VERSION ""

NS_ :

BS_:

BU_:

BO_ 2365401598 EJM7: 8 Vector__XXX
 SG_ Joystick7Button13PressedStatus : 62|2@1+ (1,0) [0|3] "" Vector__XXX
 SG_ Joystick7Button14PressedStatus : 60|2@1+ (1,0) [0|3] "" Vector__XXX
 SG_ Joystick7Button15PressedStatus : 58|2@1+ (1,0) [0|3] "" Vector__XXX
 SG_ Joystick7Button16PressedStatus : 56|2@1+ (1,0) [0|3] "" Vector__XXX
 SG_ Joystick7GripXAxisPosition : 6|10@1+ (0.1,0) [0|102] "%" Vector__XXX
 SG_ Joystick7GripYAxisPosition : 22|10@1+ (0.1,0) [0|102] "%" Vector__XXX
 SG_ Joystick7ThetaAxisPosition : 38|10@1+ (0.1,0) [0|102] "%" Vector__XXX
 SG_ Jst7GpYAxsLvFwdPstvPstStts : 20|2@1+ (1,0) [0|3] "" Vector__XXX
 SG_ Jst7TtAxsCtCwsNtvPstStts : 34|2@1+ (1,0) [0|3] "" Vector__XXX
 SG_ Jstk7GrpXAxsDtntPstnStts : 54|2@1+ (1,0) [0|3] "" Vector__XXX
 SG_ Jstk7GrpXAxsLvrLftNgtvPstnStts : 2|2@1+ (1,0) [0|3] "" Vector__XXX
 SG_ Jstk7GrpXAxsLvrRghtPstvPstnStts : 4|2@1+ (1,0) [0|3] "" Vector__XXX
 SG_ Jstk7GrpXAxsNtrlPstnStts : 0|2@1+ (1,0) [0|3] "" Vector__XXX
 SG_ Jstk7GrpYAxsDtntPstnStts : 52|2@1+ (1,0) [0|3] "" Vector__XXX
 SG_ Jstk7GrpYAxsLvrBkNgtvPstnStts : 18|2@1+ (1,0) [0|3] "" Vector__XXX
 SG_ Jstk7GrpYAxsNtrlPstnStts : 16|2@1+ (1,0) [0|3] "" Vector__XXX
 SG_ Jstk7ThtAxsClkwsPstvPstnStts : 36|2@1+ (1,0) [0|3] "" Vector__XXX
 SG_ Jstk7ThtAxsDtntPstnStts : 50|2@1+ (1,0) [0|3] "" Vector__XXX
 SG_ Jstk7ThtAxsNtrlPstnStts : 32|2@1+ (1,0) [0|3] "" Vector__XXX

BO_ 2365401854 BJM7: 8 Vector__XXX
 SG_ Joystick7Button10PressedStatus : 60|2@1+ (1,0) [0|3] "" Vector__XXX
 SG_ Joystick7Button11PressedStatus : 58|2@1+ (1,0) [0|3] "" Vector__XXX
 SG_ Joystick7Button12PressedStatus : 56|2@1+ (1,0) [0|3] "" Vector__XXX
 SG_ Joystick7Button1PressedStatus : 46|2@1+ (1,0) [0|3] "" Vector__XXX
 SG_ Joystick7Button2PressedStatus : 44|2@1+ (1,0) [0|3] "" Vector__XXX
 SG_ Joystick7Button3PressedStatus : 42|2@1+ (1,0) [0|3] "" Vector__XXX
 SG_ Joystick7Button4PressedStatus : 40|2@1+ (1,0) [0|3] "" Vector__XXX
 SG_ Joystick7Button5PressedStatus : 54|2@1+ (1,0) [0|3] "" Vector__XXX
 SG_ Joystick7Button6PressedStatus : 52|2@1+ (1,0) [0|3] "" Vector__XXX
 SG_ Joystick7Button7PressedStatus : 50|2@1+ (1,0) [0|3] "" Vector__XXX
 SG_ Joystick7Button8PressedStatus : 48|2@1+ (1,0) [0|3] "" Vector__XXX
 SG_ Joystick7Button9PressedStatus : 62|2@1+ (1,0) [0|3] "" Vector__XXX
 SG_ Joystick7XAxisPosition : 6|10@1+ (0.1,0) [0|102] "%" Vector__XXX
 SG_ Joystick7YAxisPosition : 22|10@1+ (0.1,0) [0|102] "%" Vector__XXX
 SG_ Jstk7XAxsDtntPstnStts : 38|2@1+ (1,0) [0|3] "" Vector__XXX
 SG_ Jstk7XAxsLvrLftNgtvPstnStts : 2|2@1+ (1,0) [0|3] "" Vector__XXX
 SG_ Jstk7XAxsLvrRghtPstvPstnStts : 4|2@1+ (1,0) [0|3] "" Vector__XXX
 SG_ Jstk7XAxsNtrlPstnStts : 0|2@1+ (1,0) [0|3] "" Vector__XXX
 SG_ Jstk7YAxsDtntPstnStts : 36|2@1+ (1,0) [0|3] "" Vector__XXX
 SG_ Jstk7YAxsLvrBkNgtvPstnStts : 18|2@1+ (1,0) [0|3] "" Vector__XXX
 SG_ Jstk7YAxsLvrFrwrdPstvPstnStts : 20|2@1+ (1,0) [0|3] "" Vector__XXX
 SG_ Jstk7YAxsNtrlPstnStts : 16|2@1+ (1,0) [0|3] "" Vector__XXX

BO_ 2365402110 EJM6: 8 Vector__XXX
 SG_ Joystick6Button13PressedStatus : 62|2@1+ (1,0) [0|3] "" Vector__XXX
 SG_ Joystick6Button14PressedStatus : 60|2@1+ (1,0) [0|3] "" Vector__XXX
 SG_ Joystick6Button15PressedStatus : 58|2@1+ (1,0) [0|3] "" Vector__XXX
 SG_ Joystick6Button16PressedStatus : 56|2@1+ (1,0) [0|3] "" Vector__XXX
 SG_ Joystick6GripXAxisPosition : 6|10@1+ (0.1,0) [0|102] "%" Vector__XXX
 SG_ Joystick6GripYAxisPosition : 22|10@1+ (0.1,0) [0|102] "%" Vector__XXX
 SG_ Joystick6ThetaAxisPosition : 38|10@1+ (0.1,0) [0|102] "%" Vector__XXX
 SG_ Jst6GpYAxsLvFwdPstvPstStts : 20|2@1+ (1,0) [0|3] "" Vector__XXX
 SG_ Jst6TtAxsCtCwsNtvPstStts : 34|2@1+ (1,0) [0|3] "" Vector__XXX
 SG_ Jstk6GrpXAxsDtntPstnStts : 54|2@1+ (1,0) [0|3] "" Vector__XXX
 SG_ Jstk6GrpXAxsLvrLftNgtvPstnStts : 2|2@1+ (1,0) [0|3] "" Vector__XXX
 SG_ Jstk6GrpXAxsLvrRghtPstvPstnStts : 4|2@1+ (1,0) [0|3] "" Vector__XXX
 SG_ Jstk6GrpXAxsNtrlPstnStts : 0|2@1+ (1,0) [0|3] "" Vector__XXX
 SG_ Jstk6GrpYAxsDtntPstnStts : 52|2@1+ (1,0) [0|3] "" Vector__XXX
 SG_ Jstk6GrpYAxsLvrBkNgtvPstnStts : 18|2@1+ (1,0) [0|3] "" Vector__XXX
 SG_ Jstk6GrpYAxsNtrlPstnStts : 16|2@1+ (1,0) [0|3] "" Vector__XXX
 SG_ Jstk6ThtAxsClkwsPstvPstnStts : 36|2@1+ (1,0) [0|3] "" Vector__XXX
 SG_ Jstk6ThtAxsDtntPstnStts : 50|2@1+ (1,0) [0|3] "" Vector__XXX
 SG_ Jstk6ThtAxsNtrlPstnStts : 32|2@1+ (1,0) [0|3] "" Vector__XXX

BO_ 2365402366 BJM6: 8 Vector__XXX
 SG_ Joystick6Button10PressedStatus : 60|2@1+ (1,0) [0|3] "" Vector__XXX
 SG_ Joystick6Button11PressedStatus : 58|2@1+ (1,0) [0|3] "" Vector__XXX
 SG_ Joystick6Button12PressedStatus : 56|2@1+ (1,0) [0|3] "" Vector__XXX
 SG_ Joystick6Button1PressedStatus : 46|2@1+ (1,0) [0|3] "" Vector__XXX
 SG_ Joystick6Button2PressedStatus : 44|2@1+ (1,0) [0|3] "" Vector__XXX
 SG_ Joystick6Button3PressedStatus : 42|2@1+ (1,0) [0|3] "" Vector__XXX
 SG_ Joystick6Button4PressedStatus : 40|2@1+ (1,0) [0|3] "" Vector__XXX
 SG_ Joystick6Button5PressedStatus : 54|2@1+ (1,0) [0|3] "" Vector__XXX
 SG_ Joystick6Button6PressedStatus : 52|2@1+ (1,0) [0|3] "" Vector__XXX
 SG_ Joystick6Button7PressedStatus : 50|2@1+ (1,0) [0|3] "" Vector__XXX
 SG_ Joystick6Button8PressedStatus : 48|2@1+ (1,0) [0|3] "" Vector__XXX
 SG_ Joystick6Button9PressedStatus : 62|2@1+ (1,0) [0|3] "" Vector__XXX
 SG_ Joystick6XAxisPosition : 6|10@1+ (0.1,0) [0|102] "%" Vector__XXX
 SG_ Joystick6YAxisPosition : 22|10@1+ (0.1,0) [0|102] "%" Vector__XXX
 SG_ Jstk6XAxsDtntPstnStts : 38|2@1+ (1,0) [0|3] "" Vector__XXX
 SG_ Jstk6XAxsLvrLftNgtvPstnStts : 2|2@1+ (1,0) [0|3] "" Vector__XXX
 SG_ Jstk6XAxsLvrRghtPstvPstnStts : 4|2@1+ (1,0) [0|3] "" Vector__XXX
 SG_ Jstk6XAxsNtrlPstnStts : 0|2@1+ (1,0) [0|3] "" Vector__XXX
 SG_ Jstk6YAxsDtntPstnStts : 36|2@1+ (1,0) [0|3] "" Vector__XXX
 SG_ Jstk6YAxsLvrBkNgtvPstnStts : 18|2@1+ (1,0) [0|3] "" Vector__XXX
 SG_ Jstk6YAxsLvrFrwrdPstvPstnStts : 20|2@1+ (1,0) [0|3] "" Vector__XXX
 SG_ Jstk6YAxsNtrlPstnStts : 16|2@1+ (1,0) [0|3] "" Vector__XXX

BO_ 2365402622 EJM5: 8 Vector__XXX
 SG_ Joystick5Button13PressedStatus : 62|2@1+ (1,0) [0|3] "" Vector__XXX
 SG_ Joystick5Button14PressedStatus : 60|2@1+ (1,0) [0|3] "" Vector__XXX
 SG_ Joystick5Button15PressedStatus : 58|2@1+ (1,0) [0|3] "" Vector__XXX
 SG_ Joystick5Button16PressedStatus : 56|2@1+ (1,0) [0|3] "" Vector__XXX
 SG_ Joystick5GripXAxisPosition : 6|10@1+ (0.1,0) [0|102] "%" Vector__XXX
 SG_ Joystick5GripYAxisPosition : 22|10@1+ (0.1,0) [0|102] "%" Vector__XXX
 SG_ Joystick5ThetaAxisPosition : 38|10@1+ (0.1,0) [0|102] "%" Vector__XXX
 SG_ Jst5GpYAxsLvFwdPstvPstStts : 20|2@1+ (1,0) [0|3] "" Vector__XXX
 SG_ Jst5TtAxsCtCwsNtvPstStts : 34|2@1+ (1,0) [0|3] "" Vector__XXX
 SG_ Jstk5GrpXAxsDtntPstnStts : 54|2@1+ (1,0) [0|3] "" Vector__XXX
 SG_ Jstk5GrpXAxsLvrLftNgtvPstnStts : 2|2@1+ (1,0) [0|3] "" Vector__XXX
 SG_ Jstk5GrpXAxsLvrRghtPstvPstnStts : 4|2@1+ (1,0) [0|3] "" Vector__XXX
 SG_ Jstk5GrpXAxsNtrlPstnStts : 0|2@1+ (1,0) [0|3] "" Vector__XXX
 SG_ Jstk5GrpYAxsDtntPstnStts : 52|2@1+ (1,0) [0|3] "" Vector__XXX
 SG_ Jstk5GrpYAxsLvrBkNgtvPstnStts : 18|2@1+ (1,0) [0|3] "" Vector__XXX
 SG_ Jstk5GrpYAxsNtrlPstnStts : 16|2@1+ (1,0) [0|3] "" Vector__XXX
 SG_ Jstk5ThtAxsClkwsPstvPstnStts : 36|2@1+ (1,0) [0|3] "" Vector__XXX
 SG_ Jstk5ThtAxsDtntPstnStts : 50|2@1+ (1,0) [0|3] "" Vector__XXX
 SG_ Jstk5ThtAxsNtrlPstnStts : 32|2@1+ (1,0) [0|3] "" Vector__XXX

BO_ 2365402878 BJM5: 8 Vector__XXX
 SG_ Joystick5Button10PressedStatus : 60|2@1+ (1,0) [0|3] "" Vector__XXX
 SG_ Joystick5Button11PressedStatus : 58|2@1+ (1,0) [0|3] "" Vector__XXX
 SG_ Joystick5Button12PressedStatus : 56|2@1+ (1,0) [0|3] "" Vector__XXX
 SG_ Joystick5Button1PressedStatus : 46|2@1+ (1,0) [0|3] "" Vector__XXX
 SG_ Joystick5Button2PressedStatus : 44|2@1+ (1,0) [0|3] "" Vector__XXX
 SG_ Joystick5Button3PressedStatus : 42|2@1+ (1,0) [0|3] "" Vector__XXX
 SG_ Joystick5Button4PressedStatus : 40|2@1+ (1,0) [0|3] "" Vector__XXX
 SG_ Joystick5Button5PressedStatus : 54|2@1+ (1,0) [0|3] "" Vector__XXX
 SG_ Joystick5Button6PressedStatus : 52|2@1+ (1,0) [0|3] "" Vector__XXX
 SG_ Joystick5Button7PressedStatus : 50|2@1+ (1,0) [0|3] "" Vector__XXX
 SG_ Joystick5Button8PressedStatus : 48|2@1+ (1,0) [0|3] "" Vector__XXX
 SG_ Joystick5Button9PressedStatus : 62|2@1+ (1,0) [0|3] "" Vector__XXX
 SG_ Joystick5XAxisPosition : 6|10@1+ (0.1,0) [0|102] "%" Vector__XXX
 SG_ Joystick5YAxisPosition : 22|10@1+ (0.1,0) [0|102] "%" Vector__XXX
 SG_ Jstk5XAxsDtntPstnStts : 38|2@1+ (1,0) [0|3] "" Vector__XXX
 SG_ Jstk5XAxsLvrLftNgtvPstnStts : 2|2@1+ (1,0) [0|3] "" Vector__XXX
 SG_ Jstk5XAxsLvrRghtPstvPstnStts : 4|2@1+ (1,0) [0|3] "" Vector__XXX
 SG_ Jstk5XAxsNtrlPstnStts : 0|2@1+ (1,0) [0|3] "" Vector__XXX
 SG_ Jstk5YAxsDtntPstnStts : 36|2@1+ (1,0) [0|3] "" Vector__XXX
 SG_ Jstk5YAxsLvrBkNgtvPstnStts : 18|2@1+ (1,0) [0|3] "" Vector__XXX
 SG_ Jstk5YAxsLvrFrwrdPstvPstnStts : 20|2@1+ (1,0) [0|3] "" Vector__XXX
 SG_ Jstk5YAxsNtrlPstnStts : 16|2@1+ (1,0) [0|3] "" Vector__XXX

BO_ 2365403134 EJM4: 8 Vector__XXX
 SG_ Joystick4Button13PressedStatus : 62|2@1+ (1,0) [0|3] "" Vector__XXX
 SG_ Joystick4Button14PressedStatus : 60|2@1+ (1,0) [0|3] "" Vector__XXX
 SG_ Joystick4Button15PressedStatus : 58|2@1+ (1,0) [0|3] "" Vector__XXX
 SG_ Joystick4Button16PressedStatus : 56|2@1+ (1,0) [0|3] "" Vector__XXX
 SG_ Joystick4GripXAxisPosition : 6|10@1+ (0.1,0) [0|102] "%" Vector__XXX
 SG_ Joystick4GripYAxisPosition : 22|10@1+ (0.1,0) [0|102] "%" Vector__XXX
 SG_ Joystick4ThetaAxisPosition : 38|10@1+ (0.1,0) [0|102] "%" Vector__XXX
 SG_ Jst4GpYAxsLvFwdPstvPstStts : 20|2@1+ (1,0) [0|3] "" Vector__XXX
 SG_ Jst4TtAxsCtCwsNtvPstStts : 34|2@1+ (1,0) [0|3] "" Vector__XXX
 SG_ Jstk4GrpXAxsDtntPstnStts : 54|2@1+ (1,0) [0|3] "" Vector__XXX
 SG_ Jstk4GrpXAxsLvrLftNgtvPstnStts : 2|2@1+ (1,0) [0|3] "" Vector__XXX
 SG_ Jstk4GrpXAxsLvrRghtPstvPstnStts : 4|2@1+ (1,0) [0|3] "" Vector__XXX
 SG_ Jstk4GrpXAxsNtrlPstnStts : 0|2@1+ (1,0) [0|3] "" Vector__XXX
 SG_ Jstk4GrpYAxsDtntPstnStts : 52|2@1+ (1,0) [0|3] "" Vector__XXX
 SG_ Jstk4GrpYAxsLvrBkNgtvPstnStts : 18|2@1+ (1,0) [0|3] "" Vector__XXX
 SG_ Jstk4GrpYAxsNtrlPstnStts : 16|2@1+ (1,0) [0|3] "" Vector__XXX
 SG_ Jstk4ThtAxsClkwsPstvPstnStts : 36|2@1+ (1,0) [0|3] "" Vector__XXX
 SG_ Jstk4ThtAxsDtntPstnStts : 50|2@1+ (1,0) [0|3] "" Vector__XXX
 SG_ Jstk4ThtAxsNtrlPstnStts : 32|2@1+ (1,0) [0|3] "" Vector__XXX

BO_ 2365403390 BJM4: 8 Vector__XXX
 SG_ Joystick4Button10PressedStatus : 60|2@1+ (1,0) [0|3] "" Vector__XXX
 SG_ Joystick4Button11PressedStatus : 58|2@1+ (1,0) [0|3] "" Vector__XXX
 SG_ Joystick4Button12PressedStatus : 56|2@1+ (1,0) [0|3] "" Vector__XXX
 SG_ Joystick4Button1PressedStatus : 46|2@1+ (1,0) [0|3] "" Vector__XXX
 SG_ Joystick4Button2PressedStatus : 44|2@1+ (1,0) [0|3] "" Vector__XXX
 SG_ Joystick4Button3PressedStatus : 42|2@1+ (1,0) [0|3] "" Vector__XXX
 SG_ Joystick4Button4PressedStatus : 40|2@1+ (1,0) [0|3] "" Vector__XXX
 SG_ Joystick4Button5PressedStatus : 54|2@1+ (1,0) [0|3] "" Vector__XXX
 SG_ Joystick4Button6PressedStatus : 52|2@1+ (1,0) [0|3] "" Vector__XXX
 SG_ Joystick4Button7PressedStatus : 50|2@1+ (1,0) [0|3] "" Vector__XXX
 SG_ Joystick4Button8PressedStatus : 48|2@1+ (1,0) [0|3] "" Vector__XXX
 SG_ Joystick4Button9PressedStatus : 62|2@1+ (1,0) [0|3] "" Vector__XXX
 SG_ Joystick4XAxisPosition : 6|10@1+ (0.1,0) [0|102] "%" Vector__XXX
 SG_ Joystick4YAxisPosition : 22|10@1+ (0.1,0) [0|102] "%" Vector__XXX
 SG_ Jstk4XAxsDtntPstnStts : 38|2@1+ (1,0) [0|3] "" Vector__XXX
 SG_ Jstk4XAxsLvrLftNgtvPstnStts : 2|2@1+ (1,0) [0|3] "" Vector__XXX
 SG_ Jstk4XAxsLvrRghtPstvPstnStts : 4|2@1+ (1,0) [0|3] "" Vector__XXX
 SG_ Jstk4XAxsNtrlPstnStts : 0|2@1+ (1,0) [0|3] "" Vector__XXX
 SG_ Jstk4YAxsDtntPstnStts : 36|2@1+ (1,0) [0|3] "" Vector__XXX
 SG_ Jstk4YAxsLvrBkNgtvPstnStts : 18|2@1+ (1,0) [0|3] "" Vector__XXX
 SG_ Jstk4YAxsLvrFrwrdPstvPstnStts : 20|2@1+ (1,0) [0|3] "" Vector__XXX
 SG_ Jstk4YAxsNtrlPstnStts : 16|2@1+ (1,0) [0|3] "" Vector__XXX

BO_ 2365428478 EOI: 8 Vector__XXX
 SG_ EngineControlledShutdownRequest : 42|2@1+ (1,0) [0|3] "" Vector__XXX
 SG_ EngineCoolantPumpControl : 40|2@1+ (1,0) [0|3] "" Vector__XXX
 SG_ EngineDerateRequest : 56|8@1+ (0.4,0) [0|100] "%" Vector__XXX
 SG_ EngineDesiredTorqueRequest : 48|8@1+ (1,-125) [-125|125] "%" Vector__XXX
 SG_ EngineFuelShutoff1Control : 26|2@1+ (1,0) [0|3] "" Vector__XXX
 SG_ EngineFuelShutoff2Control : 28|2@1+ (1,0) [0|3] "" Vector__XXX
 SG_ EngineFuelShutoffVentControl : 24|2@1+ (1,0) [0|3] "" Vector__XXX
 SG_ EngineOilPreheaterControl : 34|2@1+ (1,0) [0|3] "" Vector__XXX
 SG_ EngineOilPrimingPumpControl : 32|2@1+ (1,0) [0|3] "" Vector__XXX
 SG_ EngineOperatingState : 0|4@1+ (1,0) [0|15] "" Vector__XXX
 SG_ EnginePreHeaterControl : 38|2@1+ (1,0) [0|3] "" Vector__XXX
 SG_ EngineStarterMotorRelayControl : 6|2@1+ (1,0) [0|3] "" Vector__XXX
 SG_ EngnCldAmntElvtdIdlStts : 46|2@1+ (1,0) [0|3] "" Vector__XXX
 SG_ EngnEltrlSstmPwrCnsrvtnCntrl : 36|2@1+ (1,0) [0|3] "" Vector__XXX
 SG_ EngnEmrgnImmdtShtdwnIndtn : 44|2@1+ (1,0) [0|3] "" Vector__XXX
 SG_ EngnFlShtffVlvLkTstCntrl : 30|2@1+ (1,0) [0|3] "" Vector__XXX
 SG_ FuelPumpPrimerControl : 4|2@1+ (1,0) [0|3] "" Vector__XXX
 SG_ TmRmnngnEngnOprtngStt : 8|16@1+ (1,0) [0|64255] "s" Vector__XXX

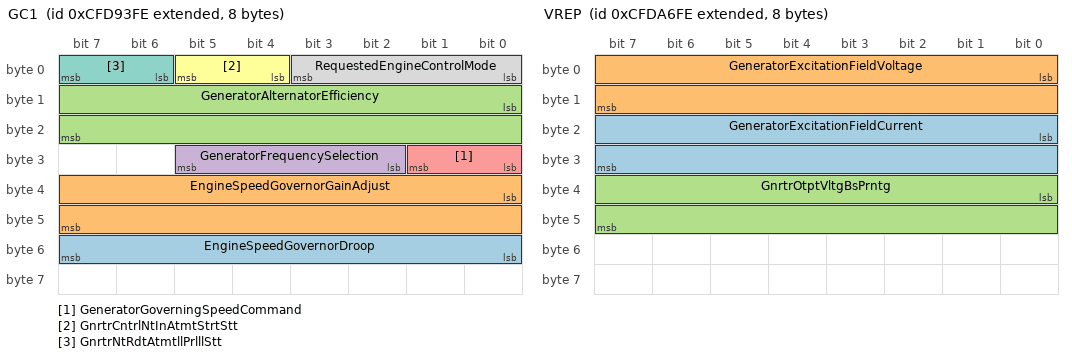
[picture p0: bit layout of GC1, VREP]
BO_ 2365428734 GC1: 8 Vector__XXX
 SG_ EngineSpeedGovernorDroop : 48|8@1+ (0.04,0) [0|10] "%" Vector__XXX
 SG_ EngineSpeedGovernorGainAdjust : 32|16@1+ (1,-32128) [-32128|32127] "count" Vector__XXX
 SG_ GeneratorAlternatorEfficiency : 8|16@1+ (0.0025,0) [0|160.6375] "%" Vector__XXX
 SG_ GeneratorFrequencySelection : 26|4@1+ (1,0) [0|15] "" Vector__XXX
 SG_ GeneratorGoverningSpeedCommand : 24|2@1+ (1,0) [0|3] "" Vector__XXX
 SG_ GnrtrCntrlNtInAtmtStrtStt : 4|2@1+ (1,0) [0|3] "" Vector__XXX
 SG_ GnrtrNtRdtAtmtllPrlllStt : 6|2@1+ (1,0) [0|3] "" Vector__XXX
 SG_ RequestedEngineControlMode : 0|4@1+ (1,0) [0|15] "" Vector__XXX

BO_ 2365433598 VREP: 8 Vector__XXX
 SG_ GeneratorExcitationFieldCurrent : 16|16@1+ (0.05,0) [0|3212.75] "A" Vector__XXX
 SG_ GeneratorExcitationFieldVoltage : 0|16@1+ (0.05,-1606) [-1606|1606.75] "V" Vector__XXX
 SG_ GnrtrOtptVltgBsPrntg : 32|16@1+ (0.1,-100) [-100|100] "%" Vector__XXX

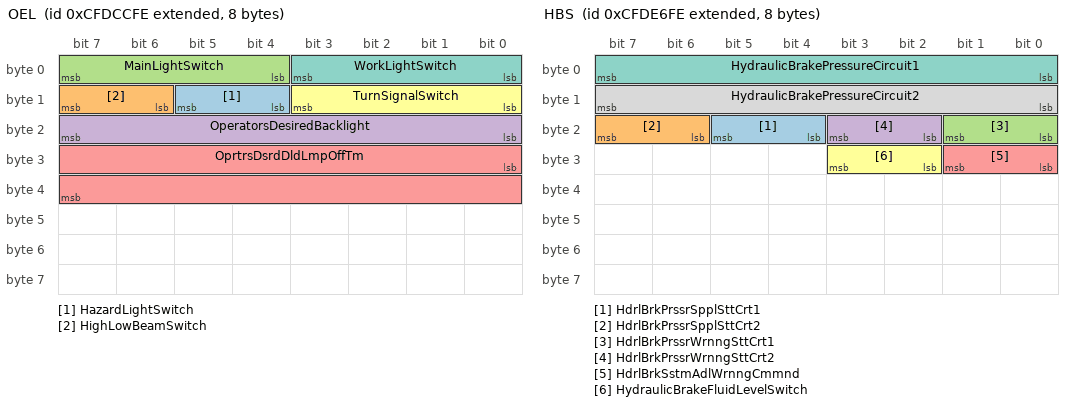
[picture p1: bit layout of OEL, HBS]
BO_ 2365443326 OEL: 8 Vector__XXX
 SG_ HazardLightSwitch : 12|2@1+ (1,0) [0|3] "" Vector__XXX
 SG_ HighLowBeamSwitch : 14|2@1+ (1,0) [0|3] "" Vector__XXX
 SG_ MainLightSwitch : 4|4@1+ (1,0) [0|15] "" Vector__XXX
 SG_ OperatorsDesiredBacklight : 16|8@1+ (0.4,0) [0|100] "%" Vector__XXX
 SG_ OprtrsDsrdDldLmpOffTm : 24|16@1+ (1,0) [0|64255] "s" Vector__XXX
 SG_ TurnSignalSwitch : 8|4@1+ (1,0) [0|15] "" Vector__XXX
 SG_ WorkLightSwitch : 0|4@1+ (1,0) [0|15] "" Vector__XXX

BO_ 2365445886 BJM1: 8 Vector__XXX
 SG_ Joystick1Button10PressedStatus : 60|2@1+ (1,0) [0|3] "" Vector__XXX
 SG_ Joystick1Button11PressedStatus : 58|2@1+ (1,0) [0|3] "" Vector__XXX
 SG_ Joystick1Button12PressedStatus : 56|2@1+ (1,0) [0|3] "" Vector__XXX
 SG_ Joystick1Button1PressedStatus : 46|2@1+ (1,0) [0|3] "" Vector__XXX
 SG_ Joystick1Button2PressedStatus : 44|2@1+ (1,0) [0|3] "" Vector__XXX
 SG_ Joystick1Button3PressedStatus : 42|2@1+ (1,0) [0|3] "" Vector__XXX
 SG_ Joystick1Button4PressedStatus : 40|2@1+ (1,0) [0|3] "" Vector__XXX
 SG_ Joystick1Button5PressedStatus : 54|2@1+ (1,0) [0|3] "" Vector__XXX
 SG_ Joystick1Button6PressedStatus : 52|2@1+ (1,0) [0|3] "" Vector__XXX
 SG_ Joystick1Button7PressedStatus : 50|2@1+ (1,0) [0|3] "" Vector__XXX
 SG_ Joystick1Button8PressedStatus : 48|2@1+ (1,0) [0|3] "" Vector__XXX
 SG_ Joystick1Button9PressedStatus : 62|2@1+ (1,0) [0|3] "" Vector__XXX
 SG_ Joystick1XAxisPosition : 6|10@1+ (0.1,0) [0|102] "%" Vector__XXX
 SG_ Joystick1YAxisPosition : 22|10@1+ (0.1,0) [0|102] "%" Vector__XXX
 SG_ Jstk1XAxsDtntPstnStts : 38|2@1+ (1,0) [0|3] "" Vector__XXX
 SG_ Jstk1XAxsLvrLftNgtvPstnStts : 2|2@1+ (1,0) [0|3] "" Vector__XXX
 SG_ Jstk1XAxsLvrRghtPstvPstnStts : 4|2@1+ (1,0) [0|3] "" Vector__XXX
 SG_ Jstk1XAxsNtrlPstnStts : 0|2@1+ (1,0) [0|3] "" Vector__XXX
 SG_ Jstk1YAxsDtntPstnStts : 36|2@1+ (1,0) [0|3] "" Vector__XXX
 SG_ Jstk1YAxsLvrBkNgtvPstnStts : 18|2@1+ (1,0) [0|3] "" Vector__XXX
 SG_ Jstk1YAxsLvrFrwrdPstvPstnStts : 20|2@1+ (1,0) [0|3] "" Vector__XXX
 SG_ Jstk1YAxsNtrlPstnStts : 16|2@1+ (1,0) [0|3] "" Vector__XXX

BO_ 2365446142 EJM1: 8 Vector__XXX
 SG_ Joystick1Button13PressedStatus : 62|2@1+ (1,0) [0|3] "" Vector__XXX
 SG_ Joystick1Button14PressedStatus : 60|2@1+ (1,0) [0|3] "" Vector__XXX
 SG_ Joystick1Button15PressedStatus : 58|2@1+ (1,0) [0|3] "" Vector__XXX
 SG_ Joystick1Button16PressedStatus : 56|2@1+ (1,0) [0|3] "" Vector__XXX
 SG_ Joystick1GripXAxisPosition : 6|10@1+ (0.1,0) [0|102] "%" Vector__XXX
 SG_ Joystick1GripYAxisPosition : 22|10@1+ (0.1,0) [0|102] "%" Vector__XXX
 SG_ Joystick1ThetaAxisPosition : 38|10@1+ (0.1,0) [0|102] "%" Vector__XXX
 SG_ Jst1GpYAxsLvFwdPstvPstStts : 20|2@1+ (1,0) [0|3] "" Vector__XXX
 SG_ Jst1TtAxsCtCwsNtvPstStts : 34|2@1+ (1,0) [0|3] "" Vector__XXX
 SG_ Jstk1GrpXAxsDtntPstnStts : 54|2@1+ (1,0) [0|3] "" Vector__XXX
 SG_ Jstk1GrpXAxsLvrLftNgtvPstnStts : 2|2@1+ (1,0) [0|3] "" Vector__XXX
 SG_ Jstk1GrpXAxsLvrRghtPstvPstnStts : 4|2@1+ (1,0) [0|3] "" Vector__XXX
 SG_ Jstk1GrpXAxsNtrlPstnStts : 0|2@1+ (1,0) [0|3] "" Vector__XXX
 SG_ Jstk1GrpYAxsDtntPstnStts : 52|2@1+ (1,0) [0|3] "" Vector__XXX
 SG_ Jstk1GrpYAxsLvrBkNgtvPstnStts : 18|2@1+ (1,0) [0|3] "" Vector__XXX
 SG_ Jstk1GrpYAxsNtrlPstnStts : 16|2@1+ (1,0) [0|3] "" Vector__XXX
 SG_ Jstk1ThtAxsClkwsPstvPstnStts : 36|2@1+ (1,0) [0|3] "" Vector__XXX
 SG_ Jstk1ThtAxsDtntPstnStts : 50|2@1+ (1,0) [0|3] "" Vector__XXX
 SG_ Jstk1ThtAxsNtrlPstnStts : 32|2@1+ (1,0) [0|3] "" Vector__XXX

BO_ 2365446398 BJM2: 8 Vector__XXX
 SG_ Joystick2Button10PressedStatus : 60|2@1+ (1,0) [0|3] "" Vector__XXX
 SG_ Joystick2Button11PressedStatus : 58|2@1+ (1,0) [0|3] "" Vector__XXX
 SG_ Joystick2Button12PressedStatus : 56|2@1+ (1,0) [0|3] "" Vector__XXX
 SG_ Joystick2Button1PressedStatus : 46|2@1+ (1,0) [0|3] "" Vector__XXX
 SG_ Joystick2Button2PressedStatus : 44|2@1+ (1,0) [0|3] "" Vector__XXX
 SG_ Joystick2Button3PressedStatus : 42|2@1+ (1,0) [0|3] "" Vector__XXX
 SG_ Joystick2Button4PressedStatus : 40|2@1+ (1,0) [0|3] "" Vector__XXX
 SG_ Joystick2Button5PressedStatus : 54|2@1+ (1,0) [0|3] "" Vector__XXX
 SG_ Joystick2Button6PressedStatus : 52|2@1+ (1,0) [0|3] "" Vector__XXX
 SG_ Joystick2Button7PressedStatus : 50|2@1+ (1,0) [0|3] "" Vector__XXX
 SG_ Joystick2Button8PressedStatus : 48|2@1+ (1,0) [0|3] "" Vector__XXX
 SG_ Joystick2Button9PressedStatus : 62|2@1+ (1,0) [0|3] "" Vector__XXX
 SG_ Joystick2XAxisPosition : 6|10@1+ (0.1,0) [0|102] "%" Vector__XXX
 SG_ Joystick2YAxisPosition : 22|10@1+ (0.1,0) [0|102] "%" Vector__XXX
 SG_ Jstk2XAxsDtntPstnStts : 38|2@1+ (1,0) [0|3] "" Vector__XXX
 SG_ Jstk2XAxsLvrLftNgtvPstnStts : 2|2@1+ (1,0) [0|3] "" Vector__XXX
 SG_ Jstk2XAxsLvrRghtPstvPstnStts : 4|2@1+ (1,0) [0|3] "" Vector__XXX
 SG_ Jstk2XAxsNtrlPstnStts : 0|2@1+ (1,0) [0|3] "" Vector__XXX
 SG_ Jstk2YAxsDtntPstnStts : 36|2@1+ (1,0) [0|3] "" Vector__XXX
 SG_ Jstk2YAxsLvrBkNgtvPstnStts : 18|2@1+ (1,0) [0|3] "" Vector__XXX
 SG_ Jstk2YAxsLvrFrwrdPstvPstnStts : 20|2@1+ (1,0) [0|3] "" Vector__XXX
 SG_ Jstk2YAxsNtrlPstnStts : 16|2@1+ (1,0) [0|3] "" Vector__XXX

BO_ 2365446654 EJM2: 8 Vector__XXX
 SG_ Joystick2Button13PressedStatus : 62|2@1+ (1,0) [0|3] "" Vector__XXX
 SG_ Joystick2Button14PressedStatus : 60|2@1+ (1,0) [0|3] "" Vector__XXX
 SG_ Joystick2Button15PressedStatus : 58|2@1+ (1,0) [0|3] "" Vector__XXX
 SG_ Joystick2Button16PressedStatus : 56|2@1+ (1,0) [0|3] "" Vector__XXX
 SG_ Joystick2GripXAxisPosition : 6|10@1+ (0.1,0) [0|102] "%" Vector__XXX
 SG_ Joystick2GripYAxisPosition : 22|10@1+ (0.1,0) [0|102] "%" Vector__XXX
 SG_ Joystick2ThetaAxisPosition : 38|10@1+ (0.1,0) [0|102] "%" Vector__XXX
 SG_ Jst2GpYAxsLvFwdPstvPstStts : 20|2@1+ (1,0) [0|3] "" Vector__XXX
 SG_ Jst2TtAxsCtCwsNtvPstStts : 34|2@1+ (1,0) [0|3] "" Vector__XXX
 SG_ Jstk2GrpXAxsDtntPstnStts : 54|2@1+ (1,0) [0|3] "" Vector__XXX
 SG_ Jstk2GrpXAxsLvrLftNgtvPstnStts : 2|2@1+ (1,0) [0|3] "" Vector__XXX
 SG_ Jstk2GrpXAxsLvrRghtPstvPstnStts : 4|2@1+ (1,0) [0|3] "" Vector__XXX
 SG_ Jstk2GrpXAxsNtrlPstnStts : 0|2@1+ (1,0) [0|3] "" Vector__XXX
 SG_ Jstk2GrpYAxsDtntPstnStts : 52|2@1+ (1,0) [0|3] "" Vector__XXX
 SG_ Jstk2GrpYAxsLvrBkNgtvPstnStts : 18|2@1+ (1,0) [0|3] "" Vector__XXX
 SG_ Jstk2GrpYAxsNtrlPstnStts : 16|2@1+ (1,0) [0|3] "" Vector__XXX
 SG_ Jstk2ThtAxsClkwsPstvPstnStts : 36|2@1+ (1,0) [0|3] "" Vector__XXX
 SG_ Jstk2ThtAxsDtntPstnStts : 50|2@1+ (1,0) [0|3] "" Vector__XXX
 SG_ Jstk2ThtAxsNtrlPstnStts : 32|2@1+ (1,0) [0|3] "" Vector__XXX

BO_ 2365446910 BJM3: 8 Vector__XXX
 SG_ Joystick3Button10PressedStatus : 60|2@1+ (1,0) [0|3] "" Vector__XXX
 SG_ Joystick3Button11PressedStatus : 58|2@1+ (1,0) [0|3] "" Vector__XXX
 SG_ Joystick3Button12PressedStatus : 56|2@1+ (1,0) [0|3] "" Vector__XXX
 SG_ Joystick3Button1PressedStatus : 46|2@1+ (1,0) [0|3] "" Vector__XXX
 SG_ Joystick3Button2PressedStatus : 44|2@1+ (1,0) [0|3] "" Vector__XXX
 SG_ Joystick3Button3PressedStatus : 42|2@1+ (1,0) [0|3] "" Vector__XXX
 SG_ Joystick3Button4PressedStatus : 40|2@1+ (1,0) [0|3] "" Vector__XXX
 SG_ Joystick3Button5PressedStatus : 54|2@1+ (1,0) [0|3] "" Vector__XXX
 SG_ Joystick3Button6PressedStatus : 52|2@1+ (1,0) [0|3] "" Vector__XXX
 SG_ Joystick3Button7PressedStatus : 50|2@1+ (1,0) [0|3] "" Vector__XXX
 SG_ Joystick3Button8PressedStatus : 48|2@1+ (1,0) [0|3] "" Vector__XXX
 SG_ Joystick3Button9PressedStatus : 62|2@1+ (1,0) [0|3] "" Vector__XXX
 SG_ Joystick3XAxisPosition : 6|10@1+ (0.1,0) [0|102] "%" Vector__XXX
 SG_ Joystick3YAxisPosition : 22|10@1+ (0.1,0) [0|102] "%" Vector__XXX
 SG_ Jstk3XAxsDtntPstnStts : 38|2@1+ (1,0) [0|3] "" Vector__XXX
 SG_ Jstk3XAxsLvrLftNgtvPstnStts : 2|2@1+ (1,0) [0|3] "" Vector__XXX
 SG_ Jstk3XAxsLvrRghtPstvPstnStts : 4|2@1+ (1,0) [0|3] "" Vector__XXX
 SG_ Jstk3XAxsNtrlPstnStts : 0|2@1+ (1,0) [0|3] "" Vector__XXX
 SG_ Jstk3YAxsDtntPstnStts : 36|2@1+ (1,0) [0|3] "" Vector__XXX
 SG_ Jstk3YAxsLvrBkNgtvPstnStts : 18|2@1+ (1,0) [0|3] "" Vector__XXX
 SG_ Jstk3YAxsLvrFrwrdPstvPstnStts : 20|2@1+ (1,0) [0|3] "" Vector__XXX
 SG_ Jstk3YAxsNtrlPstnStts : 16|2@1+ (1,0) [0|3] "" Vector__XXX

BO_ 2365447166 EJM3: 8 Vector__XXX
 SG_ Joystick3Button13PressedStatus : 62|2@1+ (1,0) [0|3] "" Vector__XXX
 SG_ Joystick3Button14PressedStatus : 60|2@1+ (1,0) [0|3] "" Vector__XXX
 SG_ Joystick3Button15PressedStatus : 58|2@1+ (1,0) [0|3] "" Vector__XXX
 SG_ Joystick3Button16PressedStatus : 56|2@1+ (1,0) [0|3] "" Vector__XXX
 SG_ Joystick3GripXAxisPosition : 6|10@1+ (0.1,0) [0|102] "%" Vector__XXX
 SG_ Joystick3GripYAxisPosition : 22|10@1+ (0.1,0) [0|102] "%" Vector__XXX
 SG_ Joystick3ThetaAxisPosition : 38|10@1+ (0.1,0) [0|102] "%" Vector__XXX
 SG_ Jst3GpYAxsLvFwdPstvPstStts : 20|2@1+ (1,0) [0|3] "" Vector__XXX
 SG_ Jst3TtAxsCtCwsNtvPstStts : 34|2@1+ (1,0) [0|3] "" Vector__XXX
 SG_ Jstk3GrpXAxsDtntPstnStts : 54|2@1+ (1,0) [0|3] "" Vector__XXX
 SG_ Jstk3GrpXAxsLvrLftNgtvPstnStts : 2|2@1+ (1,0) [0|3] "" Vector__XXX
 SG_ Jstk3GrpXAxsLvrRghtPstvPstnStts : 4|2@1+ (1,0) [0|3] "" Vector__XXX
 SG_ Jstk3GrpXAxsNtrlPstnStts : 0|2@1+ (1,0) [0|3] "" Vector__XXX
 SG_ Jstk3GrpYAxsDtntPstnStts : 52|2@1+ (1,0) [0|3] "" Vector__XXX
 SG_ Jstk3GrpYAxsLvrBkNgtvPstnStts : 18|2@1+ (1,0) [0|3] "" Vector__XXX
 SG_ Jstk3GrpYAxsNtrlPstnStts : 16|2@1+ (1,0) [0|3] "" Vector__XXX
 SG_ Jstk3ThtAxsClkwsPstvPstnStts : 36|2@1+ (1,0) [0|3] "" Vector__XXX
 SG_ Jstk3ThtAxsDtntPstnStts : 50|2@1+ (1,0) [0|3] "" Vector__XXX
 SG_ Jstk3ThtAxsNtrlPstnStts : 32|2@1+ (1,0) [0|3] "" Vector__XXX

BO_ 2365449982 HBS: 8 Vector__XXX
 SG_ HdrlBrkPrssrSpplSttCrt1 : 20|2@1+ (1,0) [0|3] "" Vector__XXX
 SG_ HdrlBrkPrssrSpplSttCrt2 : 22|2@1+ (1,0) [0|3] "" Vector__XXX
 SG_ HdrlBrkPrssrWrnngSttCrt1 : 16|2@1+ (1,0) [0|3] "" Vector__XXX
 SG_ HdrlBrkPrssrWrnngSttCrt2 : 18|2@1+ (1,0) [0|3] "" Vector__XXX
 SG_ HdrlBrkSstmAdlWrnngCmmnd : 24|2@1+ (1,0) [0|3] "" Vector__XXX
 SG_ HydraulicBrakeFluidLevelSwitch : 26|2@1+ (1,0) [0|3] "" Vector__XXX
 SG_ HydraulicBrakePressureCircuit1 : 0|8@1+ (100,0) [0|25000] "kPa" Vector__XXX
 SG_ HydraulicBrakePressureCircuit2 : 8|8@1+ (100,0) [0|25000] "kPa" Vector__XXX

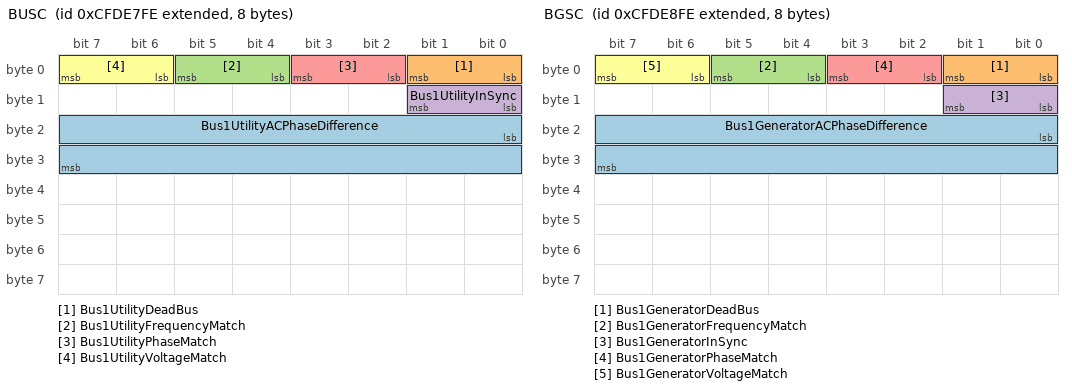
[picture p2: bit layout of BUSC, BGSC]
BO_ 2365450238 BUSC: 8 Vector__XXX
 SG_ Bus1UtilityACPhaseDifference : 16|16@1+ (0.0078125,-200) [-200|301.99] "deg" Vector__XXX
 SG_ Bus1UtilityDeadBus : 0|2@1+ (1,0) [0|3] "" Vector__XXX
 SG_ Bus1UtilityFrequencyMatch : 4|2@1+ (1,0) [0|3] "" Vector__XXX
 SG_ Bus1UtilityInSync : 8|2@1+ (1,0) [0|3] "" Vector__XXX
 SG_ Bus1UtilityPhaseMatch : 2|2@1+ (1,0) [0|3] "" Vector__XXX
 SG_ Bus1UtilityVoltageMatch : 6|2@1+ (1,0) [0|3] "" Vector__XXX

BO_ 2365450494 BGSC: 8 Vector__XXX
 SG_ Bus1GeneratorACPhaseDifference : 16|16@1+ (0.0078125,-200) [-200|301.99] "deg" Vector__XXX
 SG_ Bus1GeneratorDeadBus : 0|2@1+ (1,0) [0|3] "" Vector__XXX
 SG_ Bus1GeneratorFrequencyMatch : 4|2@1+ (1,0) [0|3] "" Vector__XXX
 SG_ Bus1GeneratorInSync : 8|2@1+ (1,0) [0|3] "" Vector__XXX
 SG_ Bus1GeneratorPhaseMatch : 2|2@1+ (1,0) [0|3] "" Vector__XXX
 SG_ Bus1GeneratorVoltageMatch : 6|2@1+ (1,0) [0|3] "" Vector__XXX

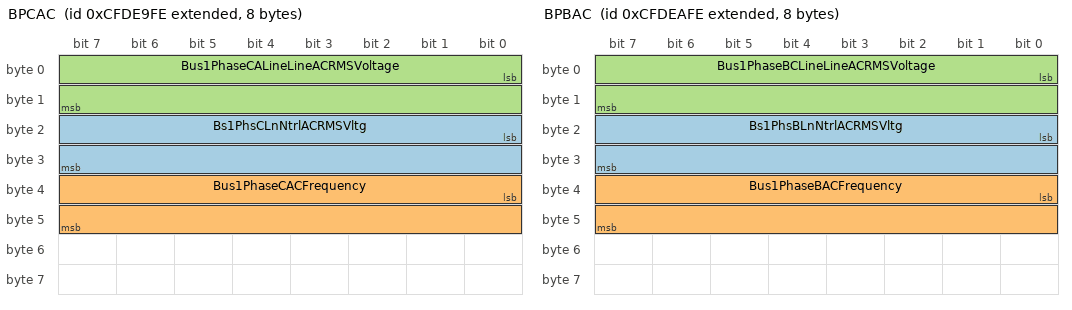
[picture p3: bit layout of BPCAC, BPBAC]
BO_ 2365450750 BPCAC: 8 Vector__XXX
 SG_ Bs1PhsCLnNtrlACRMSVltg : 16|16@1+ (1,0) [0|64255] "V" Vector__XXX
 SG_ Bus1PhaseCACFrequency : 32|16@1+ (0.0078125,0) [0|501.9921875] "Hz" Vector__XXX
 SG_ Bus1PhaseCALineLineACRMSVoltage : 0|16@1+ (1,0) [0|64255] "V" Vector__XXX

BO_ 2365451006 BPBAC: 8 Vector__XXX
 SG_ Bs1PhsBLnNtrlACRMSVltg : 16|16@1+ (1,0) [0|64255] "V" Vector__XXX
 SG_ Bus1PhaseBACFrequency : 32|16@1+ (0.0078125,0) [0|501.9921875] "Hz" Vector__XXX
 SG_ Bus1PhaseBCLineLineACRMSVoltage : 0|16@1+ (1,0) [0|64255] "V" Vector__XXX

BO_ 2365451262 BPAAC: 8 Vector__XXX
 SG_ Bs1PhsALnNtrlACRMSVltg : 16|16@1+ (1,0) [0|64255] "V" Vector__XXX
 SG_ Bus1PhaseAACFrequency : 32|16@1+ (0.0078125,0) [0|501.9921875] "Hz" Vector__XXX
 SG_ Bus1PhaseABLineLineACRMSVoltage : 0|16@1+ (1,0) [0|64255] "V" Vector__XXX

BO_ 2365451518 BAAC: 8 Vector__XXX
 SG_ Bs1AvrgLnNtrlACRMSVltg : 16|16@1+ (1,0) [0|64255] "V" Vector__XXX
 SG_ Bus1AverageACFrequency : 32|16@1+ (0.0078125,0) [0|501.9921875] "Hz" Vector__XXX
 SG_ Bus1AverageLineLineACRMSVoltage : 0|16@1+ (1,0) [0|64255] "V" Vector__XXX

BO_ 2365451774 UTACE: 8 Vector__XXX
 SG_ UtilityTotalkWHoursExport : 0|32@1+ (1,0) [0|4.21108E+09] "kWh" Vector__XXX
 SG_ UtilityTotalkWHoursImport : 32|32@1+ (1,0) [0|4.21108E+09] "kWh" Vector__XXX

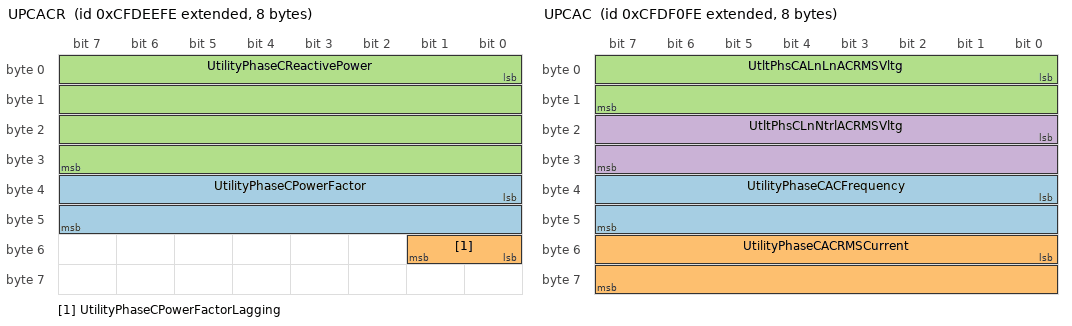
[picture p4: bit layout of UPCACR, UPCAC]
BO_ 2365452030 UPCACR: 8 Vector__XXX
 SG_ UtilityPhaseCPowerFactor : 32|16@1+ (0.00006103515625,-1) [-1|2.921814] "" Vector__XXX
 SG_ UtilityPhaseCPowerFactorLagging : 48|2@1+ (1,0) [0|3] "" Vector__XXX
 SG_ UtilityPhaseCReactivePower : 0|32@1+ (1,-2000000000) [-2000000000|2.21108E+09] "VAr" Vector__XXX

BO_ 2365452286 UPCACP: 8 Vector__XXX
 SG_ UtilityPhaseCApparentPower : 32|32@1+ (1,-2000000000) [-2000000000|2.21108E+09] "VA" Vector__XXX
 SG_ UtilityPhaseCRealPower : 0|32@1+ (1,-2000000000) [-2000000000|2.21108E+09] "W" Vector__XXX

BO_ 2365452542 UPCAC: 8 Vector__XXX
 SG_ UtilityPhaseCACFrequency : 32|16@1+ (0.0078125,0) [0|501.9921875] "Hz" Vector__XXX
 SG_ UtilityPhaseCACRMSCurrent : 48|16@1+ (1,0) [0|64255] "A" Vector__XXX
 SG_ UtltPhsCALnLnACRMSVltg : 0|16@1+ (1,0) [0|64255] "V" Vector__XXX
 SG_ UtltPhsCLnNtrlACRMSVltg : 16|16@1+ (1,0) [0|64255] "V" Vector__XXX

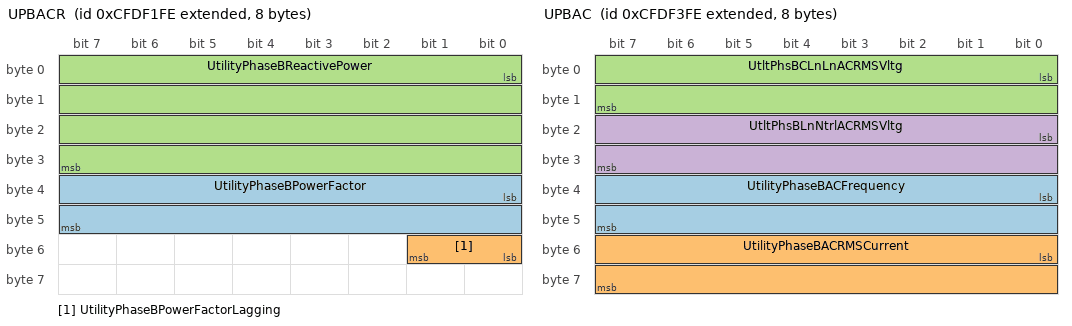
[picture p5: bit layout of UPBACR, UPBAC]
BO_ 2365452798 UPBACR: 8 Vector__XXX
 SG_ UtilityPhaseBPowerFactor : 32|16@1+ (0.00006103515625,-1) [-1|2.921814] "" Vector__XXX
 SG_ UtilityPhaseBPowerFactorLagging : 48|2@1+ (1,0) [0|3] "" Vector__XXX
 SG_ UtilityPhaseBReactivePower : 0|32@1+ (1,-2000000000) [-2000000000|2.21108E+09] "VAr" Vector__XXX

BO_ 2365453054 UPBACP: 8 Vector__XXX
 SG_ UtilityPhaseBApparentPower : 32|32@1+ (1,-2000000000) [-2000000000|2.21108E+09] "VA" Vector__XXX
 SG_ UtilityPhaseBRealPower : 0|32@1+ (1,-2000000000) [-2000000000|2.21108E+09] "W" Vector__XXX

BO_ 2365453310 UPBAC: 8 Vector__XXX
 SG_ UtilityPhaseBACFrequency : 32|16@1+ (0.0078125,0) [0|501.9921875] "Hz" Vector__XXX
 SG_ UtilityPhaseBACRMSCurrent : 48|16@1+ (1,0) [0|64255] "A" Vector__XXX
 SG_ UtltPhsBCLnLnACRMSVltg : 0|16@1+ (1,0) [0|64255] "V" Vector__XXX
 SG_ UtltPhsBLnNtrlACRMSVltg : 16|16@1+ (1,0) [0|64255] "V" Vector__XXX

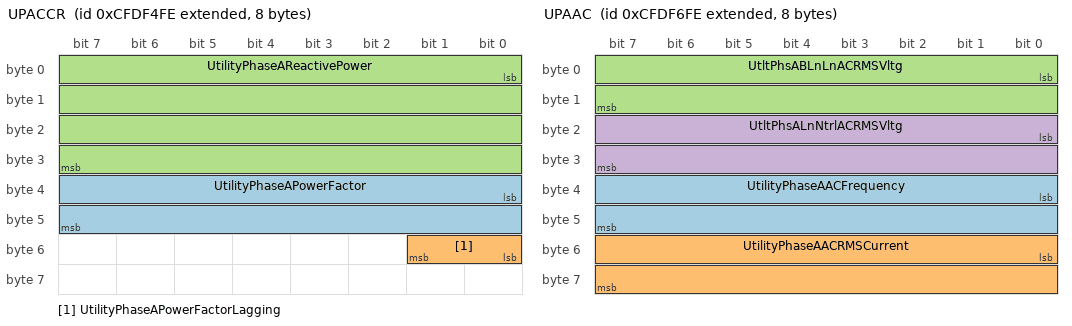
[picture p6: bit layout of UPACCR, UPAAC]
BO_ 2365453566 UPACCR: 8 Vector__XXX
 SG_ UtilityPhaseAPowerFactor : 32|16@1+ (0.00006103515625,-1) [-1|2.921814] "" Vector__XXX
 SG_ UtilityPhaseAPowerFactorLagging : 48|2@1+ (1,0) [0|3] "" Vector__XXX
 SG_ UtilityPhaseAReactivePower : 0|32@1+ (1,-2000000000) [-2000000000|2.21108E+09] "VAr" Vector__XXX

BO_ 2365453822 UPAACP: 8 Vector__XXX
 SG_ UtilityPhaseAApparentPower : 32|32@1+ (1,-2000000000) [-2000000000|2.21108E+09] "VA" Vector__XXX
 SG_ UtilityPhaseARealPower : 0|32@1+ (1,-2000000000) [-2000000000|2.21108E+09] "W" Vector__XXX

BO_ 2365454078 UPAAC: 8 Vector__XXX
 SG_ UtilityPhaseAACFrequency : 32|16@1+ (0.0078125,0) [0|501.9921875] "Hz" Vector__XXX
 SG_ UtilityPhaseAACRMSCurrent : 48|16@1+ (1,0) [0|64255] "A" Vector__XXX
 SG_ UtltPhsABLnLnACRMSVltg : 0|16@1+ (1,0) [0|64255] "V" Vector__XXX
 SG_ UtltPhsALnNtrlACRMSVltg : 16|16@1+ (1,0) [0|64255] "V" Vector__XXX

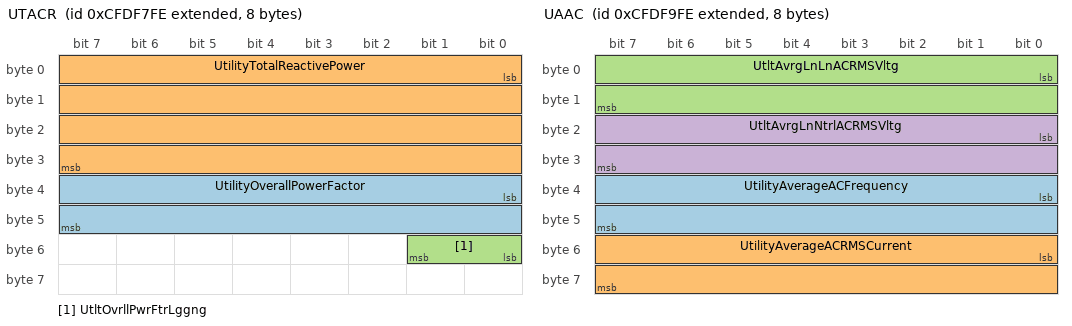
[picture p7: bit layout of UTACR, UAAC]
BO_ 2365454334 UTACR: 8 Vector__XXX
 SG_ UtilityOverallPowerFactor : 32|16@1+ (0.00006103515625,-1) [-1|2.921814] "" Vector__XXX
 SG_ UtilityTotalReactivePower : 0|32@1+ (1,-2000000000) [-2000000000|2.21108E+09] "VAr" Vector__XXX
 SG_ UtltOvrllPwrFtrLggng : 48|2@1+ (1,0) [0|3] "" Vector__XXX

BO_ 2365454590 UTACP: 8 Vector__XXX
 SG_ UtilityTotalApparentPower : 32|32@1+ (1,-2000000000) [-2000000000|2.21108E+09] "VA" Vector__XXX
 SG_ UtilityTotalRealPower : 0|32@1+ (1,-2000000000) [-2000000000|2.21108E+09] "W" Vector__XXX

BO_ 2365454846 UAAC: 8 Vector__XXX
 SG_ UtilityAverageACFrequency : 32|16@1+ (0.0078125,0) [0|501.9921875] "Hz" Vector__XXX
 SG_ UtilityAverageACRMSCurrent : 48|16@1+ (1,0) [0|64255] "A" Vector__XXX
 SG_ UtltAvrgLnLnACRMSVltg : 0|16@1+ (1,0) [0|64255] "V" Vector__XXX
 SG_ UtltAvrgLnNtrlACRMSVltg : 16|16@1+ (1,0) [0|64255] "V" Vector__XXX

BO_ 2365455102 GTACE: 8 Vector__XXX
 SG_ GeneratorTotalkWHoursExport : 0|32@1+ (1,0) [0|4.21108E+09] "kWh" Vector__XXX
 SG_ GeneratorTotalkWHoursImport : 32|32@1+ (1,0) [0|4.21108E+09] "kWh" Vector__XXX

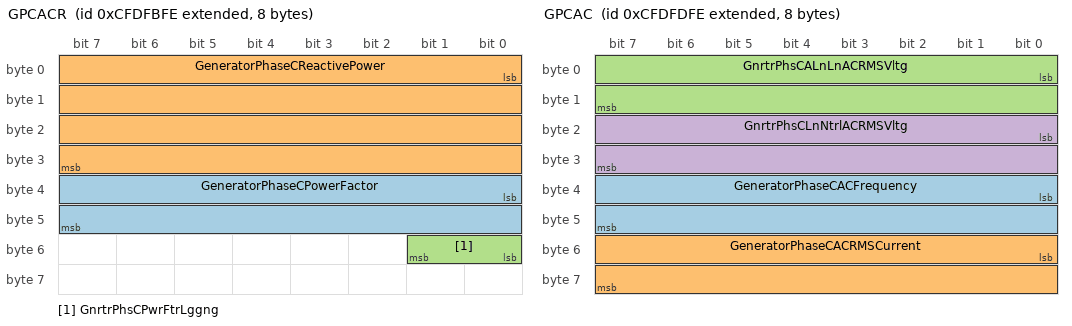
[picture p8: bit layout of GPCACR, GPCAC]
BO_ 2365455358 GPCACR: 8 Vector__XXX
 SG_ GeneratorPhaseCPowerFactor : 32|16@1+ (0.00006103515625,-1) [-1|2.921814] "" Vector__XXX
 SG_ GeneratorPhaseCReactivePower : 0|32@1+ (1,-2000000000) [-2000000000|2.21108E+09] "VAr" Vector__XXX
 SG_ GnrtrPhsCPwrFtrLggng : 48|2@1+ (1,0) [0|3] "" Vector__XXX

BO_ 2365455614 GPCACP: 8 Vector__XXX
 SG_ GeneratorPhaseCApparentPower : 32|32@1+ (1,-2000000000) [-2000000000|2.21108E+09] "VA" Vector__XXX
 SG_ GeneratorPhaseCRealPower : 0|32@1+ (1,-2000000000) [-2000000000|2.21108E+09] "W" Vector__XXX

BO_ 2365455870 GPCAC: 8 Vector__XXX
 SG_ GeneratorPhaseCACFrequency : 32|16@1+ (0.0078125,0) [0|501.9921875] "Hz" Vector__XXX
 SG_ GeneratorPhaseCACRMSCurrent : 48|16@1+ (1,0) [0|64255] "A" Vector__XXX
 SG_ GnrtrPhsCALnLnACRMSVltg : 0|16@1+ (1,0) [0|64255] "V" Vector__XXX
 SG_ GnrtrPhsCLnNtrlACRMSVltg : 16|16@1+ (1,0) [0|64255] "V" Vector__XXX

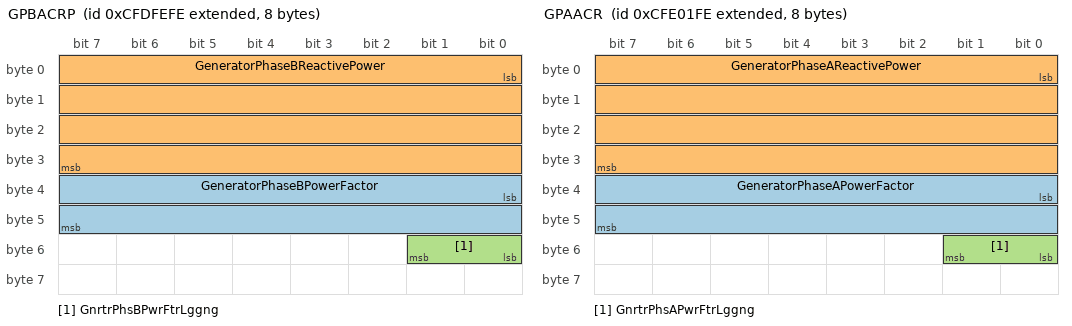
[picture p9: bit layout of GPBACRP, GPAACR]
BO_ 2365456126 GPBACRP: 8 Vector__XXX
 SG_ GeneratorPhaseBPowerFactor : 32|16@1+ (0.00006103515625,-1) [-1|2.921814] "" Vector__XXX
 SG_ GeneratorPhaseBReactivePower : 0|32@1+ (1,-2000000000) [-2000000000|2.21108E+09] "VAr" Vector__XXX
 SG_ GnrtrPhsBPwrFtrLggng : 48|2@1+ (1,0) [0|3] "" Vector__XXX

BO_ 2365456382 GPBACP: 8 Vector__XXX
 SG_ GeneratorPhaseBApparentPower : 32|32@1+ (1,-2000000000) [-2000000000|2.21108E+09] "VA" Vector__XXX
 SG_ GeneratorPhaseBRealPower : 0|32@1+ (1,-2000000000) [-2000000000|2.21108E+09] "W" Vector__XXX

BO_ 2365456894 GPAACR: 8 Vector__XXX
 SG_ GeneratorPhaseAPowerFactor : 32|16@1+ (0.00006103515625,-1) [-1|2.921814] "" Vector__XXX
 SG_ GeneratorPhaseAReactivePower : 0|32@1+ (1,-2000000000) [-2000000000|2.21108E+09] "VAr" Vector__XXX
 SG_ GnrtrPhsAPwrFtrLggng : 48|2@1+ (1,0) [0|3] "" Vector__XXX

BO_ 2365457150 GPAACP: 8 Vector__XXX
 SG_ GeneratorPhaseAApparentPower : 32|32@1+ (1,-2000000000) [-2000000000|2.21108E+09] "VA" Vector__XXX
 SG_ GeneratorPhaseARealPower : 0|32@1+ (1,-2000000000) [-2000000000|2.21108E+09] "W" Vector__XXX

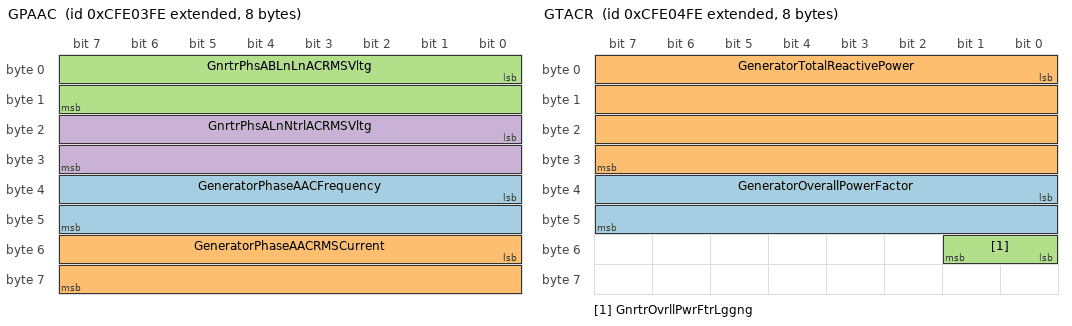
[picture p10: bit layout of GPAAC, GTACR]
BO_ 2365457406 GPAAC: 8 Vector__XXX
 SG_ GeneratorPhaseAACFrequency : 32|16@1+ (0.0078125,0) [0|501.9921875] "Hz" Vector__XXX
 SG_ GeneratorPhaseAACRMSCurrent : 48|16@1+ (1,0) [0|64255] "A" Vector__XXX
 SG_ GnrtrPhsABLnLnACRMSVltg : 0|16@1+ (1,0) [0|64255] "V" Vector__XXX
 SG_ GnrtrPhsALnNtrlACRMSVltg : 16|16@1+ (1,0) [0|64255] "V" Vector__XXX

BO_ 2365457662 GTACR: 8 Vector__XXX
 SG_ GeneratorOverallPowerFactor : 32|16@1+ (0.00006103515625,-1) [-1|2.921814] "" Vector__XXX
 SG_ GeneratorTotalReactivePower : 0|32@1+ (1,-2000000000) [-2000000000|2.21108E+09] "VAr" Vector__XXX
 SG_ GnrtrOvrllPwrFtrLggng : 48|2@1+ (1,0) [0|3] "" Vector__XXX

BO_ 2365457918 GTACP: 8 Vector__XXX
 SG_ GeneratorTotalApparentPower : 32|32@1+ (1,-2000000000) [-2000000000|2.21108E+09] "VA" Vector__XXX
 SG_ GeneratorTotalRealPower : 0|32@1+ (1,-2000000000) [-2000000000|2.21108E+09] "W" Vector__XXX

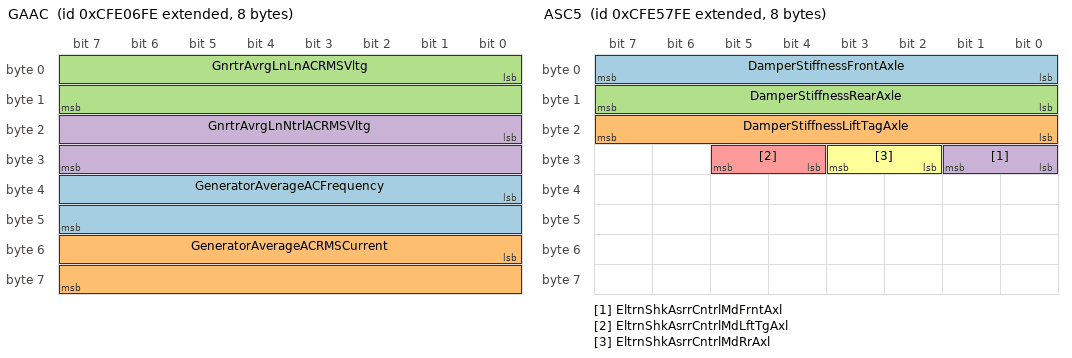
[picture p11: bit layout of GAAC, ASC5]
BO_ 2365458174 GAAC: 8 Vector__XXX
 SG_ GeneratorAverageACFrequency : 32|16@1+ (0.0078125,0) [0|501.9921875] "Hz" Vector__XXX
 SG_ GeneratorAverageACRMSCurrent : 48|16@1+ (1,0) [0|64255] "A" Vector__XXX
 SG_ GnrtrAvrgLnLnACRMSVltg : 0|16@1+ (1,0) [0|64255] "V" Vector__XXX
 SG_ GnrtrAvrgLnNtrlACRMSVltg : 16|16@1+ (1,0) [0|64255] "V" Vector__XXX

BO_ 2365473278 LCMD: 8 Vector__XXX
 SG_ AlternateBeamHeadLightCommand : 2|2@1+ (1,0) [0|3] "" Vector__XXX
 SG_ BackUpLightandAlarmHornCommand : 16|2@1+ (1,0) [0|3] "" Vector__XXX
 SG_ CenterStopLightCommand : 18|2@1+ (1,0) [0|3] "" Vector__XXX
 SG_ HighBeamHeadLightCommand : 6|2@1+ (1,0) [0|3] "" Vector__XXX
 SG_ ImplementClearanceLightCommand : 24|2@1+ (1,0) [0|3] "" Vector__XXX
 SG_ ImplementMarkerLightCommand : 28|2@1+ (1,0) [0|3] "" Vector__XXX
 SG_ ImplementOEMOption1LightCommand : 50|2@1+ (1,0) [0|3] "" Vector__XXX
 SG_ ImplementOEMOption2LightCommand : 48|2@1+ (1,0) [0|3] "" Vector__XXX
 SG_ ImplementRearWorkLightCommand : 62|2@1+ (1,0) [0|3] "" Vector__XXX
 SG_ ImplmntLftFngWrkLghtCmmnd : 60|2@1+ (1,0) [0|3] "" Vector__XXX
 SG_ ImplmntLftFrwrdWrkLghtCmmnd : 54|2@1+ (1,0) [0|3] "" Vector__XXX
 SG_ ImplmntRghtFngWrkLghtCmmnd : 52|2@1+ (1,0) [0|3] "" Vector__XXX
 SG_ ImplmntRghtFrwrdWrkLghtCmmnd : 58|2@1+ (1,0) [0|3] "" Vector__XXX
 SG_ LeftStopLightCommand : 22|2@1+ (1,0) [0|3] "" Vector__XXX
 SG_ LeftTurnSignalLightsCommand : 14|2@1+ (1,0) [0|3] "" Vector__XXX
 SG_ LightingDataRequestCommand : 56|2@1+ (1,0) [0|3] "" Vector__XXX
 SG_ LowBeamHeadLightCommand : 4|2@1+ (1,0) [0|3] "" Vector__XXX
 SG_ RearFogLightCommand : 32|2@1+ (1,0) [0|3] "" Vector__XXX
 SG_ RightStopLightCommand : 20|2@1+ (1,0) [0|3] "" Vector__XXX
 SG_ RightTurnSignalLightsCommand : 12|2@1+ (1,0) [0|3] "" Vector__XXX
 SG_ RotatingBeaconLightCommand : 10|2@1+ (1,0) [0|3] "" Vector__XXX
 SG_ RunningLightCommand : 0|2@1+ (1,0) [0|3] "" Vector__XXX
 SG_ TractorClearanceLightCommand : 26|2@1+ (1,0) [0|3] "" Vector__XXX
 SG_ TractorFrontFogLightsCommand : 8|2@1+ (1,0) [0|3] "" Vector__XXX
 SG_ TractorMarkerLightCommand : 30|2@1+ (1,0) [0|3] "" Vector__XXX
 SG_ TrtrFrntHghMntdWrkLghtsCmmnd : 46|2@1+ (1,0) [0|3] "" Vector__XXX
 SG_ TrtrFrntLwMntdWrkLghtsCmmnd : 44|2@1+ (1,0) [0|3] "" Vector__XXX
 SG_ TrtrRrHghMntdWrkLghtsCmmnd : 38|2@1+ (1,0) [0|3] "" Vector__XXX
 SG_ TrtrRrLwMntdWrkLghtsCmmnd : 36|2@1+ (1,0) [0|3] "" Vector__XXX
 SG_ TrtrSdHghMntdWrkLghtsCmmnd : 42|2@1+ (1,0) [0|3] "" Vector__XXX
 SG_ TrtrSdLwMntdWrkLghtsCmmnd : 40|2@1+ (1,0) [0|3] "" Vector__XXX
 SG_ TrtrUndrsdMntdWrkLghtsCmmnd : 34|2@1+ (1,0) [0|3] "" Vector__XXX

BO_ 2365478910 ASC5: 8 Vector__XXX
 SG_ DamperStiffnessFrontAxle : 0|8@1+ (0.4,0) [0|100] "%" Vector__XXX
 SG_ DamperStiffnessLiftTagAxle : 16|8@1+ (0.4,0) [0|100] "%" Vector__XXX
 SG_ DamperStiffnessRearAxle : 8|8@1+ (0.4,0) [0|100] "%" Vector__XXX
 SG_ EltrnShkAsrrCntrlMdFrntAxl : 24|2@1+ (1,0) [0|3] "" Vector__XXX
 SG_ EltrnShkAsrrCntrlMdLftTgAxl : 28|2@1+ (1,0) [0|3] "" Vector__XXX
 SG_ EltrnShkAsrrCntrlMdRrAxl : 26|2@1+ (1,0) [0|3] "" Vector__XXX

BO_ 2365479678 ASC1: 8 Vector__XXX
 SG_ AboveNominalLevelFrontAxle : 12|2@1+ (1,0) [0|3] "" Vector__XXX
 SG_ AboveNominalLevelRearAxle : 14|2@1+ (1,0) [0|3] "" Vector__XXX
 SG_ AllwLvlCntrlDrngBrkngStts : 52|2@1+ (1,0) [0|3] "" Vector__XXX
 SG_ BelowNominalLevelFrontAxle : 8|2@1+ (1,0) [0|3] "" Vector__XXX
 SG_ BelowNominalLevelRearAxle : 10|2@1+ (1,0) [0|3] "" Vector__XXX
 SG_ DoorRelease : 36|2@1+ (1,0) [0|3] "" Vector__XXX
 SG_ FrontAxleinBumperRange : 40|2@1+ (1,0) [0|3] "" Vector__XXX
 SG_ KneelingInformation : 24|4@1+ (1,0) [0|15] "" Vector__XXX
 SG_ LevelControlMode : 28|4@1+ (1,0) [0|15] "" Vector__XXX
 SG_ LiftAxle1Position : 38|2@1+ (1,0) [0|3] "" Vector__XXX
 SG_ LiftAxle2Position : 46|2@1+ (1,0) [0|3] "" Vector__XXX
 SG_ LiftingControlModeFrontAxle : 20|2@1+ (1,0) [0|3] "" Vector__XXX
 SG_ LiftingControlModeRearAxle : 22|2@1+ (1,0) [0|3] "" Vector__XXX
 SG_ LoweringControlModeFrontAxle : 16|2@1+ (1,0) [0|3] "" Vector__XXX
 SG_ LoweringControlModeRearAxle : 18|2@1+ (1,0) [0|3] "" Vector__XXX
 SG_ Memorylevel : 60|4@1+ (1,0) [0|15] "" Vector__XXX
 SG_ NominalLevelFrontAxle : 0|4@1+ (1,0) [0|15] "" Vector__XXX
 SG_ NominalLevelRearAxle : 4|4@1+ (1,0) [0|15] "" Vector__XXX
 SG_ RearAxleinBumperRange : 42|2@1+ (1,0) [0|3] "" Vector__XXX
 SG_ SecurityDevice : 32|2@1+ (1,0) [0|3] "" Vector__XXX
 SG_ SpdDpndntLvlCntrlStts : 54|2@1+ (1,0) [0|3] "" Vector__XXX
 SG_ SspnsnCntrlRfslInfrmtn : 56|4@1+ (1,0) [0|15] "" Vector__XXX
 SG_ SuspensionRemoteControl1 : 48|2@1+ (1,0) [0|3] "" Vector__XXX
 SG_ SuspensionRemotecontrol2 : 50|2@1+ (1,0) [0|3] "" Vector__XXX
 SG_ VehicleMotionInhibit : 34|2@1+ (1,0) [0|3] "" Vector__XXX

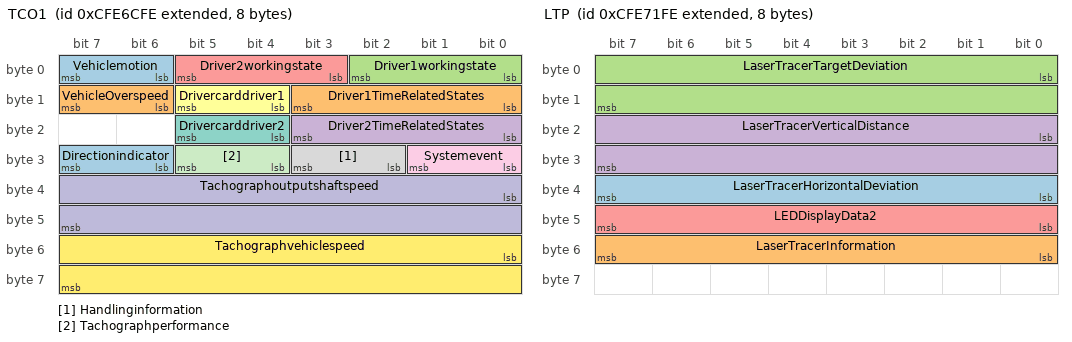
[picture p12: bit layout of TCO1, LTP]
BO_ 2365484286 TCO1: 8 Vector__XXX
 SG_ Directionindicator : 30|2@1+ (1,0) [0|3] "" Vector__XXX
 SG_ Driver1TimeRelatedStates : 8|4@1+ (1,0) [0|15] "" Vector__XXX
 SG_ Driver1workingstate : 0|3@1+ (1,0) [0|7] "" Vector__XXX
 SG_ Driver2TimeRelatedStates : 16|4@1+ (1,0) [0|15] "" Vector__XXX
 SG_ Driver2workingstate : 3|3@1+ (1,0) [0|7] "" Vector__XXX
 SG_ Drivercarddriver1 : 12|2@1+ (1,0) [0|3] "" Vector__XXX
 SG_ Drivercarddriver2 : 20|2@1+ (1,0) [0|3] "" Vector__XXX
 SG_ Handlinginformation : 26|2@1+ (1,0) [0|3] "" Vector__XXX
 SG_ Systemevent : 24|2@1+ (1,0) [0|3] "" Vector__XXX
 SG_ Tachographoutputshaftspeed : 32|16@1+ (0.125,0) [0|8031.875] "rpm" Vector__XXX
 SG_ Tachographperformance : 28|2@1+ (1,0) [0|3] "" Vector__XXX
 SG_ Tachographvehiclespeed : 48|16@1+ (0.00390625,0) [0|250.996] "km/h" Vector__XXX
 SG_ Vehiclemotion : 6|2@1+ (1,0) [0|3] "" Vector__XXX
 SG_ VehicleOverspeed : 14|2@1+ (1,0) [0|3] "" Vector__XXX

BO_ 2365485566 LTP: 8 Vector__XXX
 SG_ LaserTracerHorizontalDeviation : 32|8@1+ (1,0) [0|250] "%" Vector__XXX
 SG_ LaserTracerInformation : 48|8@1+ (1,0) [0|255] "" Vector__XXX
 SG_ LaserTracerTargetDeviation : 0|16@1+ (0.1,-3200) [-3200|3225.5] "mm" Vector__XXX
 SG_ LaserTracerVerticalDistance : 16|16@1+ (0.1,0) [0|6425.5] "mm" Vector__XXX
 SG_ LEDDisplayData2 : 40|8@1+ (1,0) [0|255] "" Vector__XXX

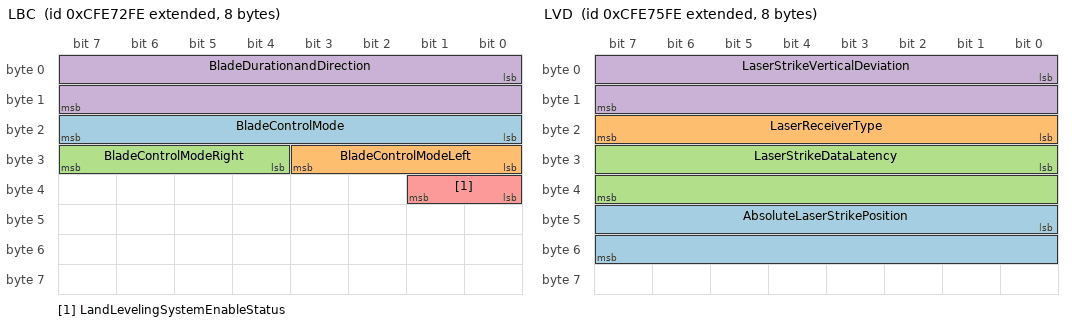
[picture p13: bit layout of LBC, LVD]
BO_ 2365485822 LBC: 8 Vector__XXX
 SG_ BladeControlMode : 16|8@1+ (1,0) [0|255] "" Vector__XXX
 SG_ BladeControlModeLeft : 24|4@1+ (1,0) [0|15] "" Vector__XXX
 SG_ BladeControlModeRight : 28|4@1+ (1,0) [0|15] "" Vector__XXX
 SG_ BladeDurationandDirection : 0|16@1+ (0.1,-3276.8) [-3276.8|3148.7] "s" Vector__XXX
 SG_ LandLevelingSystemEnableStatus : 32|2@1+ (1,0) [0|3] "" Vector__XXX

BO_ 2365486078 LMP: 8 Vector__XXX
 SG_ MastPosition : 0|16@1+ (0.1,-3200) [-3200|3225.5] "mm" Vector__XXX

BO_ 2365486334 LSP: 8 Vector__XXX
 SG_ BldHghtStPntHghRsltn : 16|32@1+ (0.0000001,-209.7152) [-209.7152|211.3929215] "m" Vector__XXX
 SG_ ModifyLevelingSystemSetPoint : 0|16@1+ (0.1,-3200) [-3200|3225.5] "mm" Vector__XXX

BO_ 2365486590 LVD: 8 Vector__XXX
 SG_ AbsoluteLaserStrikePosition : 40|16@1+ (0.1,0) [0|6425.5] "mm" Vector__XXX
 SG_ LaserReceiverType : 16|8@1+ (1,0) [0|250] "count" Vector__XXX
 SG_ LaserStrikeDataLatency : 24|16@1+ (0.0000512,0) [0|3.289856] "s" Vector__XXX
 SG_ LaserStrikeVerticalDeviation : 0|16@1+ (0.1,-3200) [-3200|3225.5] "mm" Vector__XXX

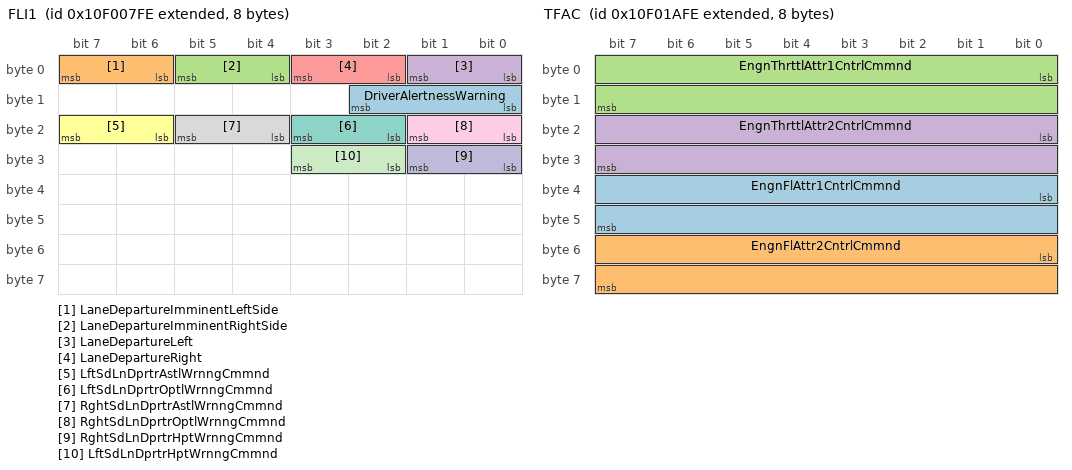
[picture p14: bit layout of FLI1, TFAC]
BO_ 2431649790 FLI1: 8 Vector__XXX
 SG_ DriverAlertnessWarning : 8|3@1+ (1,0) [0|7] "" Vector__XXX
 SG_ LaneDepartureImminentLeftSide : 6|2@1+ (1,0) [0|3] "" Vector__XXX
 SG_ LaneDepartureImminentRightSide : 4|2@1+ (1,0) [0|3] "" Vector__XXX
 SG_ LaneDepartureLeft : 0|2@1+ (1,0) [0|3] "" Vector__XXX
 SG_ LaneDepartureRight : 2|2@1+ (1,0) [0|3] "" Vector__XXX
 SG_ LftSdLnDprtrAstlWrnngCmmnd : 22|2@1+ (1,0) [0|3] "" Vector__XXX
 SG_ LftSdLnDprtrOptlWrnngCmmnd : 18|2@1+ (1,0) [0|3] "" Vector__XXX
 SG_ RghtSdLnDprtrAstlWrnngCmmnd : 20|2@1+ (1,0) [0|3] "" Vector__XXX
 SG_ RghtSdLnDprtrOptlWrnngCmmnd : 16|2@1+ (1,0) [0|3] "" Vector__XXX
 SG_ RghtSdLnDprtrHptWrnngCmmnd : 24|2@1+ (1,0) [0|3] "" Vector__XXX
 SG_ LftSdLnDprtrHptWrnngCmmnd : 26|2@1+ (1,0) [0|3] "" Vector__XXX

BO_ 2431654654 TFAC: 8 Vector__XXX
 SG_ EngnFlAttr1CntrlCmmnd : 32|16@1+ (0.0025,0) [0|160.6375] "%" Vector__XXX
 SG_ EngnFlAttr2CntrlCmmnd : 48|16@1+ (0.0025,0) [0|160.6375] "%" Vector__XXX
 SG_ EngnThrttlAttr1CntrlCmmnd : 0|16@1+ (0.0025,0) [0|160.6375] "%" Vector__XXX
 SG_ EngnThrttlAttr2CntrlCmmnd : 16|16@1+ (0.0025,0) [0|160.6375] "%" Vector__XXX

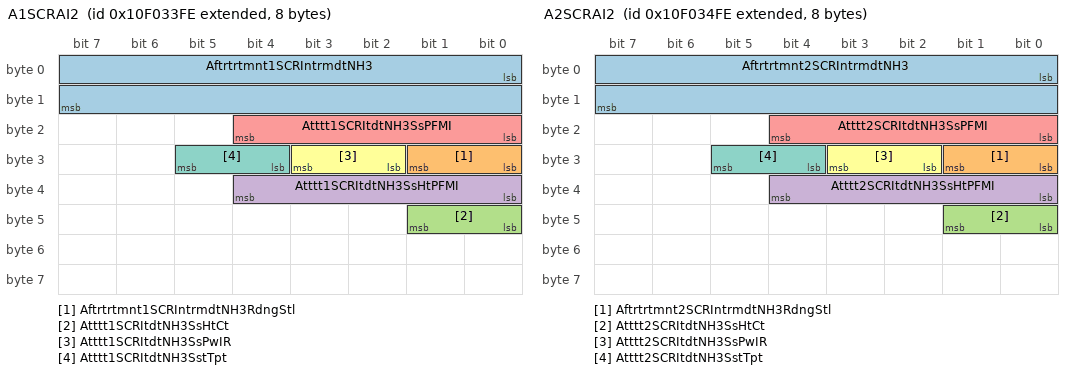
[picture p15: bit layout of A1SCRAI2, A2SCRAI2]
BO_ 2431661054 A1SCRAI2: 8 Vector__XXX
 SG_ Aftrtrtmnt1SCRIntrmdtNH3 : 0|16@1+ (0.1,-200) [-200|6225.5] "ppm" Vector__XXX
 SG_ Aftrtrtmnt1SCRIntrmdtNH3RdngStl : 24|2@1+ (1,0) [0|3] "" Vector__XXX
 SG_ Atttt1SCRItdtNH3SsHtCt : 40|2@1+ (1,0) [0|3] "" Vector__XXX
 SG_ Atttt1SCRItdtNH3SsHtPFMI : 32|5@1+ (1,0) [0|31] "binary" Vector__XXX
 SG_ Atttt1SCRItdtNH3SsPFMI : 16|5@1+ (1,0) [0|31] "binary" Vector__XXX
 SG_ Atttt1SCRItdtNH3SsPwIR : 26|2@1+ (1,0) [0|3] "" Vector__XXX
 SG_ Atttt1SCRItdtNH3SstTpt : 28|2@1+ (1,0) [0|3] "" Vector__XXX

BO_ 2431661310 A2SCRAI2: 8 Vector__XXX
 SG_ Aftrtrtmnt2SCRIntrmdtNH3 : 0|16@1+ (0.1,-200) [-200|6225.5] "ppm" Vector__XXX
 SG_ Aftrtrtmnt2SCRIntrmdtNH3RdngStl : 24|2@1+ (1,0) [0|3] "" Vector__XXX
 SG_ Atttt2SCRItdtNH3SsHtCt : 40|2@1+ (1,0) [0|3] "" Vector__XXX
 SG_ Atttt2SCRItdtNH3SsHtPFMI : 32|5@1+ (1,0) [0|31] "binary" Vector__XXX
 SG_ Atttt2SCRItdtNH3SsPFMI : 16|5@1+ (1,0) [0|31] "binary" Vector__XXX
 SG_ Atttt2SCRItdtNH3SsPwIR : 26|2@1+ (1,0) [0|3] "" Vector__XXX
 SG_ Atttt2SCRItdtNH3SstTpt : 28|2@1+ (1,0) [0|3] "" Vector__XXX

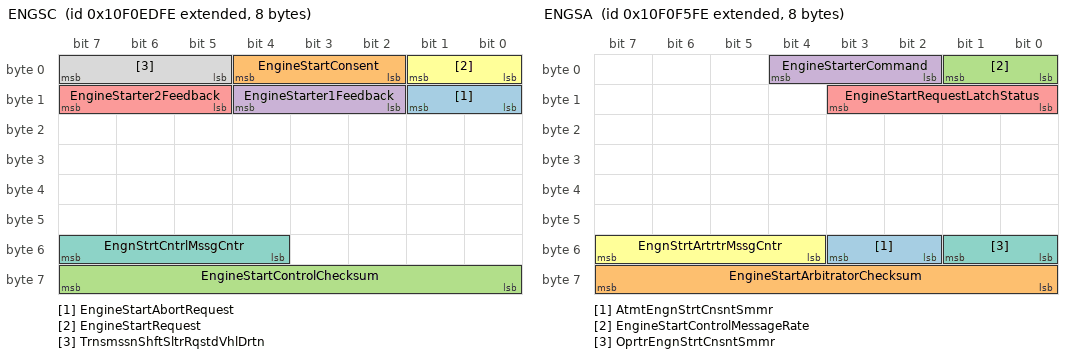
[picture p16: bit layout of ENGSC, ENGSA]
BO_ 2431708670 ENGSC: 8 Vector__XXX
 SG_ EngineStartAbortRequest : 8|2@1+ (1,0) [0|3] "" Vector__XXX
 SG_ EngineStartConsent : 2|3@1+ (1,0) [0|7] "" Vector__XXX
 SG_ EngineStartControlChecksum : 56|8@1+ (1,0) [0|255] "count" Vector__XXX
 SG_ EngineStarter1Feedback : 10|3@1+ (1,0) [0|7] "" Vector__XXX
 SG_ EngineStarter2Feedback : 13|3@1+ (1,0) [0|7] "" Vector__XXX
 SG_ EngineStartRequest : 0|2@1+ (1,0) [0|3] "" Vector__XXX
 SG_ EngnStrtCntrlMssgCntr : 52|4@1+ (1,0) [0|15] "" Vector__XXX
 SG_ TrnsmssnShftSltrRqstdVhlDrtn : 5|3@1+ (1,0) [0|7] "" Vector__XXX

BO_ 2431710718 ENGSA: 8 Vector__XXX
 SG_ AtmtEngnStrtCnsntSmmr : 50|2@1+ (1,0) [0|3] "" Vector__XXX
 SG_ EngineStartArbitratorChecksum : 56|8@1+ (1,0) [0|255] "count" Vector__XXX
 SG_ EngineStartControlMessageRate : 0|2@1+ (1,0) [0|3] "" Vector__XXX
 SG_ EngineStarterCommand : 2|3@1+ (1,0) [0|7] "" Vector__XXX
 SG_ EngineStartRequestLatchStatus : 8|4@1+ (1,0) [0|15] "" Vector__XXX
 SG_ EngnStrtArtrtrMssgCntr : 52|4@1+ (1,0) [0|15] "" Vector__XXX
 SG_ OprtrEngnStrtCnsntSmmr : 48|2@1+ (1,0) [0|3] "" Vector__XXX

BO_ 2431717886 GFP3: 8 Vector__XXX
 SG_ EngnFlVlv1DffrntlPrssrHghRsltn : 0|16@1+ (0.0078125,-100) [-100|401.99] "kPa" Vector__XXX

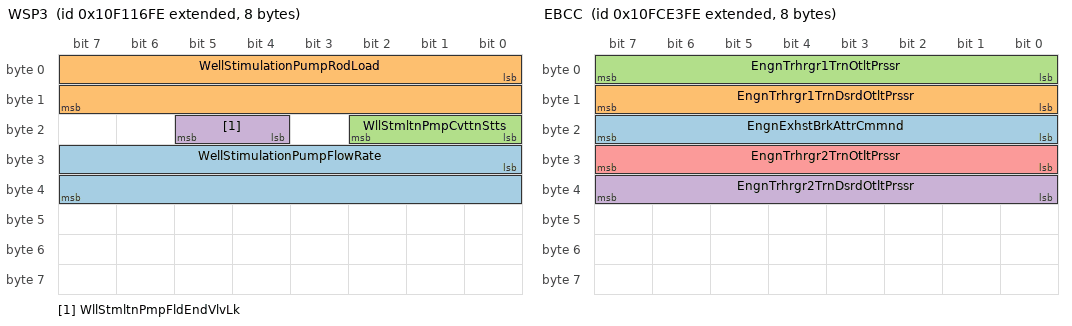
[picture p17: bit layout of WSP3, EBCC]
BO_ 2431719166 WSP3: 8 Vector__XXX
 SG_ WellStimulationPumpFlowRate : 24|16@1+ (0.5,0) [0|32127.5] "l/min" Vector__XXX
 SG_ WellStimulationPumpRodLoad : 0|16@1+ (5,0) [0|321275] "kN" Vector__XXX
 SG_ WllStmltnPmpCvttnStts : 16|3@1+ (1,0) [0|7] "" Vector__XXX
 SG_ WllStmltnPmpFldEndVlvLk : 20|2@1+ (1,0) [0|3] "" Vector__XXX

BO_ 2432471038 AF3: 8 Vector__XXX
 SG_ EngnFlVprzr1DshrgTmprtr : 16|8@1+ (1,-40) [-40|210] "degC" Vector__XXX
 SG_ EngnGssFlSpplPrssr1ExtnddRng : 0|16@1+ (0.00390625,0) [0|250.996] "MPa" Vector__XXX
 SG_ GssFlAmltrTmprtr : 24|8@1+ (1,-40) [-40|210] "degC" Vector__XXX
 SG_ EGssFSppPssRtCtCd : 32|16@1+ (0.0025,0) [0|160.6375] "%" Vector__XXX

BO_ 2432492542 EBCC: 8 Vector__XXX
 SG_ EngnExhstBrkAttrCmmnd : 16|8@1+ (0.4,0) [0|100] "%" Vector__XXX
 SG_ EngnTrhrgr1TrnDsrdOtltPrssr : 8|8@1+ (2,0) [0|500] "kPa" Vector__XXX
 SG_ EngnTrhrgr1TrnOtltPrssr : 0|8@1+ (2,0) [0|500] "kPa" Vector__XXX
 SG_ EngnTrhrgr2TrnDsrdOtltPrssr : 32|8@1+ (2,0) [0|500] "kPa" Vector__XXX
 SG_ EngnTrhrgr2TrnOtltPrssr : 24|8@1+ (2,0) [0|500] "kPa" Vector__XXX

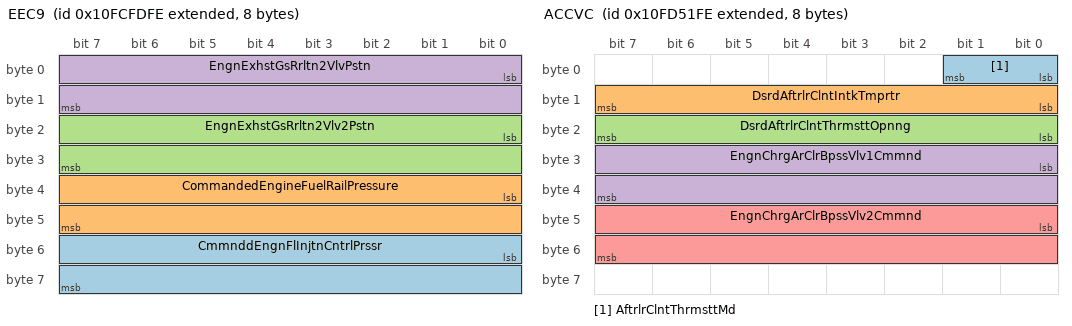
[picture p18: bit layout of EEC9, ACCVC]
BO_ 2432499198 EEC9: 8 Vector__XXX
 SG_ CmmnddEngnFlInjtnCntrlPrssr : 48|16@1+ (0.00390625,0) [0|250.996] "MPa" Vector__XXX
 SG_ CommandedEngineFuelRailPressure : 32|16@1+ (0.00390625,0) [0|250.996] "MPa" Vector__XXX
 SG_ EngnExhstGsRrltn2Vlv2Pstn : 16|16@1+ (0.0025,0) [0|160.6375] "%" Vector__XXX
 SG_ EngnExhstGsRrltn2VlvPstn : 0|16@1+ (0.0025,0) [0|160.6375] "%" Vector__XXX

BO_ 2432520702 ACCVC: 8 Vector__XXX
 SG_ AftrlrClntThrmsttMd : 0|2@1+ (1,0) [0|3] "" Vector__XXX
 SG_ DsrdAftrlrClntIntkTmprtr : 8|8@1+ (1,-40) [-40|210] "degC" Vector__XXX
 SG_ DsrdAftrlrClntThrmsttOpnng : 16|8@1+ (0.4,0) [0|100] "%" Vector__XXX
 SG_ EngnChrgArClrBpssVlv1Cmmnd : 24|16@1+ (0.0025,0) [0|160.6375] "%" Vector__XXX
 SG_ EngnChrgArClrBpssVlv2Cmmnd : 40|16@1+ (0.0025,0) [0|160.6375] "%" Vector__XXX

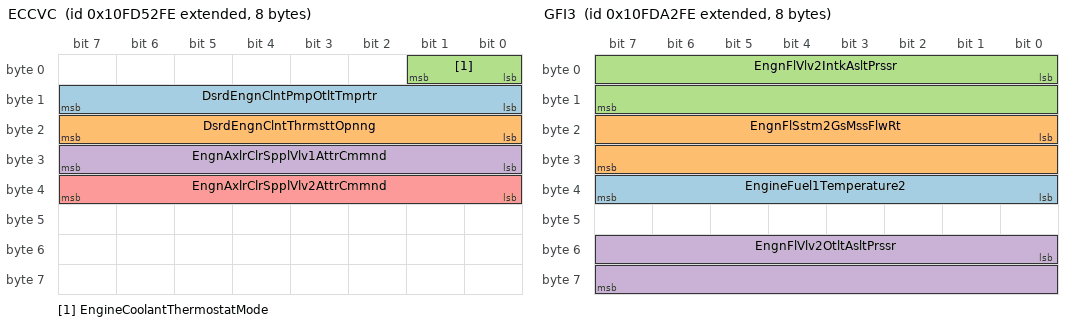
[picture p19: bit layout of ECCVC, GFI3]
BO_ 2432520958 ECCVC: 8 Vector__XXX
 SG_ DsrdEngnClntPmpOtltTmprtr : 8|8@1+ (1,-40) [-40|210] "degC" Vector__XXX
 SG_ DsrdEngnClntThrmsttOpnng : 16|8@1+ (0.4,0) [0|100] "%" Vector__XXX
 SG_ EngineCoolantThermostatMode : 0|2@1+ (1,0) [0|3] "" Vector__XXX
 SG_ EngnAxlrClrSpplVlv1AttrCmmnd : 24|8@1+ (0.4,0) [0|100] "%" Vector__XXX
 SG_ EngnAxlrClrSpplVlv2AttrCmmnd : 32|8@1+ (0.4,0) [0|100] "%" Vector__XXX

BO_ 2432541438 GFI3: 8 Vector__XXX
 SG_ EngineFuel1Temperature2 : 32|8@1+ (1,-40) [-40|210] "degC" Vector__XXX
 SG_ EngnFlSstm2GsMssFlwRt : 16|16@1+ (0.05,0) [0|3212.75] "kg/h" Vector__XXX
 SG_ EngnFlVlv2IntkAsltPrssr : 0|16@1+ (0.1,0) [0|6425.5] "kPa" Vector__XXX
 SG_ EngnFlVlv2OtltAsltPrssr : 48|16@1+ (0.1,0) [0|6425.5] "kPa" Vector__XXX

CM_ BO_ 2365401598 "Extended Joystick Message 7";
CM_ SG_ 2365401598 Joystick7Button13PressedStatus "Reports when the joystick button has been pressed.00b = Button not pressed01b = Button pressed10b = Error Indicator11b = Not Available…";
CM_ SG_ 2365401598 Joystick7Button14PressedStatus "Reports when the joystick button has been pressed.00b = Button not pressed01b = Button pressed10b = Error Indicator11b = Not Available…";
CM_ SG_ 2365401598 Joystick7Button15PressedStatus "Reports when the joystick button has been pressed.00b = Button not pressed01b = Button pressed10b = Error Indicator11b = Not Available…";
CM_ SG_ 2365401598 Joystick7Button16PressedStatus "Reports when the joystick button has been pressed.00b = Button not pressed01b = Button pressed10b = Error Indicator11b = Not Available…";
CM_ SG_ 2365401598 Joystick7GripXAxisPosition "The position of the joystick grip in the relative motion of travel from the neutral position.  Position value of 0 is Neutral and position value 1000 (100%) is …";
CM_ SG_ 2365401598 Joystick7GripYAxisPosition "The position of the joystick grip in the relative motion of travel from the neutral position.  Position value of 0 is Neutral and position value 1000 (100%) is …";
CM_ SG_ 2365401598 Joystick7ThetaAxisPosition "The position of the joystick in the relative motion of travel from the neutral position.  Position value of 0 is Neutral and position value 1000 (100%) is the e…";
CM_ SG_ 2365401598 Jst7GpYAxsLvFwdPstvPstStts "Reports when the current joystick grip position is on the positive travel side (forward, right, clockwise, up) relative to the neutral position for that axis of…";
CM_ SG_ 2365401598 Jst7TtAxsCtCwsNtvPstStts "Reports when the current joystick position is on the negative travel side (back, left, counterclockwise, down) relative to the neutral position for that axis of…";
CM_ SG_ 2365401598 Jstk7GrpXAxsDtntPstnStts "Reports when the current joystick grip position is in the detent position for that axis of travel.00b = Not in the Detent Position01b = In the Detent Position10…";
CM_ SG_ 2365401598 Jstk7GrpXAxsLvrLftNgtvPstnStts "Reports when the current joystick grip position is on the negative travel side (back, left, counterclockwise, down) relative to the neutral position for that ax…";
CM_ SG_ 2365401598 Jstk7GrpXAxsLvrRghtPstvPstnStts "Reports when the current joystick grip position is on the positive travel side (forward, right, clockwise, up) relative to the neutral position for that axis of…";
CM_ SG_ 2365401598 Jstk7GrpXAxsNtrlPstnStts "Reports when the current joystick grip position is in the neutral position for that axis of travel.  The neutral position measurement must be determined from so…";
CM_ SG_ 2365401598 Jstk7GrpYAxsDtntPstnStts "Reports when the current joystick grip position is in the detent position for that axis of travel.00b = Not in the Detent Position01b = In the Detent Position10…";
CM_ SG_ 2365401598 Jstk7GrpYAxsLvrBkNgtvPstnStts "Reports when the current joystick grip position is on the negative travel side (back, left, counterclockwise, down) relative to the neutral position for that ax…";
CM_ SG_ 2365401598 Jstk7GrpYAxsNtrlPstnStts "Reports when the current joystick grip position is in the neutral position for that axis of travel.  The neutral position measurement must be determined from so…";
CM_ SG_ 2365401598 Jstk7ThtAxsClkwsPstvPstnStts "Reports when the current joystick position is on the positive travel side (forward, right, clockwise, up) relative to the neutral position for that axis of trav…";
CM_ SG_ 2365401598 Jstk7ThtAxsDtntPstnStts "Reports when the current joystick position is in the detent position for that axis of travel.00b = Not in the Detent Position01b = In the Detent Position10b = E…";
CM_ SG_ 2365401598 Jstk7ThtAxsNtrlPstnStts "Reports when the current joystick position is in the neutral position for that axis of travel.  The neutral position measurement must be determined from some me…";
CM_ BO_ 2365401854 "Basic Joystick Message 7";
CM_ SG_ 2365401854 Joystick7Button10PressedStatus "Reports when the joystick button has been pressed.00b = Button not pressed01b = Button pressed10b = Error Indicator11b = Not Available…";
CM_ SG_ 2365401854 Joystick7Button11PressedStatus "Reports when the joystick button has been pressed.00b = Button not pressed01b = Button pressed10b = Error Indicator11b = Not Available…";
CM_ SG_ 2365401854 Joystick7Button12PressedStatus "Reports when the joystick button has been pressed.00b = Button not pressed01b = Button pressed10b = Error Indicator11b = Not Available…";
CM_ SG_ 2365401854 Joystick7Button1PressedStatus "Reports when the joystick button has been pressed.00b = Button not pressed01b = Button pressed10b = Error Indicator11b = Not Available…";
CM_ SG_ 2365401854 Joystick7Button2PressedStatus "Reports when the joystick button has been pressed.00b = Button not pressed01b = Button pressed10b = Error Indicator11b = Not Available…";
CM_ SG_ 2365401854 Joystick7Button3PressedStatus "Reports when the joystick button has been pressed.00b = Button not pressed01b = Button pressed10b = Error Indicator11b = Not Available…";
CM_ SG_ 2365401854 Joystick7Button4PressedStatus "Reports when the joystick button has been pressed.00b = Button not pressed01b = Button pressed10b = Error Indicator11b = Not Available…";
CM_ SG_ 2365401854 Joystick7Button5PressedStatus "Reports when the joystick button has been pressed.00b = Button not pressed01b = Button pressed10b = Error Indicator11b = Not Available…";
CM_ SG_ 2365401854 Joystick7Button6PressedStatus "Reports when the joystick button has been pressed.00b = Button not pressed01b = Button pressed10b = Error Indicator11b = Not Available…";
CM_ SG_ 2365401854 Joystick7Button7PressedStatus "Reports when the joystick button has been pressed.00b = Button not pressed01b = Button pressed10b = Error Indicator11b = Not Available…";
CM_ SG_ 2365401854 Joystick7Button8PressedStatus "Reports when the joystick button has been pressed.00b = Button not pressed01b = Button pressed10b = Error Indicator11b = Not Available…";
CM_ SG_ 2365401854 Joystick7Button9PressedStatus "Reports when the joystick button has been pressed.00b = Button not pressed01b = Button pressed10b = Error Indicator11b = Not Available…";
CM_ SG_ 2365401854 Joystick7XAxisPosition "The position of the joystick in the relative motion of travel from the neutral position.  Position value of 0 is Neutral and position value 1000 (100%) is the e…";
CM_ SG_ 2365401854 Joystick7YAxisPosition "The position of the joystick in the relative motion of travel from the neutral position.  Position value of 0 is Neutral and position value 1000 (100%) is the e…";
CM_ SG_ 2365401854 Jstk7XAxsDtntPstnStts "Reports when the current joystick position is in the detent position for that axis of travel.00b = Not in the Detent Position01b = In the Detent Position10b = E…";
CM_ SG_ 2365401854 Jstk7XAxsLvrLftNgtvPstnStts "Reports when the current joystick position is on the negative travel side (back, left, counterclockwise, down) relative to the neutral position for that axis of…";
CM_ SG_ 2365401854 Jstk7XAxsLvrRghtPstvPstnStts "Reports when the current joystick position is on the positive travel side (forward, right, clockwise, up) relative to the neutral position for that axis of trav…";
CM_ SG_ 2365401854 Jstk7XAxsNtrlPstnStts "Reports when the current joystick position is in the neutral position for that axis of travel.  The neutral position measurement must be determined from some me…";
CM_ SG_ 2365401854 Jstk7YAxsDtntPstnStts "Reports when the current joystick position is in the detent position for that axis of travel.00b = Not in the Detent Position01b = In the Detent Position10b = E…";
CM_ SG_ 2365401854 Jstk7YAxsLvrBkNgtvPstnStts "Reports when the current joystick position is on the negative travel side (back, left, counterclockwise, down) relative to the neutral position for that axis of…";
CM_ SG_ 2365401854 Jstk7YAxsLvrFrwrdPstvPstnStts "Reports when the current joystick position is on the positive travel side (forward, right, clockwise, up) relative to the neutral position for that axis of trav…";
CM_ SG_ 2365401854 Jstk7YAxsNtrlPstnStts "Reports when the current joystick position is in the neutral position for that axis of travel.  The neutral position measurement must be determined from some me…";
CM_ BO_ 2365402110 "Extended Joystick Message 6";
CM_ SG_ 2365402110 Joystick6Button13PressedStatus "Reports when the joystick button has been pressed.00b = Button not pressed01b = Button pressed10b = Error Indicator11b = Not Available…";
CM_ SG_ 2365402110 Joystick6Button14PressedStatus "Reports when the joystick button has been pressed.00b = Button not pressed01b = Button pressed10b = Error Indicator11b = Not Available…";
CM_ SG_ 2365402110 Joystick6Button15PressedStatus "Reports when the joystick button has been pressed.00b = Button not pressed01b = Button pressed10b = Error Indicator11b = Not Available…";
CM_ SG_ 2365402110 Joystick6Button16PressedStatus "Reports when the joystick button has been pressed.00b = Button not pressed01b = Button pressed10b = Error Indicator11b = Not Available…";
CM_ SG_ 2365402110 Joystick6GripXAxisPosition "The position of the joystick grip in the relative motion of travel from the neutral position.  Position value of 0 is Neutral and position value 1000 (100%) is …";
CM_ SG_ 2365402110 Joystick6GripYAxisPosition "The position of the joystick grip in the relative motion of travel from the neutral position.  Position value of 0 is Neutral and position value 1000 (100%) is …";
CM_ SG_ 2365402110 Joystick6ThetaAxisPosition "The position of the joystick in the relative motion of travel from the neutral position.  Position value of 0 is Neutral and position value 1000 (100%) is the e…";
CM_ SG_ 2365402110 Jst6GpYAxsLvFwdPstvPstStts "Reports when the current joystick grip position is on the positive travel side (forward, right, clockwise, up) relative to the neutral position for that axis of…";
CM_ SG_ 2365402110 Jst6TtAxsCtCwsNtvPstStts "Reports when the current joystick position is on the negative travel side (back, left, counterclockwise, down) relative to the neutral position for that axis of…";
CM_ SG_ 2365402110 Jstk6GrpXAxsDtntPstnStts "Reports when the current joystick grip position is in the detent position for that axis of travel.00b = Not in the Detent Position01b = In the Detent Position10…";
CM_ SG_ 2365402110 Jstk6GrpXAxsLvrLftNgtvPstnStts "Reports when the current joystick grip position is on the negative travel side (back, left, counterclockwise, down) relative to the neutral position for that ax…";
CM_ SG_ 2365402110 Jstk6GrpXAxsLvrRghtPstvPstnStts "Reports when the current joystick grip position is on the positive travel side (forward, right, clockwise, up) relative to the neutral position for that axis of…";
CM_ SG_ 2365402110 Jstk6GrpXAxsNtrlPstnStts "Reports when the current joystick grip position is in the neutral position for that axis of travel.  The neutral position measurement must be determined from so…";
CM_ SG_ 2365402110 Jstk6GrpYAxsDtntPstnStts "Reports when the current joystick grip position is in the detent position for that axis of travel.00b = Not in the Detent Position01b = In the Detent Position10…";
CM_ SG_ 2365402110 Jstk6GrpYAxsLvrBkNgtvPstnStts "Reports when the current joystick grip position is on the negative travel side (back, left, counterclockwise, down) relative to the neutral position for that ax…";
CM_ SG_ 2365402110 Jstk6GrpYAxsNtrlPstnStts "Reports when the current joystick grip position is in the neutral position for that axis of travel.  The neutral position measurement must be determined from so…";
CM_ SG_ 2365402110 Jstk6ThtAxsClkwsPstvPstnStts "Reports when the current joystick position is on the positive travel side (forward, right, clockwise, up) relative to the neutral position for that axis of trav…";
CM_ SG_ 2365402110 Jstk6ThtAxsDtntPstnStts "Reports when the current joystick position is in the detent position for that axis of travel.00b = Not in the Detent Position01b = In the Detent Position10b = E…";
CM_ SG_ 2365402110 Jstk6ThtAxsNtrlPstnStts "Reports when the current joystick position is in the neutral position for that axis of travel.  The neutral position measurement must be determined from some me…";
CM_ BO_ 2365402366 "Basic Joystick Message 6";
CM_ SG_ 2365402366 Joystick6Button10PressedStatus "Reports when the joystick button has been pressed.00b = Button not pressed01b = Button pressed10b = Error Indicator11b = Not Available…";
CM_ SG_ 2365402366 Joystick6Button11PressedStatus "Reports when the joystick button has been pressed.00b = Button not pressed01b = Button pressed10b = Error Indicator11b = Not Available…";
CM_ SG_ 2365402366 Joystick6Button12PressedStatus "Reports when the joystick button has been pressed.00b = Button not pressed01b = Button pressed10b = Error Indicator11b = Not Available…";
CM_ SG_ 2365402366 Joystick6Button1PressedStatus "Reports when the joystick button has been pressed.00b = Button not pressed01b = Button pressed10b = Error Indicator11b = Not Available…";
CM_ SG_ 2365402366 Joystick6Button2PressedStatus "Reports when the joystick button has been pressed.00b = Button not pressed01b = Button pressed10b = Error Indicator11b = Not Available…";
CM_ SG_ 2365402366 Joystick6Button3PressedStatus "Reports when the joystick button has been pressed.00b = Button not pressed01b = Button pressed10b = Error Indicator11b = Not Available…";
CM_ SG_ 2365402366 Joystick6Button4PressedStatus "Reports when the joystick button has been pressed.00b = Button not pressed01b = Button pressed10b = Error Indicator11b = Not Available…";
CM_ SG_ 2365402366 Joystick6Button5PressedStatus "Reports when the joystick button has been pressed.00b = Button not pressed01b = Button pressed10b = Error Indicator11b = Not Available…";
CM_ SG_ 2365402366 Joystick6Button6PressedStatus "Reports when the joystick button has been pressed.00b = Button not pressed01b = Button pressed10b = Error Indicator11b = Not Available…";
CM_ SG_ 2365402366 Joystick6Button7PressedStatus "Reports when the joystick button has been pressed.00b = Button not pressed01b = Button pressed10b = Error Indicator11b = Not Available…";
CM_ SG_ 2365402366 Joystick6Button8PressedStatus "Reports when the joystick button has been pressed.00b = Button not pressed01b = Button pressed10b = Error Indicator11b = Not Available…";
CM_ SG_ 2365402366 Joystick6Button9PressedStatus "Reports when the joystick button has been pressed.00b = Button not pressed01b = Button pressed10b = Error Indicator11b = Not Available…";
CM_ SG_ 2365402366 Joystick6XAxisPosition "The position of the joystick in the relative motion of travel from the neutral position.  Position value of 0 is Neutral and position value 1000 (100%) is the e…";
CM_ SG_ 2365402366 Joystick6YAxisPosition "The position of the joystick in the relative motion of travel from the neutral position.  Position value of 0 is Neutral and position value 1000 (100%) is the e…";
CM_ SG_ 2365402366 Jstk6XAxsDtntPstnStts "Reports when the current joystick position is in the detent position for that axis of travel.00b = Not in the Detent Position01b = In the Detent Position10b = E…";
CM_ SG_ 2365402366 Jstk6XAxsLvrLftNgtvPstnStts "Reports when the current joystick position is on the negative travel side (back, left, counterclockwise, down) relative to the neutral position for that axis of…";
CM_ SG_ 2365402366 Jstk6XAxsLvrRghtPstvPstnStts "Reports when the current joystick position is on the positive travel side (forward, right, clockwise, up) relative to the neutral position for that axis of trav…";
CM_ SG_ 2365402366 Jstk6XAxsNtrlPstnStts "Reports when the current joystick position is in the neutral position for that axis of travel.  The neutral position measurement must be determined from some me…";
CM_ SG_ 2365402366 Jstk6YAxsDtntPstnStts "Reports when the current joystick position is in the detent position for that axis of travel.00b = Not in the Detent Position01b = In the Detent Position10b = E…";
CM_ SG_ 2365402366 Jstk6YAxsLvrBkNgtvPstnStts "Reports when the current joystick position is on the negative travel side (back, left, counterclockwise, down) relative to the neutral position for that axis of…";
CM_ SG_ 2365402366 Jstk6YAxsLvrFrwrdPstvPstnStts "Reports when the current joystick position is on the positive travel side (forward, right, clockwise, up) relative to the neutral position for that axis of trav…";
CM_ SG_ 2365402366 Jstk6YAxsNtrlPstnStts "Reports when the current joystick position is in the neutral position for that axis of travel.  The neutral position measurement must be determined from some me…";
CM_ BO_ 2365402622 "Extended Joystick Message 5";
CM_ SG_ 2365402622 Joystick5Button13PressedStatus "Reports when the joystick button has been pressed.00b = Button not pressed01b = Button pressed10b = Error Indicator11b = Not Available…";
CM_ SG_ 2365402622 Joystick5Button14PressedStatus "Reports when the joystick button has been pressed.00b = Button not pressed01b = Button pressed10b = Error Indicator11b = Not Available…";
CM_ SG_ 2365402622 Joystick5Button15PressedStatus "Reports when the joystick button has been pressed.00b = Button not pressed01b = Button pressed10b = Error Indicator11b = Not Available…";
CM_ SG_ 2365402622 Joystick5Button16PressedStatus "Reports when the joystick button has been pressed.00b = Button not pressed01b = Button pressed10b = Error Indicator11b = Not Available…";
CM_ SG_ 2365402622 Joystick5GripXAxisPosition "The position of the joystick grip in the relative motion of travel from the neutral position.  Position value of 0 is Neutral and position value 1000 (100%) is …";
CM_ SG_ 2365402622 Joystick5GripYAxisPosition "The position of the joystick grip in the relative motion of travel from the neutral position.  Position value of 0 is Neutral and position value 1000 (100%) is …";
CM_ SG_ 2365402622 Joystick5ThetaAxisPosition "The position of the joystick in the relative motion of travel from the neutral position.  Position value of 0 is Neutral and position value 1000 (100%) is the e…";
CM_ SG_ 2365402622 Jst5GpYAxsLvFwdPstvPstStts "Reports when the current joystick grip position is on the positive travel side (forward, right, clockwise, up) relative to the neutral position for that axis of…";
CM_ SG_ 2365402622 Jst5TtAxsCtCwsNtvPstStts "Reports when the current joystick position is on the negative travel side (back, left, counterclockwise, down) relative to the neutral position for that axis of…";
CM_ SG_ 2365402622 Jstk5GrpXAxsDtntPstnStts "Reports when the current joystick grip position is in the detent position for that axis of travel.00b = Not in the Detent Position01b = In the Detent Position10…";
CM_ SG_ 2365402622 Jstk5GrpXAxsLvrLftNgtvPstnStts "Reports when the current joystick grip position is on the negative travel side (back, left, counterclockwise, down) relative to the neutral position for that ax…";
CM_ SG_ 2365402622 Jstk5GrpXAxsLvrRghtPstvPstnStts "Reports when the current joystick grip position is on the positive travel side (forward, right, clockwise, up) relative to the neutral position for that axis of…";
CM_ SG_ 2365402622 Jstk5GrpXAxsNtrlPstnStts "Reports when the current joystick grip position is in the neutral position for that axis of travel.  The neutral position measurement must be determined from so…";
CM_ SG_ 2365402622 Jstk5GrpYAxsDtntPstnStts "Reports when the current joystick grip position is in the detent position for that axis of travel.00b = Not in the Detent Position01b = In the Detent Position10…";
CM_ SG_ 2365402622 Jstk5GrpYAxsLvrBkNgtvPstnStts "Reports when the current joystick grip position is on the negative travel side (back, left, counterclockwise, down) relative to the neutral position for that ax…";
CM_ SG_ 2365402622 Jstk5GrpYAxsNtrlPstnStts "Reports when the current joystick grip position is in the neutral position for that axis of travel.  The neutral position measurement must be determined from so…";
CM_ SG_ 2365402622 Jstk5ThtAxsClkwsPstvPstnStts "Reports when the current joystick position is on the positive travel side (forward, right, clockwise, up) relative to the neutral position for that axis of trav…";
CM_ SG_ 2365402622 Jstk5ThtAxsDtntPstnStts "Reports when the current joystick position is in the detent position for that axis of travel.00b = Not in the Detent Position01b = In the Detent Position10b = E…";
CM_ SG_ 2365402622 Jstk5ThtAxsNtrlPstnStts "Reports when the current joystick position is in the neutral position for that axis of travel.  The neutral position measurement must be determined from some me…";
CM_ BO_ 2365402878 "Basic Joystick Message 5";
CM_ SG_ 2365402878 Joystick5Button10PressedStatus "Reports when the joystick button has been pressed.00b = Button not pressed01b = Button pressed10b = Error Indicator11b = Not Available…";
CM_ SG_ 2365402878 Joystick5Button11PressedStatus "Reports when the joystick button has been pressed.00b = Button not pressed01b = Button pressed10b = Error Indicator11b = Not Available…";
CM_ SG_ 2365402878 Joystick5Button12PressedStatus "Reports when the joystick button has been pressed.00b = Button not pressed01b = Button pressed10b = Error Indicator11b = Not Available…";
CM_ SG_ 2365402878 Joystick5Button1PressedStatus "Reports when the joystick button has been pressed.00b = Button not pressed01b = Button pressed10b = Error Indicator11b = Not Available…";
CM_ SG_ 2365402878 Joystick5Button2PressedStatus "Reports when the joystick button has been pressed.00b = Button not pressed01b = Button pressed10b = Error Indicator11b = Not Available…";
CM_ SG_ 2365402878 Joystick5Button3PressedStatus "Reports when the joystick button has been pressed.00b = Button not pressed01b = Button pressed10b = Error Indicator11b = Not Available…";
CM_ SG_ 2365402878 Joystick5Button4PressedStatus "Reports when the joystick button has been pressed.00b = Button not pressed01b = Button pressed10b = Error Indicator11b = Not Available…";
CM_ SG_ 2365402878 Joystick5Button5PressedStatus "Reports when the joystick button has been pressed.00b = Button not pressed01b = Button pressed10b = Error Indicator11b = Not Available…";
CM_ SG_ 2365402878 Joystick5Button6PressedStatus "Reports when the joystick button has been pressed.00b = Button not pressed01b = Button pressed10b = Error Indicator11b = Not Available…";
CM_ SG_ 2365402878 Joystick5Button7PressedStatus "Reports when the joystick button has been pressed.00b = Button not pressed01b = Button pressed10b = Error Indicator11b = Not Available…";
CM_ SG_ 2365402878 Joystick5Button8PressedStatus "Reports when the joystick button has been pressed.00b = Button not pressed01b = Button pressed10b = Error Indicator11b = Not Available…";
CM_ SG_ 2365402878 Joystick5Button9PressedStatus "Reports when the joystick button has been pressed.00b = Button not pressed01b = Button pressed10b = Error Indicator11b = Not Available…";
CM_ SG_ 2365402878 Joystick5XAxisPosition "The position of the joystick in the relative motion of travel from the neutral position.  Position value of 0 is Neutral and position value 1000 (100%) is the e…";
CM_ SG_ 2365402878 Joystick5YAxisPosition "The position of the joystick in the relative motion of travel from the neutral position.  Position value of 0 is Neutral and position value 1000 (100%) is the e…";
CM_ SG_ 2365402878 Jstk5XAxsDtntPstnStts "Reports when the current joystick position is in the detent position for that axis of travel.00b = Not in the Detent Position01b = In the Detent Position10b = E…";
CM_ SG_ 2365402878 Jstk5XAxsLvrLftNgtvPstnStts "Reports when the current joystick position is on the negative travel side (back, left, counterclockwise, down) relative to the neutral position for that axis of…";
CM_ SG_ 2365402878 Jstk5XAxsLvrRghtPstvPstnStts "Reports when the current joystick position is on the positive travel side (forward, right, clockwise, up) relative to the neutral position for that axis of trav…";
CM_ SG_ 2365402878 Jstk5XAxsNtrlPstnStts "Reports when the current joystick position is in the neutral position for that axis of travel.  The neutral position measurement must be determined from some me…";
CM_ SG_ 2365402878 Jstk5YAxsDtntPstnStts "Reports when the current joystick position is in the detent position for that axis of travel.00b = Not in the Detent Position01b = In the Detent Position10b = E…";
CM_ SG_ 2365402878 Jstk5YAxsLvrBkNgtvPstnStts "Reports when the current joystick position is on the negative travel side (back, left, counterclockwise, down) relative to the neutral position for that axis of…";
CM_ SG_ 2365402878 Jstk5YAxsLvrFrwrdPstvPstnStts "Reports when the current joystick position is on the positive travel side (forward, right, clockwise, up) relative to the neutral position for that axis of trav…";
CM_ SG_ 2365402878 Jstk5YAxsNtrlPstnStts "Reports when the current joystick position is in the neutral position for that axis of travel.  The neutral position measurement must be determined from some me…";
CM_ BO_ 2365403134 "Extended Joystick Message 4";
CM_ SG_ 2365403134 Joystick4Button13PressedStatus "Reports when the joystick button has been pressed.00b = Button not pressed01b = Button pressed10b = Error Indicator11b = Not Available…";
CM_ SG_ 2365403134 Joystick4Button14PressedStatus "Reports when the joystick button has been pressed.00b = Button not pressed01b = Button pressed10b = Error Indicator11b = Not Available…";
CM_ SG_ 2365403134 Joystick4Button15PressedStatus "Reports when the joystick button has been pressed.00b = Button not pressed01b = Button pressed10b = Error Indicator11b = Not Available…";
CM_ SG_ 2365403134 Joystick4Button16PressedStatus "Reports when the joystick button has been pressed.00b = Button not pressed01b = Button pressed10b = Error Indicator11b = Not Available…";
CM_ SG_ 2365403134 Joystick4GripXAxisPosition "The position of the joystick grip in the relative motion of travel from the neutral position.  Position value of 0 is Neutral and position value 1000 (100%) is …";
CM_ SG_ 2365403134 Joystick4GripYAxisPosition "The position of the joystick grip in the relative motion of travel from the neutral position.  Position value of 0 is Neutral and position value 1000 (100%) is …";
CM_ SG_ 2365403134 Joystick4ThetaAxisPosition "The position of the joystick in the relative motion of travel from the neutral position.  Position value of 0 is Neutral and position value 1000 (100%) is the e…";
CM_ SG_ 2365403134 Jst4GpYAxsLvFwdPstvPstStts "Reports when the current joystick grip position is on the positive travel side (forward, right, clockwise, up) relative to the neutral position for that axis of…";
CM_ SG_ 2365403134 Jst4TtAxsCtCwsNtvPstStts "Reports when the current joystick position is on the negative travel side (back, left, counterclockwise, down) relative to the neutral position for that axis of…";
CM_ SG_ 2365403134 Jstk4GrpXAxsDtntPstnStts "Reports when the current joystick grip position is in the detent position for that axis of travel.00b = Not in the Detent Position01b = In the Detent Position10…";
CM_ SG_ 2365403134 Jstk4GrpXAxsLvrLftNgtvPstnStts "Reports when the current joystick grip position is on the negative travel side (back, left, counterclockwise, down) relative to the neutral position for that ax…";
CM_ SG_ 2365403134 Jstk4GrpXAxsLvrRghtPstvPstnStts "Reports when the current joystick grip position is on the positive travel side (forward, right, clockwise, up) relative to the neutral position for that axis of…";
CM_ SG_ 2365403134 Jstk4GrpXAxsNtrlPstnStts "Reports when the current joystick grip position is in the neutral position for that axis of travel.  The neutral position measurement must be determined from so…";
CM_ SG_ 2365403134 Jstk4GrpYAxsDtntPstnStts "Reports when the current joystick grip position is in the detent position for that axis of travel.00b = Not in the Detent Position01b = In the Detent Position10…";
CM_ SG_ 2365403134 Jstk4GrpYAxsLvrBkNgtvPstnStts "Reports when the current joystick grip position is on the negative travel side (back, left, counterclockwise, down) relative to the neutral position for that ax…";
CM_ SG_ 2365403134 Jstk4GrpYAxsNtrlPstnStts "Reports when the current joystick grip position is in the neutral position for that axis of travel.  The neutral position measurement must be determined from so…";
CM_ SG_ 2365403134 Jstk4ThtAxsClkwsPstvPstnStts "Reports when the current joystick position is on the positive travel side (forward, right, clockwise, up) relative to the neutral position for that axis of trav…";
CM_ SG_ 2365403134 Jstk4ThtAxsDtntPstnStts "Reports when the current joystick position is in the detent position for that axis of travel.00b = Not in the Detent Position01b = In the Detent Position10b = E…";
CM_ SG_ 2365403134 Jstk4ThtAxsNtrlPstnStts "Reports when the current joystick position is in the neutral position for that axis of travel.  The neutral position measurement must be determined from some me…";
CM_ BO_ 2365403390 "Basic Joystick Message 4";
CM_ SG_ 2365403390 Joystick4Button10PressedStatus "Reports when the joystick button has been pressed.00b = Button not pressed01b = Button pressed10b = Error Indicator11b = Not Available…";
CM_ SG_ 2365403390 Joystick4Button11PressedStatus "Reports when the joystick button has been pressed.00b = Button not pressed01b = Button pressed10b = Error Indicator11b = Not Available…";
CM_ SG_ 2365403390 Joystick4Button12PressedStatus "Reports when the joystick button has been pressed.00b = Button not pressed01b = Button pressed10b = Error Indicator11b = Not Available…";
CM_ SG_ 2365403390 Joystick4Button1PressedStatus "Reports when the joystick button has been pressed.00b = Button not pressed01b = Button pressed10b = Error Indicator11b = Not Available…";
CM_ SG_ 2365403390 Joystick4Button2PressedStatus "Reports when the joystick button has been pressed.00b = Button not pressed01b = Button pressed10b = Error Indicator11b = Not Available…";
CM_ SG_ 2365403390 Joystick4Button3PressedStatus "Reports when the joystick button has been pressed.00b = Button not pressed01b = Button pressed10b = Error Indicator11b = Not Available…";
CM_ SG_ 2365403390 Joystick4Button4PressedStatus "Reports when the joystick button has been pressed.00b = Button not pressed01b = Button pressed10b = Error Indicator11b = Not Available…";
CM_ SG_ 2365403390 Joystick4Button5PressedStatus "Reports when the joystick button has been pressed.00b = Button not pressed01b = Button pressed10b = Error Indicator11b = Not Available…";
CM_ SG_ 2365403390 Joystick4Button6PressedStatus "Reports when the joystick button has been pressed.00b = Button not pressed01b = Button pressed10b = Error Indicator11b = Not Available…";
CM_ SG_ 2365403390 Joystick4Button7PressedStatus "Reports when the joystick button has been pressed.00b = Button not pressed01b = Button pressed10b = Error Indicator11b = Not Available…";
CM_ SG_ 2365403390 Joystick4Button8PressedStatus "Reports when the joystick button has been pressed.00b = Button not pressed01b = Button pressed10b = Error Indicator11b = Not Available…";
CM_ SG_ 2365403390 Joystick4Button9PressedStatus "Reports when the joystick button has been pressed.00b = Button not pressed01b = Button pressed10b = Error Indicator11b = Not Available…";
CM_ SG_ 2365403390 Joystick4XAxisPosition "The position of the joystick in the relative motion of travel from the neutral position.  Position value of 0 is Neutral and position value 1000 (100%) is the e…";
CM_ SG_ 2365403390 Joystick4YAxisPosition "The position of the joystick in the relative motion of travel from the neutral position.  Position value of 0 is Neutral and position value 1000 (100%) is the e…";
CM_ SG_ 2365403390 Jstk4XAxsDtntPstnStts "Reports when the current joystick position is in the detent position for that axis of travel.00b = Not in the Detent Position01b = In the Detent Position10b = E…";
CM_ SG_ 2365403390 Jstk4XAxsLvrLftNgtvPstnStts "Reports when the current joystick position is on the negative travel side (back, left, counterclockwise, down) relative to the neutral position for that axis of…";
CM_ SG_ 2365403390 Jstk4XAxsLvrRghtPstvPstnStts "Reports when the current joystick position is on the positive travel side (forward, right, clockwise, up) relative to the neutral position for that axis of trav…";
CM_ SG_ 2365403390 Jstk4XAxsNtrlPstnStts "Reports when the current joystick position is in the neutral position for that axis of travel.  The neutral position measurement must be determined from some me…";
CM_ SG_ 2365403390 Jstk4YAxsDtntPstnStts "Reports when the current joystick position is in the detent position for that axis of travel.00b = Not in the Detent Position01b = In the Detent Position10b = E…";
CM_ SG_ 2365403390 Jstk4YAxsLvrBkNgtvPstnStts "Reports when the current joystick position is on the negative travel side (back, left, counterclockwise, down) relative to the neutral position for that axis of…";
CM_ SG_ 2365403390 Jstk4YAxsLvrFrwrdPstvPstnStts "Reports when the current joystick position is on the positive travel side (forward, right, clockwise, up) relative to the neutral position for that axis of trav…";
CM_ SG_ 2365403390 Jstk4YAxsNtrlPstnStts "Reports when the current joystick position is in the neutral position for that axis of travel.  The neutral position measurement must be determined from some me…";
CM_ BO_ 2365428478 "Engine Operating Information";
CM_ SG_ 2365428478 EngineControlledShutdownRequest "A signal issued by the engine control system to a user or external system requesting for a controlled shutdown.  This request is made when engine protection dia…";
CM_ SG_ 2365428478 EngineCoolantPumpControl "Control setting for an electrically actuated engine coolant circulating pump. 00b = Off01b = On10b = Reserved11b = Don't care / take no action.…";
CM_ SG_ 2365428478 EngineDerateRequest "This parameter is a derate request made from the engine control system to an external system, where the engine is requesting an external device to reduce the lo…";
CM_ SG_ 2365428478 EngineDesiredTorqueRequest "This is the torque that the ECM desires to provide. It is a request made from the ECM to an external system. A valid value within the operating range indicates …";
CM_ SG_ 2365428478 EngineFuelShutoff1Control "Control setting for fuel shutoff 1.  The second instance is SPN 2807.  For a single fuel shutoff system, this represents its commanded position.  For a dual fue…";
CM_ SG_ 2365428478 EngineFuelShutoff2Control "Control setting for fuel shutoff 2.  First instance is SPN 632.  For a dual fuel shutoff system, this SPN is representative of the downstream fuel shutoff comma…";
CM_ SG_ 2365428478 EngineFuelShutoffVentControl "Control setting for a fuel shutoff vent.  Typically, for a dual fuel shutoff system, the vent line is located between them and is plumbed to vent outside to atm…";
CM_ SG_ 2365428478 EngineOilPreheaterControl "Control setting for an electrically actuated oil pre-heating device.00b = Off01b = On10b = Reserved11b = Don't care / take no actionIn addition to communicating…";
CM_ SG_ 2365428478 EngineOilPrimingPumpControl "This control is used to activate a pump that lubricates the engine, particularly prior to initial engine startup.00b = Off01b = On10b = Reserved11b = unavailabl…";
CM_ SG_ 2365428478 EngineOperatingState "This parameter is used to indicate the current state, or mode, of operation by the engine.  This is a status parameter.0000b = Engine Stopped0001b = Pre-Start00…";
CM_ SG_ 2365428478 EnginePreHeaterControl "Control setting for an electrically actuated engine block or coolant pre-heating device.00b = Off 01b = On10b = Reserved11b = Unavailable…";
CM_ SG_ 2365428478 EngineStarterMotorRelayControl "Command signal used to energize or de-energize the engine starter motor relay.00b = Off01b = On10b = Reserved for SAE assignment11b = Don't care/take no action…";
CM_ SG_ 2365428478 EngnCldAmntElvtdIdlStts "Indicates that the engine is elevating the idle speed due to cold strategies.00b = No Idle Elevation Active - standard idle speed01b = Idle Elevation Active10b …";
CM_ SG_ 2365428478 EngnEltrlSstmPwrCnsrvtnCntrl "Control setting for cutting power to various devices when the engine is not in use.  Useful if it is desired to keep the engine in standby, with main control EC…";
CM_ SG_ 2365428478 EngnEmrgnImmdtShtdwnIndtn "A signal issued by the engine control system to a user or external system indicating that it is immediately shutting the engine down.  This indication is made w…";
CM_ SG_ 2365428478 EngnFlShtffVlvLkTstCntrl "Control setting for fuel shutoff valve proving system test.  Typically, this type of system can only be used with a dual fuel shutoff system.  The test consists…";
CM_ SG_ 2365428478 FuelPumpPrimerControl "Parameter used to activate or deactivate a priming system on the fuel transfer system. The fuel priming system is a system that purges air in the fuel lines and…";
CM_ SG_ 2365428478 TmRmnngnEngnOprtngStt "This parameter is used to indicate the time remaining in the current engine operating state, based on the state defined in the SPN Engine Operating State (SPN 3…";
CM_ BO_ 2365428734 "Generator Control 1";
CM_ SG_ 2365428734 EngineSpeedGovernorDroop "This is the percent speed droop adjustment relative to rated speed setpoint. The Engine Speed Droop is equal to the following equation: 100*[(Engine Speed at no…";
CM_ SG_ 2365428734 EngineSpeedGovernorGainAdjust "This parameter is used to adjust multiple gains at same time to attain engine stability across a broader range of applications.  -32128 is least responsive0 is …";
CM_ SG_ 2365428734 GeneratorAlternatorEfficiency "Measured, calculated, and/or estimated operating efficiency of the generator alternator.  Percentage reflects ratio of power output divided by power input, mult…";
CM_ SG_ 2365428734 GeneratorFrequencySelection "Command from user and/or generator control system for the genset (engine) to target operations for 50 Hz, 60 Hz, or 400 Hz.0000b = 50 Hz0001b = 60 Hz0010b = 400…";
CM_ SG_ 2365428734 GeneratorGoverningSpeedCommand "Command from user and/or generator control system for the genset (engine) to govern to low idle or rated base speed setpoints.  If this method of engine control…";
CM_ SG_ 2365428734 GnrtrCntrlNtInAtmtStrtStt "This parameter indicates whether or not the generator set is in a condition to automatically start up and provide power. If not, this status parameter is in the…";
CM_ SG_ 2365428734 GnrtrNtRdtAtmtllPrlllStt "This parameter indicates whether or not all systems required to start the engine and close to the bus are prepared to operate automatically. If not, the generat…";
CM_ SG_ 2365428734 RequestedEngineControlMode "This parameter is used to request a change to the engine control mode.  This is a status parameter.  0000b = Normal Engine Shutdown0001b = Rapid Engine Shutdown…";
CM_ BO_ 2365433598 "Voltage Regulator Excitation Status";
CM_ SG_ 2365433598 GeneratorExcitationFieldCurrent "Measured signal that represents the generator excitation field current.…";
CM_ SG_ 2365433598 GeneratorExcitationFieldVoltage "Measured signal that represents the generator excitation field voltage.  Generator excitation field voltage is indicative of the amount of excitation current be…";
CM_ SG_ 2365433598 GnrtrOtptVltgBsPrntg "Measured signal that represents the voltage bias percentage of the generator ouptput voltage being requested by external to the voltage regulator.  Generator ou…";
CM_ BO_ 2365443326 "Operators External Light Controls Message";
CM_ SG_ 2365443326 HazardLightSwitch "A 2 bit parameter to indicate the selected position of the operator's hazard light switch.00b = Hazard Lamps to be Off01b = Hazard Lamps to be Flashing10b = Err…";
CM_ SG_ 2365443326 HighLowBeamSwitch "A 2 bit parameter to indicate the selected position of the operator's high/low beam select switch.00b = Low Beam Selected01b = High Beam Selected10b = Error11b …";
CM_ SG_ 2365443326 MainLightSwitch "A 4 bit parameter to indicate the selected position of the operator's main light switch.0000b = Off - The position by which the operator selects that none of th…";
CM_ SG_ 2365443326 OperatorsDesiredBacklight "A 8 bit parameter to indicate the level of back lighting the operator has selected for displays.  This is to be differentiated from the Illumination Brightness …";
CM_ SG_ 2365443326 OprtrsDsrdDldLmpOffTm "A 16 bit parameter to be associated with Delayed Off position (1000b) of the Main Light Switch.  This parameter indicates the time the operator wishes to have e…";
CM_ SG_ 2365443326 TurnSignalSwitch "A 4 bit parameter to indicate the selected position of the operator's turn signal switch.0000b = No Turn being signaled0001b = Left Turn to be Flashing0010b = R…";
CM_ SG_ 2365443326 WorkLightSwitch "A 4 bit parameter to indicate the selected position of the operator's work light switch. In Ag applications the work lights are often refereed to as field light…";
CM_ BO_ 2365445886 "Basic Joystick Message 1";
CM_ SG_ 2365445886 Joystick1Button10PressedStatus "Reports when the joystick button has been pressed.00b = Button not pressed01b = Button pressed10b = Error Indicator11b = Not Available…";
CM_ SG_ 2365445886 Joystick1Button11PressedStatus "Reports when the joystick button has been pressed.00b = Button not pressed01b = Button pressed10b = Error Indicator11b = Not Available…";
CM_ SG_ 2365445886 Joystick1Button12PressedStatus "Reports when the joystick button has been pressed.00b = Button not pressed01b = Button pressed10b = Error Indicator11b = Not Available…";
CM_ SG_ 2365445886 Joystick1Button1PressedStatus "Reports when the joystick button has been pressed.00b = Button not pressed01b = Button pressed10b = Error Indicator11b = Not Available…";
CM_ SG_ 2365445886 Joystick1Button2PressedStatus "Reports when the joystick button has been pressed.00b = Button not pressed01b = Button pressed10b = Error Indicator11b = Not Available…";
CM_ SG_ 2365445886 Joystick1Button3PressedStatus "Reports when the joystick button has been pressed.00b = Button not pressed01b = Button pressed10b = Error Indicator11b = Not Available…";
CM_ SG_ 2365445886 Joystick1Button4PressedStatus "Reports when the joystick button has been pressed.00b = Button not pressed01b = Button pressed10b = Error Indicator11b = Not Available…";
CM_ SG_ 2365445886 Joystick1Button5PressedStatus "Reports when the joystick button has been pressed.00b = Button not pressed01b = Button pressed10b = Error Indicator11b = Not Available…";
CM_ SG_ 2365445886 Joystick1Button6PressedStatus "Reports when the joystick button has been pressed.00b = Button not pressed01b = Button pressed10b = Error Indicator11b = Not Available…";
CM_ SG_ 2365445886 Joystick1Button7PressedStatus "Reports when the joystick button has been pressed.00b = Button not pressed01b = Button pressed10b = Error Indicator11b = Not Available…";
CM_ SG_ 2365445886 Joystick1Button8PressedStatus "Reports when the joystick button has been pressed.00b = Button not pressed01b = Button pressed10b = Error Indicator11b = Not Available…";
CM_ SG_ 2365445886 Joystick1Button9PressedStatus "Reports when the joystick button has been pressed.00b = Button not pressed01b = Button pressed10b = Error Indicator11b = Not Available…";
CM_ SG_ 2365445886 Joystick1XAxisPosition "The position of the joystick in the relative motion of travel from the neutral position.  Position value of 0 is Neutral and position value 1000 (100%) is the e…";
CM_ SG_ 2365445886 Joystick1YAxisPosition "The position of the joystick in the relative motion of travel from the neutral position.  Position value of 0 is Neutral and position value 1000 (100%) is the e…";
CM_ SG_ 2365445886 Jstk1XAxsDtntPstnStts "Reports when the current joystick position is in the detent position for that axis of travel.00b = Not in the Detent Position01b = In the Detent Position10b = E…";
CM_ SG_ 2365445886 Jstk1XAxsLvrLftNgtvPstnStts "Reports when the current joystick position is on the negative travel side (back, left, counterclockwise, down) relative to the neutral position for that axis of…";
CM_ SG_ 2365445886 Jstk1XAxsLvrRghtPstvPstnStts "Reports when the current joystick position is on the positive travel side (forward, right, clockwise, up) relative to the neutral position for that axis of trav…";
CM_ SG_ 2365445886 Jstk1XAxsNtrlPstnStts "Reports when the current joystick position is in the neutral position for that axis of travel.  The neutral position measurement must be determined from some me…";
CM_ SG_ 2365445886 Jstk1YAxsDtntPstnStts "Reports when the current joystick position is in the detent position for that axis of travel.00b = Not in the Detent Position01b = In the Detent Position10b = E…";
CM_ SG_ 2365445886 Jstk1YAxsLvrBkNgtvPstnStts "Reports when the current joystick position is on the negative travel side (back, left, counterclockwise, down) relative to the neutral position for that axis of…";
CM_ SG_ 2365445886 Jstk1YAxsLvrFrwrdPstvPstnStts "Reports when the current joystick position is on the positive travel side (forward, right, clockwise, up) relative to the neutral position for that axis of trav…";
CM_ SG_ 2365445886 Jstk1YAxsNtrlPstnStts "Reports when the current joystick position is in the neutral position for that axis of travel.  The neutral position measurement must be determined from some me…";
CM_ BO_ 2365446142 "Extended Joystick Message 1";
CM_ SG_ 2365446142 Joystick1Button13PressedStatus "Reports when the joystick button has been pressed.00b = Button not pressed01b = Button pressed10b = Error Indicator11b = Not Available…";
CM_ SG_ 2365446142 Joystick1Button14PressedStatus "Reports when the joystick button has been pressed.00b = Button not pressed01b = Button pressed10b = Error Indicator11b = Not Available…";
CM_ SG_ 2365446142 Joystick1Button15PressedStatus "Reports when the joystick button has been pressed.00b = Button not pressed01b = Button pressed10b = Error Indicator11b = Not Available…";
CM_ SG_ 2365446142 Joystick1Button16PressedStatus "Reports when the joystick button has been pressed.00b = Button not pressed01b = Button pressed10b = Error Indicator11b = Not Available…";
CM_ SG_ 2365446142 Joystick1GripXAxisPosition "The position of the joystick grip in the relative motion of travel from the neutral position.  Position value of 0 is Neutral and position value 1000 (100%) is …";
CM_ SG_ 2365446142 Joystick1GripYAxisPosition "The position of the joystick grip in the relative motion of travel from the neutral position.  Position value of 0 is Neutral and position value 1000 (100%) is …";
CM_ SG_ 2365446142 Joystick1ThetaAxisPosition "The position of the joystick in the relative motion of travel from the neutral position.  Position value of 0 is Neutral and position value 1000 (100%) is the e…";
CM_ SG_ 2365446142 Jst1GpYAxsLvFwdPstvPstStts "Reports when the current joystick grip position is on the positive travel side (forward, right, clockwise, up) relative to the neutral position for that axis of…";
CM_ SG_ 2365446142 Jst1TtAxsCtCwsNtvPstStts "Reports when the current joystick position is on the negative travel side (back, left, counterclockwise, down) relative to the neutral position for that axis of…";
CM_ SG_ 2365446142 Jstk1GrpXAxsDtntPstnStts "Reports when the current joystick grip position is in the detent position for that axis of travel.00b = Not in the Detent Position01b = In the Detent Position10…";
CM_ SG_ 2365446142 Jstk1GrpXAxsLvrLftNgtvPstnStts "Reports when the current joystick grip position is on the negative travel side (back, left, counterclockwise, down) relative to the neutral position for that ax…";
CM_ SG_ 2365446142 Jstk1GrpXAxsLvrRghtPstvPstnStts "Reports when the current joystick grip position is on the positive travel side (forward, right, clockwise, up) relative to the neutral position for that axis of…";
CM_ SG_ 2365446142 Jstk1GrpXAxsNtrlPstnStts "Reports when the current joystick grip position is in the neutral position for that axis of travel.  The neutral position measurement must be determined from so…";
CM_ SG_ 2365446142 Jstk1GrpYAxsDtntPstnStts "Reports when the current joystick grip position is in the detent position for that axis of travel.00b = Not in the Detent Position01b = In the Detent Position10…";
CM_ SG_ 2365446142 Jstk1GrpYAxsLvrBkNgtvPstnStts "Reports when the current joystick grip position is on the negative travel side (back, left, counterclockwise, down) relative to the neutral position for that ax…";
CM_ SG_ 2365446142 Jstk1GrpYAxsNtrlPstnStts "Reports when the current joystick grip position is in the neutral position for that axis of travel.  The neutral position measurement must be determined from so…";
CM_ SG_ 2365446142 Jstk1ThtAxsClkwsPstvPstnStts "Reports when the current joystick position is on the positive travel side (forward, right, clockwise, up) relative to the neutral position for that axis of trav…";
CM_ SG_ 2365446142 Jstk1ThtAxsDtntPstnStts "Reports when the current joystick position is in the detent position for that axis of travel.00b = Not in the Detent Position01b = In the Detent Position10b = E…";
CM_ SG_ 2365446142 Jstk1ThtAxsNtrlPstnStts "Reports when the current joystick position is in the neutral position for that axis of travel.  The neutral position measurement must be determined from some me…";
CM_ BO_ 2365446398 "Basic Joystick Message 2";
CM_ SG_ 2365446398 Joystick2Button10PressedStatus "Reports when the joystick button has been pressed.00b = Button not pressed01b = Button pressed10b = Error Indicator11b = Not Available…";
CM_ SG_ 2365446398 Joystick2Button11PressedStatus "Reports when the joystick button has been pressed.00b = Button not pressed01b = Button pressed10b = Error Indicator11b = Not Available…";
CM_ SG_ 2365446398 Joystick2Button12PressedStatus "Reports when the joystick button has been pressed.00b = Button not pressed01b = Button pressed10b = Error Indicator11b = Not Available…";
CM_ SG_ 2365446398 Joystick2Button1PressedStatus "Reports when the joystick button has been pressed.00b = Button not pressed01b = Button pressed10b = Error Indicator11b = Not Available…";
CM_ SG_ 2365446398 Joystick2Button2PressedStatus "Reports when the joystick button has been pressed.00b = Button not pressed01b = Button pressed10b = Error Indicator11b = Not Available…";
CM_ SG_ 2365446398 Joystick2Button3PressedStatus "Reports when the joystick button has been pressed.00b = Button not pressed01b = Button pressed10b = Error Indicator11b = Not Available…";
CM_ SG_ 2365446398 Joystick2Button4PressedStatus "Reports when the joystick button has been pressed.00b = Button not pressed01b = Button pressed10b = Error Indicator11b = Not Available…";
CM_ SG_ 2365446398 Joystick2Button5PressedStatus "Reports when the joystick button has been pressed.00b = Button not pressed01b = Button pressed10b = Error Indicator11b = Not Available…";
CM_ SG_ 2365446398 Joystick2Button6PressedStatus "Reports when the joystick button has been pressed.00b = Button not pressed01b = Button pressed10b = Error Indicator11b = Not Available…";
CM_ SG_ 2365446398 Joystick2Button7PressedStatus "Reports when the joystick button has been pressed.00b = Button not pressed01b = Button pressed10b = Error Indicator11b = Not Available…";
CM_ SG_ 2365446398 Joystick2Button8PressedStatus "Reports when the joystick button has been pressed.00b = Button not pressed01b = Button pressed10b = Error Indicator11b = Not Available…";
CM_ SG_ 2365446398 Joystick2Button9PressedStatus "Reports when the joystick button has been pressed.00b = Button not pressed01b = Button pressed10b = Error Indicator11b = Not Available…";
CM_ SG_ 2365446398 Joystick2XAxisPosition "The position of the joystick in the relative motion of travel from the neutral position.  Position value of 0 is Neutral and position value 1000 (100%) is the e…";
CM_ SG_ 2365446398 Joystick2YAxisPosition "The position of the joystick in the relative motion of travel from the neutral position.  Position value of 0 is Neutral and position value 1000 (100%) is the e…";
CM_ SG_ 2365446398 Jstk2XAxsDtntPstnStts "Reports when the current joystick position is in the detent position for that axis of travel.00b = Not in the Detent Position01b = In the Detent Position10b = E…";
CM_ SG_ 2365446398 Jstk2XAxsLvrLftNgtvPstnStts "Reports when the current joystick position is on the negative travel side (back, left, counterclockwise, down) relative to the neutral position for that axis of…";
CM_ SG_ 2365446398 Jstk2XAxsLvrRghtPstvPstnStts "Reports when the current joystick position is on the positive travel side (forward, right, clockwise, up) relative to the neutral position for that axis of trav…";
CM_ SG_ 2365446398 Jstk2XAxsNtrlPstnStts "Reports when the current joystick position is in the neutral position for that axis of travel.  The neutral position measurement must be determined from some me…";
CM_ SG_ 2365446398 Jstk2YAxsDtntPstnStts "Reports when the current joystick position is in the detent position for that axis of travel.00b = Not in the Detent Position01b = In the Detent Position10b = E…";
CM_ SG_ 2365446398 Jstk2YAxsLvrBkNgtvPstnStts "Reports when the current joystick position is on the negative travel side (back, left, counterclockwise, down) relative to the neutral position for that axis of…";
CM_ SG_ 2365446398 Jstk2YAxsLvrFrwrdPstvPstnStts "Reports when the current joystick position is on the positive travel side (forward, right, clockwise, up) relative to the neutral position for that axis of trav…";
CM_ SG_ 2365446398 Jstk2YAxsNtrlPstnStts "Reports when the current joystick position is in the neutral position for that axis of travel.  The neutral position measurement must be determined from some me…";
CM_ BO_ 2365446654 "Extended Joystick Message 2";
CM_ SG_ 2365446654 Joystick2Button13PressedStatus "Reports when the joystick button has been pressed.00b = Button not pressed01b = Button pressed10b = Error Indicator11b = Not Available…";
CM_ SG_ 2365446654 Joystick2Button14PressedStatus "Reports when the joystick button has been pressed.00b = Button not pressed01b = Button pressed10b = Error Indicator11b = Not Available…";
CM_ SG_ 2365446654 Joystick2Button15PressedStatus "Reports when the joystick button has been pressed.00b = Button not pressed01b = Button pressed10b = Error Indicator11b = Not Available…";
CM_ SG_ 2365446654 Joystick2Button16PressedStatus "Reports when the joystick button has been pressed.00b = Button not pressed01b = Button pressed10b = Error Indicator11b = Not Available…";
CM_ SG_ 2365446654 Joystick2GripXAxisPosition "The position of the joystick grip in the relative motion of travel from the neutral position.  Position value of 0 is Neutral and position value 1000 (100%) is …";
CM_ SG_ 2365446654 Joystick2GripYAxisPosition "The position of the joystick grip in the relative motion of travel from the neutral position.  Position value of 0 is Neutral and position value 1000 (100%) is …";
CM_ SG_ 2365446654 Joystick2ThetaAxisPosition "The position of the joystick in the relative motion of travel from the neutral position.  Position value of 0 is Neutral and position value 1000 (100%) is the e…";
CM_ SG_ 2365446654 Jst2GpYAxsLvFwdPstvPstStts "Reports when the current joystick grip position is on the positive travel side (forward, right, clockwise, up) relative to the neutral position for that axis of…";
CM_ SG_ 2365446654 Jst2TtAxsCtCwsNtvPstStts "Reports when the current joystick position is on the negative travel side (back, left, counterclockwise, down) relative to the neutral position for that axis of…";
CM_ SG_ 2365446654 Jstk2GrpXAxsDtntPstnStts "Reports when the current joystick grip position is in the detent position for that axis of travel.00b = Not in the Detent Position01b = In the Detent Position10…";
CM_ SG_ 2365446654 Jstk2GrpXAxsLvrLftNgtvPstnStts "Reports when the current joystick grip position is on the negative travel side (back, left, counterclockwise, down) relative to the neutral position for that ax…";
CM_ SG_ 2365446654 Jstk2GrpXAxsLvrRghtPstvPstnStts "Reports when the current joystick grip position is on the positive travel side (forward, right, clockwise, up) relative to the neutral position for that axis of…";
CM_ SG_ 2365446654 Jstk2GrpXAxsNtrlPstnStts "Reports when the current joystick grip position is in the neutral position for that axis of travel.  The neutral position measurement must be determined from so…";
CM_ SG_ 2365446654 Jstk2GrpYAxsDtntPstnStts "Reports when the current joystick grip position is in the detent position for that axis of travel.00b = Not in the Detent Position01b = In the Detent Position10…";
CM_ SG_ 2365446654 Jstk2GrpYAxsLvrBkNgtvPstnStts "Reports when the current joystick grip position is on the negative travel side (back, left, counterclockwise, down) relative to the neutral position for that ax…";
CM_ SG_ 2365446654 Jstk2GrpYAxsNtrlPstnStts "Reports when the current joystick grip position is in the neutral position for that axis of travel.  The neutral position measurement must be determined from so…";
CM_ SG_ 2365446654 Jstk2ThtAxsClkwsPstvPstnStts "Reports when the current joystick position is on the positive travel side (forward, right, clockwise, up) relative to the neutral position for that axis of trav…";
CM_ SG_ 2365446654 Jstk2ThtAxsDtntPstnStts "Reports when the current joystick position is in the detent position for that axis of travel.00b = Not in the Detent Position01b = In the Detent Position10b = E…";
CM_ SG_ 2365446654 Jstk2ThtAxsNtrlPstnStts "Reports when the current joystick position is in the neutral position for that axis of travel.  The neutral position measurement must be determined from some me…";
CM_ BO_ 2365446910 "Basic Joystick Message 3";
CM_ SG_ 2365446910 Joystick3Button10PressedStatus "Reports when the joystick button has been pressed.00b = Button not pressed01b = Button pressed10b = Error Indicator11b = Not Available…";
CM_ SG_ 2365446910 Joystick3Button11PressedStatus "Reports when the joystick button has been pressed.00b = Button not pressed01b = Button pressed10b = Error Indicator11b = Not Available…";
CM_ SG_ 2365446910 Joystick3Button12PressedStatus "Reports when the joystick button has been pressed.00b = Button not pressed01b = Button pressed10b = Error Indicator11b = Not Available…";
CM_ SG_ 2365446910 Joystick3Button1PressedStatus "Reports when the joystick button has been pressed.00b = Button not pressed01b = Button pressed10b = Error Indicator11b = Not Available…";
CM_ SG_ 2365446910 Joystick3Button2PressedStatus "Reports when the joystick button has been pressed.00b = Button not pressed01b = Button pressed10b = Error Indicator11b = Not Available…";
CM_ SG_ 2365446910 Joystick3Button3PressedStatus "Reports when the joystick button has been pressed.00b = Button not pressed01b = Button pressed10b = Error Indicator11b = Not Available…";
CM_ SG_ 2365446910 Joystick3Button4PressedStatus "Reports when the joystick button has been pressed.00b = Button not pressed01b = Button pressed10b = Error Indicator11b = Not Available…";
CM_ SG_ 2365446910 Joystick3Button5PressedStatus "Reports when the joystick button has been pressed.00b = Button not pressed01b = Button pressed10b = Error Indicator11b = Not Available…";
CM_ SG_ 2365446910 Joystick3Button6PressedStatus "Reports when the joystick button has been pressed.00b = Button not pressed01b = Button pressed10b = Error Indicator11b = Not Available…";
CM_ SG_ 2365446910 Joystick3Button7PressedStatus "Reports when the joystick button has been pressed.00b = Button not pressed01b = Button pressed10b = Error Indicator11b = Not Available…";
CM_ SG_ 2365446910 Joystick3Button8PressedStatus "Reports when the joystick button has been pressed.00b = Button not pressed01b = Button pressed10b = Error Indicator11b = Not Available…";
CM_ SG_ 2365446910 Joystick3Button9PressedStatus "Reports when the joystick button has been pressed.00b = Button not pressed01b = Button pressed10b = Error Indicator11b = Not Available…";
CM_ SG_ 2365446910 Joystick3XAxisPosition "The position of the joystick in the relative motion of travel from the neutral position.  Position value of 0 is Neutral and position value 1000 (100%) is the e…";
CM_ SG_ 2365446910 Joystick3YAxisPosition "The position of the joystick in the relative motion of travel from the neutral position.  Position value of 0 is Neutral and position value 1000 (100%) is the e…";
CM_ SG_ 2365446910 Jstk3XAxsDtntPstnStts "Reports when the current joystick position is in the detent position for that axis of travel.00b = Not in the Detent Position01b = In the Detent Position10b = E…";
CM_ SG_ 2365446910 Jstk3XAxsLvrLftNgtvPstnStts "Reports when the current joystick position is on the negative travel side (back, left, counterclockwise, down) relative to the neutral position for that axis of…";
CM_ SG_ 2365446910 Jstk3XAxsLvrRghtPstvPstnStts "Reports when the current joystick position is on the positive travel side (forward, right, clockwise, up) relative to the neutral position for that axis of trav…";
CM_ SG_ 2365446910 Jstk3XAxsNtrlPstnStts "Reports when the current joystick position is in the neutral position for that axis of travel.  The neutral position measurement must be determined from some me…";
CM_ SG_ 2365446910 Jstk3YAxsDtntPstnStts "Reports when the current joystick position is in the detent position for that axis of travel.00b = Not in the Detent Position01b = In the Detent Position10b = E…";
CM_ SG_ 2365446910 Jstk3YAxsLvrBkNgtvPstnStts "Reports when the current joystick position is on the negative travel side (back, left, counterclockwise, down) relative to the neutral position for that axis of…";
CM_ SG_ 2365446910 Jstk3YAxsLvrFrwrdPstvPstnStts "Reports when the current joystick position is on the positive travel side (forward, right, clockwise, up) relative to the neutral position for that axis of trav…";
CM_ SG_ 2365446910 Jstk3YAxsNtrlPstnStts "Reports when the current joystick position is in the neutral position for that axis of travel.  The neutral position measurement must be determined from some me…";
CM_ BO_ 2365447166 "Extended Joystick Message 3";
CM_ SG_ 2365447166 Joystick3Button13PressedStatus "Reports when the joystick button has been pressed.00b = Button not pressed01b = Button pressed10b = Error Indicator11b = Not Available…";
CM_ SG_ 2365447166 Joystick3Button14PressedStatus "Reports when the joystick button has been pressed.00b = Button not pressed01b = Button pressed10b = Error Indicator11b = Not Available…";
CM_ SG_ 2365447166 Joystick3Button15PressedStatus "Reports when the joystick button has been pressed.00b = Button not pressed01b = Button pressed10b = Error Indicator11b = Not Available…";
CM_ SG_ 2365447166 Joystick3Button16PressedStatus "Reports when the joystick button has been pressed.00b = Button not pressed01b = Button pressed10b = Error Indicator11b = Not Available…";
CM_ SG_ 2365447166 Joystick3GripXAxisPosition "The position of the joystick grip in the relative motion of travel from the neutral position.  Position value of 0 is Neutral and position value 1000 (100%) is …";
CM_ SG_ 2365447166 Joystick3GripYAxisPosition "The position of the joystick grip in the relative motion of travel from the neutral position.  Position value of 0 is Neutral and position value 1000 (100%) is …";
CM_ SG_ 2365447166 Joystick3ThetaAxisPosition "The position of the joystick in the relative motion of travel from the neutral position.  Position value of 0 is Neutral and position value 1000 (100%) is the e…";
CM_ SG_ 2365447166 Jst3GpYAxsLvFwdPstvPstStts "Reports when the current joystick grip position is on the positive travel side (forward, right, clockwise, up) relative to the neutral position for that axis of…";
CM_ SG_ 2365447166 Jst3TtAxsCtCwsNtvPstStts "Reports when the current joystick position is on the negative travel side (back, left, counterclockwise, down) relative to the neutral position for that axis of…";
CM_ SG_ 2365447166 Jstk3GrpXAxsDtntPstnStts "Reports when the current joystick grip position is in the detent position for that axis of travel.00b = Not in the Detent Position01b = In the Detent Position10…";
CM_ SG_ 2365447166 Jstk3GrpXAxsLvrLftNgtvPstnStts "Reports when the current joystick grip position is on the negative travel side (back, left, counterclockwise, down) relative to the neutral position for that ax…";
CM_ SG_ 2365447166 Jstk3GrpXAxsLvrRghtPstvPstnStts "Reports when the current joystick grip position is on the positive travel side (forward, right, clockwise, up) relative to the neutral position for that axis of…";
CM_ SG_ 2365447166 Jstk3GrpXAxsNtrlPstnStts "Reports when the current joystick grip position is in the neutral position for that axis of travel.  The neutral position measurement must be determined from so…";
CM_ SG_ 2365447166 Jstk3GrpYAxsDtntPstnStts "Reports when the current joystick grip position is in the detent position for that axis of travel.00b = Not in the Detent Position01b = In the Detent Position10…";
CM_ SG_ 2365447166 Jstk3GrpYAxsLvrBkNgtvPstnStts "Reports when the current joystick grip position is on the negative travel side (back, left, counterclockwise, down) relative to the neutral position for that ax…";
CM_ SG_ 2365447166 Jstk3GrpYAxsNtrlPstnStts "Reports when the current joystick grip position is in the neutral position for that axis of travel.  The neutral position measurement must be determined from so…";
CM_ SG_ 2365447166 Jstk3ThtAxsClkwsPstvPstnStts "Reports when the current joystick position is on the positive travel side (forward, right, clockwise, up) relative to the neutral position for that axis of trav…";
CM_ SG_ 2365447166 Jstk3ThtAxsDtntPstnStts "Reports when the current joystick position is in the detent position for that axis of travel.00b = Not in the Detent Position01b = In the Detent Position10b = E…";
CM_ SG_ 2365447166 Jstk3ThtAxsNtrlPstnStts "Reports when the current joystick position is in the neutral position for that axis of travel.  The neutral position measurement must be determined from some me…";
CM_ BO_ 2365449982 "Hydraulic Braking System";
CM_ SG_ 2365449982 HdrlBrkPrssrSpplSttCrt1 "Signal which indicates whether the hydraulic brake pressure supply of circuit 1 is reliable; that is, able to support continued braking.00b = Supply is not reli…";
CM_ SG_ 2365449982 HdrlBrkPrssrSpplSttCrt2 "Signal which indicates whether the hydraulic brake pressure supply of circuit 2 is reliable; that is, able to support continued braking.00b = Supply is not reli…";
CM_ SG_ 2365449982 HdrlBrkPrssrWrnngSttCrt1 "Signal which indicates whether the hydraulic brake pressure of circuit 1 is below the warning level00b = Pressure level sufficient01b = Pressure level below war…";
CM_ SG_ 2365449982 HdrlBrkPrssrWrnngSttCrt2 "Signal which indicates whether the hydraulic brake pressure of circuit 2 is below the warning level00b = Pressure level sufficient01b = Pressure level below war…";
CM_ SG_ 2365449982 HdrlBrkSstmAdlWrnngCmmnd "Signal which commands an audible warning by the hydraulic braking system.00b = Audible warning off01b = Audible warning on10b = Reserved11b = Don't care…";
CM_ SG_ 2365449982 HydraulicBrakeFluidLevelSwitch "Signal which indicates whether the hydraulic fluid level in the reservoir(s) is sufficient.00b = Fluid level is not sufficient01b = Fluid level is sufficient10b…";
CM_ SG_ 2365449982 HydraulicBrakePressureCircuit1 "Gage hydraulic pressure in circuit 1 of the hydraulic brake system…";
CM_ SG_ 2365449982 HydraulicBrakePressureCircuit2 "Gage hydraulic pressure in circuit 2 of the hydraulic brake system…";
CM_ BO_ 2365450238 "Bus #1/Utility Sync Check Status";
CM_ SG_ 2365450238 Bus1UtilityACPhaseDifference "The phase difference between the Bus #1 voltage and Utility voltage.…";
CM_ SG_ 2365450238 Bus1UtilityDeadBus "Indicator of whether Bus #1 is considered dead for closing to the utility. This indicator will be based on parameters such as Bus #1 Voltage and dead bus thresh…";
CM_ SG_ 2365450238 Bus1UtilityFrequencyMatch "Indicator of whether frequency difference between Bus #1 and Utility is adequate for paralleling. This indicator will be based on the measured AC frequencies qu…";
CM_ SG_ 2365450238 Bus1UtilityInSync "Indicator of whether Bus #1 and Utility are properly synchronized for paralleling. This indicator will be based on parameters such as Voltage Match, Frequency M…";
CM_ SG_ 2365450238 Bus1UtilityPhaseMatch "Indicator of whether phase difference between Bus #1 and Utility is adequate for paralleling. This indicator will be based on the measured AC phase difference q…";
CM_ SG_ 2365450238 Bus1UtilityVoltageMatch "Indicator of whether voltage difference between Bus #1 and Utility is adequate for paralleling. This indicator will be based on the measured AC voltages qualifi…";
CM_ BO_ 2365450494 "Bus #1/Generator Sync Check Status";
CM_ SG_ 2365450494 Bus1GeneratorACPhaseDifference "The phase difference between the Bus #1 voltage and Generator voltage.…";
CM_ SG_ 2365450494 Bus1GeneratorDeadBus "Indicator of whether Bus #1 is considered dead for closing to the generator. This indicator will be based on parameters such as Bus #1 Voltage and dead bus thre…";
CM_ SG_ 2365450494 Bus1GeneratorFrequencyMatch "Indicator of whether frequency difference between Bus #1 and Generator is adequate for paralleling. This indicator will be based on the measured AC frequencies …";
CM_ SG_ 2365450494 Bus1GeneratorInSync "Indicator of whether Bus #1 and Generator are properly synchronized for paralleling. This indicator will be based on parameters such as Voltage Match, Frequency…";
CM_ SG_ 2365450494 Bus1GeneratorPhaseMatch "Indicator of whether phase difference between Bus #1 and Generator is adequate for paralleling. This indicator will be based on the measured AC phase difference…";
CM_ SG_ 2365450494 Bus1GeneratorVoltageMatch "Indicator of whether voltage difference between Bus #1 and Generator is adequate for paralleling. This indicator will be based on the measured AC voltages quali…";
CM_ BO_ 2365450750 "Bus #1 Phase C  Basic AC Quantities";
CM_ SG_ 2365450750 Bs1PhsCLnNtrlACRMSVltg "Line to Neutral RMS voltage measured at bus #1 phase C.…";
CM_ SG_ 2365450750 Bus1PhaseCACFrequency "AC frequency measured at bus #1 phase C.…";
CM_ SG_ 2365450750 Bus1PhaseCALineLineACRMSVoltage "Line to Line RMS voltage measured at bus #1 phase CA.…";
CM_ BO_ 2365451006 "Bus #1 Phase B  Basic AC Quantities";
CM_ SG_ 2365451006 Bs1PhsBLnNtrlACRMSVltg "Line to Neutral RMS voltage measured at bus #1 phase B.…";
CM_ SG_ 2365451006 Bus1PhaseBACFrequency "AC frequency measured at bus #1 phase B.…";
CM_ SG_ 2365451006 Bus1PhaseBCLineLineACRMSVoltage "Line to Line RMS voltage measured at bus #1 phase BC.…";
CM_ BO_ 2365451262 "Bus #1 Phase A  Basic AC Quantities";
CM_ SG_ 2365451262 Bs1PhsALnNtrlACRMSVltg "Line to Neutral RMS voltage measured at bus #1 phase A.…";
CM_ SG_ 2365451262 Bus1PhaseAACFrequency "AC frequency measured at bus #1 phase A.…";
CM_ SG_ 2365451262 Bus1PhaseABLineLineACRMSVoltage "Line to Line RMS voltage measured at bus #1 phase AB.…";
CM_ BO_ 2365451518 "Bus #1 Average Basic AC Quantities";
CM_ SG_ 2365451518 Bs1AvrgLnNtrlACRMSVltg "The average Line to Neutral AC RMS voltage measured at bus #1 .…";
CM_ SG_ 2365451518 Bus1AverageACFrequency "Average AC frequency measured at bus #1.…";
CM_ SG_ 2365451518 Bus1AverageLineLineACRMSVoltage "Average Line to Line RMS voltage measured at bus #1 .…";
CM_ BO_ 2365451774 "Utility Total AC Energy";
CM_ SG_ 2365451774 UtilityTotalkWHoursExport "The total kilowatt-hours that have been exported by the utility incomer.…";
CM_ SG_ 2365451774 UtilityTotalkWHoursImport "The total kilowatt-hours that have been imported by the utility incomer.…";
CM_ BO_ 2365452030 "Utility Phase C AC Reactive Power";
CM_ SG_ 2365452030 UtilityPhaseCPowerFactor "The power factor of phases C of the utility incomer.…";
CM_ SG_ 2365452030 UtilityPhaseCPowerFactorLagging "Lead/lag status for utility incomer phase C power factor.00b = Leading01b = Lagging10b = Error11b = Not Available or Not Installed…";
CM_ SG_ 2365452030 UtilityPhaseCReactivePower "The reactive power delivered by phase C of the utility incomer…";
CM_ BO_ 2365452286 "Utility Phase C AC Power";
CM_ SG_ 2365452286 UtilityPhaseCApparentPower "The apparent power delivered by phase C of the utility incomer.…";
CM_ SG_ 2365452286 UtilityPhaseCRealPower "The real power delivered by phase C of the utility incomer.…";
CM_ BO_ 2365452542 "Utility Phase C AC Basic Quantities";
CM_ SG_ 2365452542 UtilityPhaseCACFrequency "AC frequency measured at the utility incomer phase C.…";
CM_ SG_ 2365452542 UtilityPhaseCACRMSCurrent "RMS current measured at the utility incomer phase C.…";
CM_ SG_ 2365452542 UtltPhsCALnLnACRMSVltg "Line to Line RMS voltage measured at the utility incomer phase CA.…";
CM_ SG_ 2365452542 UtltPhsCLnNtrlACRMSVltg "Line to Neutral RMS voltage measured at the utility incomer phase C.…";
CM_ BO_ 2365452798 "Utility Phase B AC Reactive Power";
CM_ SG_ 2365452798 UtilityPhaseBPowerFactor "The power factor of phases B of the utility incomer.…";
CM_ SG_ 2365452798 UtilityPhaseBPowerFactorLagging "Lead/lag status for utility incomer phase B power factor.00b = Leading01b = Lagging10b = Error11b = Not Available or Not Installed…";
CM_ SG_ 2365452798 UtilityPhaseBReactivePower "The reactive power delivered by phase B of the utility incomer…";
CM_ BO_ 2365453054 "Utility Phase B AC Power";
CM_ SG_ 2365453054 UtilityPhaseBApparentPower "The apparent power delivered by phase B of the utility incomer.…";
CM_ SG_ 2365453054 UtilityPhaseBRealPower "The real power delivered by phase B of the utility incomer.…";
CM_ BO_ 2365453310 "Utility Phase B AC Basic Quantities";
CM_ SG_ 2365453310 UtilityPhaseBACFrequency "AC frequency measured at the utility incomer phase B.…";
CM_ SG_ 2365453310 UtilityPhaseBACRMSCurrent "RMS current measured at the utility incomer phase B.…";
CM_ SG_ 2365453310 UtltPhsBCLnLnACRMSVltg "Line to Line RMS voltage measured at the utility incomer phase BC.…";
CM_ SG_ 2365453310 UtltPhsBLnNtrlACRMSVltg "Line to Neutral RMS voltage measured at the utility incomer phase B.…";
CM_ BO_ 2365453566 "Utility Phase A AC Reactive Power";
CM_ SG_ 2365453566 UtilityPhaseAPowerFactor "The power factor of phase A of the utility incomer.…";
CM_ SG_ 2365453566 UtilityPhaseAPowerFactorLagging "Lead/lag status for utility incomer phase A power factor.00b = Leading01b = Lagging10b = Error11b = Not Available or Not Installed…";
CM_ SG_ 2365453566 UtilityPhaseAReactivePower "The reactive power delivered by phase A of the utility incomer…";
CM_ BO_ 2365453822 "Utility Phase A AC Power";
CM_ SG_ 2365453822 UtilityPhaseAApparentPower "The apparent power delivered by phase A of the utility incomer.…";
CM_ SG_ 2365453822 UtilityPhaseARealPower "The real power delivered by phase A of the utility incomer.…";
CM_ BO_ 2365454078 "Utility Phase A Basic AC Quantities";
CM_ SG_ 2365454078 UtilityPhaseAACFrequency "AC frequency measured at the utility incomer phase A.…";
CM_ SG_ 2365454078 UtilityPhaseAACRMSCurrent "RMS current measured at the utility incomer phase A.…";
CM_ SG_ 2365454078 UtltPhsABLnLnACRMSVltg "Line to Line RMS voltage measured at the utility incomer phase AB.…";
CM_ SG_ 2365454078 UtltPhsALnNtrlACRMSVltg "Line to Neutral RMS voltage measured at the utility incomer phase A.…";
CM_ BO_ 2365454334 "Utility Total AC Reactive Power";
CM_ SG_ 2365454334 UtilityOverallPowerFactor "The average power factor of the utility incomer.…";
CM_ SG_ 2365454334 UtilityTotalReactivePower "The total reactive power delivered by the utility incomer…";
CM_ SG_ 2365454334 UtltOvrllPwrFtrLggng "Lead/lag status for utility incomer average power factor.00b = Leading01b = Lagging10b = Error11b = Not Available or Not Installed…";
CM_ BO_ 2365454590 "Utility Total AC Power";
CM_ SG_ 2365454590 UtilityTotalApparentPower "The total apparent power delivered by the utility incomer.…";
CM_ SG_ 2365454590 UtilityTotalRealPower "Total real power delivered by the utility incomer.…";
CM_ BO_ 2365454846 "Utility Average Basic AC Quantities";
CM_ SG_ 2365454846 UtilityAverageACFrequency "Average AC frequency measured at the utility incomer.…";
CM_ SG_ 2365454846 UtilityAverageACRMSCurrent "Average RMS current measured at the utility incomer.…";
CM_ SG_ 2365454846 UtltAvrgLnLnACRMSVltg "Average Line to Line RMS voltage measured at the utility incomer .…";
CM_ SG_ 2365454846 UtltAvrgLnNtrlACRMSVltg "The average Line to Neutral AC RMS voltage measured at the utility incomer .…";
CM_ BO_ 2365455102 "Generator Total AC Energy";
CM_ SG_ 2365455102 GeneratorTotalkWHoursExport "The total kilowatt-hours that have been exported by the generator.…";
CM_ SG_ 2365455102 GeneratorTotalkWHoursImport "The total kilowatt-hours that have been imported by the generator.…";
CM_ BO_ 2365455358 "Generator Phase C AC Reactive Power";
CM_ SG_ 2365455358 GeneratorPhaseCPowerFactor "The power factor of phases C of the generator.…";
CM_ SG_ 2365455358 GeneratorPhaseCReactivePower "The reactive power delivered by phase C of the generator…";
CM_ SG_ 2365455358 GnrtrPhsCPwrFtrLggng "Lead/lag status for generator phase C power factor.00b = Leading01b = Lagging10b = Error11b = Not Available or Not Installed…";
CM_ BO_ 2365455614 "Generator Phase C AC Power";
CM_ SG_ 2365455614 GeneratorPhaseCApparentPower "The apparent power delivered by phase C of the generator.…";
CM_ SG_ 2365455614 GeneratorPhaseCRealPower "The real power delivered by phase C of the generator.…";
CM_ BO_ 2365455870 "Generator Phase C Basic AC Quantities";
CM_ SG_ 2365455870 GeneratorPhaseCACFrequency "AC frequency measured at the generator phase C output.…";
CM_ SG_ 2365455870 GeneratorPhaseCACRMSCurrent "RMS current measured at the generator phase C output.…";
CM_ SG_ 2365455870 GnrtrPhsCALnLnACRMSVltg "Line to Line RMS voltage measured at the generator phase CA output.…";
CM_ SG_ 2365455870 GnrtrPhsCLnNtrlACRMSVltg "Line to Neutral RMS voltage measured at the generator phase C output.…";
CM_ BO_ 2365456126 "Generator Phase B AC Reactive Power";
CM_ SG_ 2365456126 GeneratorPhaseBPowerFactor "The power factor of phases B of the generator.…";
CM_ SG_ 2365456126 GeneratorPhaseBReactivePower "The reactive power delivered by phase B of the generator…";
CM_ SG_ 2365456126 GnrtrPhsBPwrFtrLggng "Lead/lag status for generator phase B power factor.00b = Leading01b = Lagging10b = Error11b = Not Available or Not Installed…";
CM_ BO_ 2365456382 "Generator Phase B AC Power";
CM_ SG_ 2365456382 GeneratorPhaseBApparentPower "The apparent power delivered by phase B of the generator.…";
CM_ SG_ 2365456382 GeneratorPhaseBRealPower "The real power delivered by phase B of the generator.…";
CM_ BO_ 2365456894 "Generator Phase A AC Reactive Power";
CM_ SG_ 2365456894 GeneratorPhaseAPowerFactor "The power factor of phase A of the generator.…";
CM_ SG_ 2365456894 GeneratorPhaseAReactivePower "The reactive power delivered by phase A of the generator…";
CM_ SG_ 2365456894 GnrtrPhsAPwrFtrLggng "Lead/lag status for generator phase A power factor.00b = Leading01b = Lagging10b = Error11b = Not Available or Not Installed…";
CM_ BO_ 2365457150 "Generator Phase A AC Power";
CM_ SG_ 2365457150 GeneratorPhaseAApparentPower "The apparent power delivered by phase A of the generator.…";
CM_ SG_ 2365457150 GeneratorPhaseARealPower "The real power delivered by phase A of the generator.…";
CM_ BO_ 2365457406 "Generator Phase A Basic AC Quantities";
CM_ SG_ 2365457406 GeneratorPhaseAACFrequency "AC frequency measured at the generator phase A output.…";
CM_ SG_ 2365457406 GeneratorPhaseAACRMSCurrent "RMS current measured at the generator phase A output.…";
CM_ SG_ 2365457406 GnrtrPhsABLnLnACRMSVltg "Line to Line RMS voltage measured at the generator phase AB output.…";
CM_ SG_ 2365457406 GnrtrPhsALnNtrlACRMSVltg "Line to Neutral RMS voltage measured at the generator phase A output.…";
CM_ BO_ 2365457662 "Generator Total AC Reactive Power";
CM_ SG_ 2365457662 GeneratorOverallPowerFactor "The average power factor of the generator.…";
CM_ SG_ 2365457662 GeneratorTotalReactivePower "The total reactive power delivered by the generator…";
CM_ SG_ 2365457662 GnrtrOvrllPwrFtrLggng "Lead/lag status for generator average power factor.00b = Leading01b = Lagging10b = Error11b = Not Available or Not Installed…";
CM_ BO_ 2365457918 "Generator Total AC Power";
CM_ SG_ 2365457918 GeneratorTotalApparentPower "The total apparent power delivered by the generator.…";
CM_ SG_ 2365457918 GeneratorTotalRealPower "Total real power delivered by the generator.…";
CM_ BO_ 2365458174 "Generator Average Basic AC Quantities";
CM_ SG_ 2365458174 GeneratorAverageACFrequency "Average AC frequency measured at the generator output.…";
CM_ SG_ 2365458174 GeneratorAverageACRMSCurrent "Average RMS current measured at the generator output.…";
CM_ SG_ 2365458174 GnrtrAvrgLnLnACRMSVltg "Average Line to Line RMS voltage measured at the generator output.…";
CM_ SG_ 2365458174 GnrtrAvrgLnNtrlACRMSVltg "The average Line to Neutral AC RMS voltage measured at the Generator output.…";
CM_ BO_ 2365473278 "Lighting Command";
CM_ SG_ 2365473278 AlternateBeamHeadLightCommand "Command to activate or de-activate the tractor alternate head lights (only low beam is available on alternate head lights).  The alternate position lights are i…";
CM_ SG_ 2365473278 BackUpLightandAlarmHornCommand "Command to activate or de-activate the back up lights and/ or associated alarm if required00b = De-activate01b = Activate10b = Reserved11b = Don't Care…";
CM_ SG_ 2365473278 CenterStopLightCommand "Command to activate or de-activate the tractor and implement center stop light00b = De-activate01b = Activate10b = Reserved11b = Don't Care…";
CM_ SG_ 2365473278 HighBeamHeadLightCommand "Command to activate or de-activate the tractor high beam head light lamps. 00b = De-activate01b = Activate10b = Reserved11b = Don't Care…";
CM_ SG_ 2365473278 ImplementClearanceLightCommand "Command to activate or de-activate the implement high mounted clearance and lights.  00b = De-activate01b = Activate10b = Reserved11b = Don't Care…";
CM_ SG_ 2365473278 ImplementMarkerLightCommand "Command to activate or de-activate implement front position lights, rear red tail lights, side amber running lights, license plate lights and instrument and swi…";
CM_ SG_ 2365473278 ImplementOEMOption1LightCommand "Command to activate or de-activate an implement OEM option 1 light.  This is provided to meet special needs on implements, such as tank inspection or filling li…";
CM_ SG_ 2365473278 ImplementOEMOption2LightCommand "Command to activate or de-activate an implement OEM option 2 light.  This is provided to meet special needs on implements, such as tank inspection or filling li…";
CM_ SG_ 2365473278 ImplementRearWorkLightCommand "Command to activate or de-activate implement rear work lights.  (This is also the same as Reversing Lights for truck applications.)  00b = De-activate01b = Acti…";
CM_ SG_ 2365473278 ImplmntLftFngWrkLghtCmmnd "Command to activate or de-activate the left facing work lights toward the left end of the implement.00b = De-activate01b = Activate10b = Reserved11b = Don't Car…";
CM_ SG_ 2365473278 ImplmntLftFrwrdWrkLghtCmmnd "Command to activate or de-activate work lights mounted on an implement to illuminate beyond left end of the implement.00b = De-activate01b = Activate10b = Reser…";
CM_ SG_ 2365473278 ImplmntRghtFngWrkLghtCmmnd "Command to activate or de-activate work lights mounted on an implement to illuminate beyond right end of the implement.00b = De-activate01b = Activate10b = Rese…";
CM_ SG_ 2365473278 ImplmntRghtFrwrdWrkLghtCmmnd "Command to activate or de-activate the forward facing work lights toward the right end of the implement.00b = De-activate01b = Activate10b = Reserved11b = Don't…";
CM_ SG_ 2365473278 LeftStopLightCommand "Command to activate or de-activate the tractor and implement left stop lights00b = De-activate01b = Activate10b = Reserved11b = Don't Care…";
CM_ SG_ 2365473278 LeftTurnSignalLightsCommand "Command to activate or de-activate left turn signal lights on the tractor and all connected implements00b = De-activate01b = Activate10b = Reserved11b = Don't C…";
CM_ SG_ 2365473278 LightingDataRequestCommand "Command to provide a response of the light state00b = De-activate01b = Activate10b = Reserved11b = Don't Care…";
CM_ SG_ 2365473278 LowBeamHeadLightCommand "Command to activate or de-activate the tractor low beam head light lamps. 00b = De-activate01b = Activate10b = Reserved11b = Don't Care…";
CM_ SG_ 2365473278 RearFogLightCommand "Command to activate or de-activate tractor or implement rear fog lights.  00b = De-activate01b = Activate10b = Reserved11b = Don't Care…";
CM_ SG_ 2365473278 RightStopLightCommand "Command to activate or de-activate the tractor and implement right stop light00b = De-activate01b = Activate10b = Reserved11b = Don't Care…";
CM_ SG_ 2365473278 RightTurnSignalLightsCommand "Command to activate or de-activate right turn signal lights on the tractor and all connected implements00b = De-activate01b = Activate10b = Reserved11b = Don't …";
CM_ SG_ 2365473278 RotatingBeaconLightCommand "Command to activate or de-activate slow moving vehicle indicator lights on tractor and/or implements.  Activation of the slow moving vehicle lights implies that…";
CM_ SG_ 2365473278 RunningLightCommand "Command to activate or de-activate the tractor or powered vehicle running lights.  Usually only used for on road vehicles.00b = De-activate01b = Activate10b = R…";
CM_ SG_ 2365473278 TractorClearanceLightCommand "Command to activate or de-activate the tractor high mounted clearance and center ID lights00b = De-activate01b = Activate10b = Reserved11b = Don't Care…";
CM_ SG_ 2365473278 TractorFrontFogLightsCommand "Command to activate or de-activate tractor front fog lights.00b = De-activate01b = Activate10b = Reserved11b = Don't Care…";
CM_ SG_ 2365473278 TractorMarkerLightCommand "Command to activate or de-activate tractor and implement front position lights, rear red tail lights, side amber running lights, license plate lights and instru…";
CM_ SG_ 2365473278 TrtrFrntHghMntdWrkLghtsCmmnd "Command to activate or de-activate the tractor front high mounted work lights.00b = De-activate01b = Activate10b = Reserved11b = Don't Care…";
CM_ SG_ 2365473278 TrtrFrntLwMntdWrkLghtsCmmnd "Command to activate or de-activate the tractor front low mounted work lights.00b = De-activate01b = Activate10b = Reserved11b = Don't Care…";
CM_ SG_ 2365473278 TrtrRrHghMntdWrkLghtsCmmnd "Command to activate or de-activate the tractor rear high  mounted work lights.00b = De-activate01b = Activate10b = Reserved11b = Don't Care…";
CM_ SG_ 2365473278 TrtrRrLwMntdWrkLghtsCmmnd "Command to activate or de-activate the tractor rear low  mounted work lights.00b = De-activate01b = Activate10b = Reserved11b = Don't Care…";
CM_ SG_ 2365473278 TrtrSdHghMntdWrkLghtsCmmnd "Command to activate or de-activate the tractor side high mounted work lights.00b = De-activate01b = Activate10b = Reserved11b = Don't Care…";
CM_ SG_ 2365473278 TrtrSdLwMntdWrkLghtsCmmnd "Command to activate or de-activate the tractor side low mounted work lights.00b = De-activate01b = Activate10b = Reserved11b = Don't Care…";
CM_ SG_ 2365473278 TrtrUndrsdMntdWrkLghtsCmmnd "Command to activate or de-activate the tractor underside mounted work lights.00b = De-activate01b = Activate10b = Reserved11b = Don't Care…";
CM_ BO_ 2365478910 "Air Suspension Control 5";
CM_ SG_ 2365478910 DamperStiffnessFrontAxle "Damper stiffness information of the shock absorber control at the front axle…";
CM_ SG_ 2365478910 DamperStiffnessLiftTagAxle "Damper stiffness information of the shock absorber control at the lift of tag axle…";
CM_ SG_ 2365478910 DamperStiffnessRearAxle "Damper stiffness information of the shock absorber control at the rear axle…";
CM_ SG_ 2365478910 EltrnShkAsrrCntrlMdFrntAxl "Signal which indicates the current mode of operation of the electronic shock absorber control at the front axle.00b = Normal operation dampers passive01b = Norm…";
CM_ SG_ 2365478910 EltrnShkAsrrCntrlMdLftTgAxl "Signal which indicates the current mode of operation of the electronic shock absorber control at the lift/tag axle.00b = Normal operation dampers passive01b = N…";
CM_ SG_ 2365478910 EltrnShkAsrrCntrlMdRrAxl "Signal which indicates the current mode of operation of the electronic shock absorber control at the rear axle.00b = Normal operation dampers passive01b = Norma…";
CM_ BO_ 2365479678 "Air Suspension Control 1";
CM_ SG_ 2365479678 AboveNominalLevelFrontAxle "Signal which indicates whether the actual height of the front axle is above the nominal (desired) level of the front axle. For explanations of nominal level see…";
CM_ SG_ 2365479678 AboveNominalLevelRearAxle "Signal which indicates whether the actual height of the rear axle is above the nominal (desired) level of the rear axle. For explanations of nominal level see p…";
CM_ SG_ 2365479678 AllwLvlCntrlDrngBrkngStts "This parameter indicates if the function Allow Level Control During Braking is active. Functions is activated by SPN 5293.00b = Deactivated01b = Activated10b = …";
CM_ SG_ 2365479678 BelowNominalLevelFrontAxle "Signal which indicates whether the actual height of the front axle is below the nominal (desired) level for the front axle. For explanations of nominal level se…";
CM_ SG_ 2365479678 BelowNominalLevelRearAxle "Signal which indicates whether the actual height of the rear axle is below the nominal (desired) level for the rear axle. For explanations of nominal level see …";
CM_ SG_ 2365479678 DoorRelease "Signal which indicates that the doors may be opened. [Please note: doors instead of door!]In case a kneeling request is active the ASC indicates during lowering…";
CM_ SG_ 2365479678 FrontAxleinBumperRange "Signal which indicates that the vehicle height at the front axle (SPNs 1721 and 1722) is within the bumper range.00b = Actual level out of bumper range01b = Act…";
CM_ SG_ 2365479678 KneelingInformation "Signal which indicates the actual level change in case of kneeling function0000b = Not active,(i.e. the kneeling function is not active)0001b = Lowering active,…";
CM_ SG_ 2365479678 LevelControlMode "Signal which indicates the actual control mode of the air suspension system0000b = Normal operation; i.e. the system performs a pure control of the vehicle heig…";
CM_ SG_ 2365479678 LiftAxle1Position "Signal which indicates the position / load condition of lift axle / tag axle 1.   Numbering of lift/tag axles starts at front axle.  See SPN 6843 for more detai…";
CM_ SG_ 2365479678 LiftAxle2Position "Signal which indicates the position / load condition of lift axle / tag axle #2.   Numbering of lift/tag axles starts at front axle.  See SPN 6844 for more deta…";
CM_ SG_ 2365479678 LiftingControlModeFrontAxle "Signal which indicates the actual lifting level change at the front axle00b = Lifting not active01b = Lifting active10b = Error11b = Not available…";
CM_ SG_ 2365479678 LiftingControlModeRearAxle "Signal which indicates the actual lifting level change at the rear axle00b = Lifting not active01b = Lifting active10b = Error11b = Not available…";
CM_ SG_ 2365479678 LoweringControlModeFrontAxle "Signal which indicates the actual lowering level change at the front axle00b = Lowering not active01b = Lowering active10b = Error11b = Not available…";
CM_ SG_ 2365479678 LoweringControlModeRearAxle "Signal which indicates the actual lowering level change at the rear axle00b = Lowering not active01b = Lowering active10b = Error11b = Not available…";
CM_ SG_ 2365479678 Memorylevel "Signal which indicates that the air suspension control has memory levels selected or stored.Response to memory level request in ASC2 (byte 8.5). If the request …";
CM_ SG_ 2365479678 NominalLevelFrontAxle "Signal which indicates the nominal (desired) height of the front axle to be controlled by the suspension system.These heights are discrete levels.  They are the…";
CM_ SG_ 2365479678 NominalLevelRearAxle "Signal which indicates the nominal (desired) height of the rear axle to be controlled by the suspension system.For further explanations see SPN 1734 - Nominal L…";
CM_ SG_ 2365479678 RearAxleinBumperRange "Signal which indicates that the vehicle height at the rear axle (SPNs 1723 and 1724) is within the bumper range.00b = Actual level out of bumper range01b = Actu…";
CM_ SG_ 2365479678 SecurityDevice "The signal which indicates the status of the security device.  An example of a security device is a curbstone feeler installed beneath the doors of a bus. If th…";
CM_ SG_ 2365479678 SpdDpndntLvlCntrlStts "This parameter indicates if the function Speed Dependant Level Control is active. The function is activated by SPN 5295.00b = Inactive01b = Active10b = Reserved…";
CM_ SG_ 2365479678 SspnsnCntrlRfslInfrmtn "Signal which indicates that the air suspension control cannot perform a request due to the operating conditions. It also provides a reason for the refusal.0000b…";
CM_ SG_ 2365479678 SuspensionRemoteControl1 "Signal which indicates that the suspension system is controlled by remote control #1. Remote control is an external unit to operate the suspension system.00b = …";
CM_ SG_ 2365479678 SuspensionRemotecontrol2 "Signal which indicates that the suspension system is controlled by remote control #2. Remote control is an external unit to operate the suspension system.00b = …";
CM_ SG_ 2365479678 VehicleMotionInhibit "Signal which indicates whether vehicle motion is inhibited.00b = Vehicle may be moved01b = Vehicle motion is inhibited10b = Error11b = Not available…";
CM_ BO_ 2365484286 "Tachograph";
CM_ SG_ 2365484286 Directionindicator "Indicates the direction of the vehicle.00b = Forward01b = Reverse10b = Error11b = Not available…";
CM_ SG_ 2365484286 Driver1TimeRelatedStates "Indicates if the driver approaches or exceeds working time limits (or other limits).  0000b = Normal/No limits reached0001b = Limit #1 – 15 min before 4 ½ h0010…";
CM_ SG_ 2365484286 Driver1workingstate "State of work of the driver.  000b = Rest - sleeping001b = Driver available – short break010b = Work – loading, unloading, working in an office011b = Drive – be…";
CM_ SG_ 2365484286 Driver2TimeRelatedStates "Indicates if the driver approaches or exceeds working time limits (or other limits).  0000b = Normal/No limits reached0001b = Limit #1 – 15 min before 4 ½ h0010…";
CM_ SG_ 2365484286 Driver2workingstate "State of work of the driver.  000b = Rest - sleeping001b = Driver available – short break010b = Work – loading, unloading, working in an office011b = Drive – be…";
CM_ SG_ 2365484286 Drivercarddriver1 "Indicates the presence of a driver card00b = Driver card not present01b = Driver card present10b = Error11b = Not available…";
CM_ SG_ 2365484286 Drivercarddriver2 "Indicates the presence of a driver card00b = Driver card not present01b = Driver card present10b = Error11b = Not available…";
CM_ SG_ 2365484286 Handlinginformation "Indicates that handling information is present.  Information could include no printer paper, no driver card, etc.00b = No handling information01b = Handling inf…";
CM_ SG_ 2365484286 Systemevent "Indicates that a tachograph event has occurred.  This may include power supply interruption, interruption of the speed sensor, incorrect data on the driver card…";
CM_ SG_ 2365484286 Tachographoutputshaftspeed "Calculated speed of the transmission output shaft.…";
CM_ SG_ 2365484286 Tachographperformance "Indicates the tachograph performance; including electronic or mechanical analysis, instrument analysis, speed sensor analysis, mass storage analysis, and printe…";
CM_ SG_ 2365484286 Tachographvehiclespeed "Speed of the vehicle registered by the tachograph.…";
CM_ SG_ 2365484286 Vehiclemotion "Indicates whether motion of the vehicle is detected or not.00b = Vehicle motion not detected01b = Vehicle motion detected10b = Error11b = Not available…";
CM_ SG_ 2365484286 VehicleOverspeed "Indicates whether the vehicle is exceeding the legal speed limit set in the tachograph.00b = No overspeed01b = Overspeed10b = Error11b = Not available…";
CM_ BO_ 2365485566 "Laser Tracer Position";
CM_ SG_ 2365485566 LaserTracerHorizontalDeviation "The calculated percent deviation between the target distance and the center of the laser tracer.…";
CM_ SG_ 2365485566 LaserTracerInformation "Provides the status of the laser tracer to the operator. 00000001b = Laser power is on00000010b = Laser is ready00000100b = Valid target (1 = yes)00001000b = Pr…";
CM_ SG_ 2365485566 LaserTracerTargetDeviation "The calculated distance for the laser target to the current laser tracer reference point.Parameter specific parameter: FE03h indicates that the sensor can not s…";
CM_ SG_ 2365485566 LaserTracerVerticalDistance "The elevation of the laser tracer sensor in a laser leveling system.…";
CM_ SG_ 2365485566 LEDDisplayData2 "Informs display devices how to display the current position of the laser tracer.Values which are less than 128 decimal are bit-mapped values and any combination…";
CM_ BO_ 2365485822 "Laser Leveling System Blade Control";
CM_ SG_ 2365485822 BladeControlMode "Allows the user to select the type of blade control for the land leveling system.  00000000b = Manual mode00000001b = Automatic mode00000010b = Inactive automat…";
CM_ SG_ 2365485822 BladeControlModeLeft "Indicate if the land leveling system's automatic control is active or inactive for the elevation sensor on the left side of the blade.  The left notation is app…";
CM_ SG_ 2365485822 BladeControlModeRight "Indicate if the land leveling system's automatic control is active or inactive for the elevation sensor on the right side of the blade.  The left notation is ap…";
CM_ SG_ 2365485822 BladeDurationandDirection "Used to indicate the duration and direction that the land leveling system blade moves.…";
CM_ SG_ 2365485822 LandLevelingSystemEnableStatus "Communicate the enable/disable status of the Land Leveling System.00b = Disabled01b = Enabled10b = Error11b = Not available / Not installed…";
CM_ BO_ 2365486078 "Laser Receiver Mast Position";
CM_ SG_ 2365486078 MastPosition "Used to monitor the position of the sensor attached to the land leveling mast.…";
CM_ BO_ 2365486334 "Modify Leveling System Control Set Point";
CM_ SG_ 2365486334 BldHghtStPntHghRsltn "High resolution for the laser guided blade set point.  The high resolution required for more accurate control and 'accurate' unit conversions.Negative values ar…";
CM_ SG_ 2365486334 ModifyLevelingSystemSetPoint "Used to control and coordinate the set point for the leveling system.Operating Range: -3200 to +3200 mm, negative values are below current position, positive va…";
CM_ BO_ 2365486590 "Laser Leveling System Vertical Deviation";
CM_ SG_ 2365486590 AbsoluteLaserStrikePosition "Laser Strike location on the survey type  laser receiver.…";
CM_ SG_ 2365486590 LaserReceiverType "Identifies which type of Laser Receiver transmitted the message.0 = Reserved 1 = Linear Laser Receiver2 = 1 Meter Survey Receiver3 = 2 Meter Survey Receiver4 = …";
CM_ SG_ 2365486590 LaserStrikeDataLatency "Time from laser strike to CAN message transmission.  This parameter will be reported by survey receiver type devices only. Byte 3 (SPN 2576) of  PGN 65141 ident…";
CM_ SG_ 2365486590 LaserStrikeVerticalDeviation "The calculated distance from the laser strike position to the current land leveling system reference point.…";
CM_ BO_ 2431649790 "Forward Lane Image 1";
CM_ SG_ 2431649790 DriverAlertnessWarning "Indicates when a distracted driving condition is detected. This signal can be used independent of the technology and ECU used to estimate the distracted driver …";
CM_ SG_ 2431649790 LaneDepartureImminentLeftSide "Indicates departure imminent on left side of lane.00b = Not imminent01b = Imminent10b = Reserved11b = Not used…";
CM_ SG_ 2431649790 LaneDepartureImminentRightSide "Indicates departure imminent on right side of lane.00b = Not imminent01b = Imminent10b = Reserved11b = Not Used…";
CM_ SG_ 2431649790 LaneDepartureLeft "Indicates that the middle of vehicle departs the lane on the left side. The parameter indicates that the vehicle is changing the lane to the left.00b = Middle o…";
CM_ SG_ 2431649790 LaneDepartureRight "Indicates that the middle of vehicle departs the lane on the right side. The parameter indicates that the vehicle is changing the lane to the right.00b = Middle…";
CM_ SG_ 2431649790 LftSdLnDprtrAstlWrnngCmmnd "Indicates that the forward lane imaging system is commanding an acoustical warning for the lane departure on the left side of the vehicle.Used for driving acous…";
CM_ SG_ 2431649790 LftSdLnDprtrOptlWrnngCmmnd "Indicates that the forward lane imaging system is commanding an optical warning for the lane departure on the left side of the vehicle.Used for driving optical …";
CM_ SG_ 2431649790 RghtSdLnDprtrAstlWrnngCmmnd "Indicates that the forward lane imaging system is commanding an acoustical warning for the lane departure on the right side of the vehicle.Used for driving acou…";
CM_ SG_ 2431649790 RghtSdLnDprtrOptlWrnngCmmnd "Indicates that the forward lane imaging system is commanding an optical warning for the lane departure on the right side of the vehicle.Used for driving optical…";
CM_ SG_ 2431649790 RghtSdLnDprtrHptWrnngCmmnd "Indicates that the forward lane imaging system is commanding an haptic warning for the lane departure on the right side of the vehicle.Used for driving haptic a…";
CM_ SG_ 2431649790 LftSdLnDprtrHptWrnngCmmnd "Indicates that the forward lane imaging system is commanding an haptic warning for the lane departure on the left side of the vehicle.Used for driving haptic al…";
CM_ BO_ 2431654654 "Engine Throttle / Fuel Actuator Control Command";
CM_ SG_ 2431654654 EngnFlAttr1CntrlCmmnd "The control command to fuel actuator 1, normalized to percent, where 0% represents fully closed and 100% represents fully open. In applications where the fuel a…";
CM_ SG_ 2431654654 EngnFlAttr2CntrlCmmnd "The control command to fuel actuator 2, normalized to percent, where 0% represents fully closed and 100% represents fully open. Typically, this fuel actuator is…";
CM_ SG_ 2431654654 EngnThrttlAttr1CntrlCmmnd "The control command to throttle actuator 1, normalized to percent, where 0% represents fully closed and 100% represents fully open.  Typically, this throttle ac…";
CM_ SG_ 2431654654 EngnThrttlAttr2CntrlCmmnd "The control command to throttle actuator 2, normalized to percent, where 0% represents fully closed and 100% represents fully open.  Typically, this throttle ac…";
CM_ BO_ 2431661054 "Aftertreatment 1 SCR Ammonia Information 2";
CM_ SG_ 2431661054 Aftrtrtmnt1SCRIntrmdtNH3 "The amount of NH3 in the exhaust aftertreatment system measured by a NH3 sensor at an intermediate point in the SCR system, represented in NH3 molecule parts pe…";
CM_ SG_ 2431661054 Aftrtrtmnt1SCRIntrmdtNH3RdngStl "Indicates that the NH3 reading of the aftertreatment SCR intermediate NH3 sensor is stable as determined by the manufacturer's control software in exhaust bank …";
CM_ SG_ 2431661054 Atttt1SCRItdtNH3SsHtCt "Indicates the heater status in the warm-up process. Upon receiving a power-up command, the NH3 sensor ramps up according to a manufacturer defined profile. The …";
CM_ SG_ 2431661054 Atttt1SCRItdtNH3SsHtPFMI "Used to identify the applicable J1939-73 FMI detected in the heater of the outlet NH3 exhaust sensor by the manufacturer’s sensor control software in exhaust ba…";
CM_ SG_ 2431661054 Atttt1SCRItdtNH3SsPFMI "Used to identify the applicable J1939-73 FMI detected in the aftertreatment SCR intermediate NH3 sensor by the manufacturer’s sensor control software in exhaust…";
CM_ SG_ 2431661054 Atttt1SCRItdtNH3SsPwIR "Indicates that the power supplied to the aftertreatment SCR intermediate NH3 sensor is within the manufacturer's specification in exhaust bank 1.00b = Power is …";
CM_ SG_ 2431661054 Atttt1SCRItdtNH3SstTpt "Indicates that the heater element of the aftertreatment SCR intermediate NH3 sensor is within the manufacturer's specified range for accurate measurements in ex…";
CM_ BO_ 2431661310 "Aftertreatment 2 SCR Ammonia Information 2";
CM_ SG_ 2431661310 Aftrtrtmnt2SCRIntrmdtNH3 "The amount of NH3 in the exhaust aftertreatment system measured by a NH3 sensor at an intermediate point in the SCR system, represented in NH3 molecule parts pe…";
CM_ SG_ 2431661310 Aftrtrtmnt2SCRIntrmdtNH3RdngStl "Indicates that the NH3 reading of the aftertreatment SCR intermediate NH3 sensor is stable as determined by the manufacturer's control software in exhaust bank …";
CM_ SG_ 2431661310 Atttt2SCRItdtNH3SsHtCt "Indicates the heater status in the warm-up process. Upon receiving a power-up command, the NH3 sensor ramps up according to a manufacturer defined profile. The …";
CM_ SG_ 2431661310 Atttt2SCRItdtNH3SsHtPFMI "Used to identify the applicable J1939-73 FMI detected in the heater of the SCR intermediate NH3 exhaust sensor by the manufacturer’s sensor control software in …";
CM_ SG_ 2431661310 Atttt2SCRItdtNH3SsPFMI "Used to identify the applicable J1939-73 FMI detected in the aftertreatment SCR intermediate NH3 sensor by the manufacturer’s sensor control software in exhaust…";
CM_ SG_ 2431661310 Atttt2SCRItdtNH3SsPwIR "Indicates that the power supplied to the aftertreatment SCR intermediate NH3 sensor is within the manufacturer's specification in exhaust bank 2.00b = Heater el…";
CM_ SG_ 2431661310 Atttt2SCRItdtNH3SstTpt "Indicates that the heater element of the aftertreatment SCR intermediate NH3 sensor is within the manufacturer's specified range for accurate measurements in ex…";
CM_ BO_ 2431708670 "Engine Start Control";
CM_ SG_ 2431708670 EngineStartAbortRequest "Indicates the sender's desire to abort an engine start. This signal is used by requesters and consenters to request that the arbitrator cancel an engine start t…";
CM_ SG_ 2431708670 EngineStartConsent "Indicates the sender's consent to start the engine for different start types. An operator-requested engine start is a start that is initiated directly by the op…";
CM_ SG_ 2431708670 EngineStartControlChecksum "Checksum to allow detection of data integrity issues. The receiving node shall calculate the checksum and compare its calculated value with the received checksu…";
CM_ SG_ 2431708670 EngineStarter1Feedback "Feedback of the current state of first engine starter. This signal is intended to be used by the arbitrator as feedback to its command signal (SPN 7753).Additio…";
CM_ SG_ 2431708670 EngineStarter2Feedback "Feedback of the current state of second engine starter. This signal is intended to be used by the arbitrator as feedback to its command signal (SPN 7753).Additi…";
CM_ SG_ 2431708670 EngineStartRequest "Indicates the sender's desire to start the engine. The engine start arbitrator latches this signal and, if possible, completes the engine start regardless of a …";
CM_ SG_ 2431708670 EngnStrtCntrlMssgCntr "Message counter to allow detection of data integrity issues. The counter is incremented every time a device sends out the Engine Start Control message. When the…";
CM_ SG_ 2431708670 TrnsmssnShftSltrRqstdVhlDrtn "This parameter indicates the direction selected by the operator via the active transmission shift selector.Some regulations (e.g., Federal Motor Vehicle Safety …";
CM_ BO_ 2431710718 "Engine Start Arbitrator";
CM_ SG_ 2431710718 AtmtEngnStrtCnsntSmmr "Arbitrator's summary of the consent statuses of all devices which the arbitrator considers for automatic start requests. The purpose of this parameter is for re…";
CM_ SG_ 2431710718 EngineStartArbitratorChecksum "Checksum to allow detection of data integrity issues. The receiving node shall calculate the checksum and compare its calculated value with the received checksu…";
CM_ SG_ 2431710718 EngineStartControlMessageRate "This signal is sent by the arbitrator to control the rate at which other participants send the Engine Start Control Message (ENGSC). The arbitrator sets this si…";
CM_ SG_ 2431710718 EngineStarterCommand "Command from the arbitrator to the engine starter controller(s).The arbitrator takes input from consenters and requesters to initiate an engine start. This sign…";
CM_ SG_ 2431710718 EngineStartRequestLatchStatus "Indicates the arbitrator's latch status for engine start requests. All unlatched states shall transition to state 0 – Start Request not received after 1000 ms u…";
CM_ SG_ 2431710718 EngnStrtArtrtrMssgCntr "Message counter to allow detection of data integrity issues. The counter is incremented every time a device sends out the Engine Start Control message. When the…";
CM_ SG_ 2431710718 OprtrEngnStrtCnsntSmmr "Arbitrator's summary of the consent statuses of all devices which the arbitrator considers for operator start requests. The purpose of this parameter is for req…";
CM_ BO_ 2431717886 "Gaseous Fuel Pressure 3";
CM_ SG_ 2431717886 EngnFlVlv1DffrntlPrssrHghRsltn "The differential pressure between the intake and the outlet of the first or only gaseous fuel valve.See SPN 1391 for alternate range and resolution.…";
CM_ BO_ 2431719166 "Well Stimulation Pump System 3";
CM_ SG_ 2431719166 WellStimulationPumpFlowRate "The amount of fluid that is being pumped by the well stimulation pump.…";
CM_ SG_ 2431719166 WellStimulationPumpRodLoad "The load on the plungers of the well stimulation pump.…";
CM_ SG_ 2431719166 WllStmltnPmpCvttnStts "Indicates the level of cavitation detected on the well stimulation pump.000b = No Cavitation001b = Low010b = Medium011b = High100b = Reserved101b = Reserved110b…";
CM_ SG_ 2431719166 WllStmltnPmpFldEndVlvLk "Indicates the leakage detected in the well stimulation pump fluid end.00b = No Leak Detected01b = Leak Detected10b = Error11b = Not Available…";
CM_ BO_ 2432471038 "Alternate Fuel 3";
CM_ SG_ 2432471038 EngnFlVprzr1DshrgTmprtr "The temperature of the fuel in its gaseous state at the outlet of the first fuel vaporizer…";
CM_ SG_ 2432471038 EngnGssFlSpplPrssr1ExtnddRng "Pressure of gaseous fuel supply to fuel metering device in systems where the pressure range defined for SPN 159 is not sufficient.…";
CM_ SG_ 2432471038 GssFlAmltrTmprtr "Gaseous fuel temperature at the outlet of the Gas Filter.…";
CM_ SG_ 2432471038 EGssFSppPssRtCtCd "The command to the fuel pressure regulator which regulates the pressure of gaseous fuel supply to the engine. This command is normalized to percent, where 0% no…";
CM_ BO_ 2432492542 "Engine Exhaust Brake Control";
CM_ SG_ 2432492542 EngnExhstBrkAttrCmmnd "The control command applied to the engine exhaust brake actuator, where 0% represents no braking and 100% represents full braking.…";
CM_ SG_ 2432492542 EngnTrhrgr1TrnDsrdOtltPrssr "The desired gage pressure of the combustion by-products exiting the turbine side of the turbocharger 1 at the current engine operating conditions.…";
CM_ SG_ 2432492542 EngnTrhrgr1TrnOtltPrssr "Gage pressure of the combustion by-products exiting the turbine side of the turbocharger 1.…";
CM_ SG_ 2432492542 EngnTrhrgr2TrnDsrdOtltPrssr "The desired gage pressure of the combustion by-products exiting the turbine side of the turbocharger 2 at the current engine operating conditions.…";
CM_ SG_ 2432492542 EngnTrhrgr2TrnOtltPrssr "Gage pressure of the combustion by-products exiting the turbine side of the turbocharger 2.…";
CM_ BO_ 2432499198 "Electronic Engine Controller 9";
CM_ SG_ 2432499198 CmmnddEngnFlInjtnCntrlPrssr "Provides the commanded set point value for the engine fuel injection control pressure.…";
CM_ SG_ 2432499198 CommandedEngineFuelRailPressure "Provides the commanded set point value for the engine fuel rail gage pressure…";
CM_ SG_ 2432499198 EngnExhstGsRrltn2Vlv2Pstn "The position of the second exhaust gas recirculation valve of EGR 2 expressed as a percentage of full travel. 0% means the valve is closed and no exhaust gas is…";
CM_ SG_ 2432499198 EngnExhstGsRrltn2VlvPstn "Position of EGR2 valve expressed as a percentage of full travel. 0% means the valve is closed and no exhaust gas is flowing into the air stream. 100% means the …";
CM_ BO_ 2432520702 "Aftercooler Coolant Control Valve Command";
CM_ SG_ 2432520702 AftrlrClntThrmsttMd "Specifies if the aftercooler coolant thermostat valve will operate in temperature control mode or position control mode.00b = temperature control mode01b = posi…";
CM_ SG_ 2432520702 DsrdAftrlrClntIntkTmprtr "Indicates the desired temperature of the fluid in the low temperature aftercooler circuit to an electronic thermostat.  If the aftercooler coolant thermostat va…";
CM_ SG_ 2432520702 DsrdAftrlrClntThrmsttOpnng "Used to transmit the desired position of the low temperature aftercooler temperature control valve.  0% represents the thermostat allows flow to completely bypa…";
CM_ SG_ 2432520702 EngnChrgArClrBpssVlv1Cmmnd "Desired percentage of charge air cooler Bypass Valve 1 opening. 0% means no air is bypassed. 100% means full bypass capacity.…";
CM_ SG_ 2432520702 EngnChrgArClrBpssVlv2Cmmnd "Desired percentage of charge air cooler Bypass Valve 2 opening. 0% means no air is bypassed. 100% means full bypass capacity.…";
CM_ BO_ 2432520958 "Engine Coolant Control Valve Command";
CM_ SG_ 2432520958 DsrdEngnClntPmpOtltTmprtr "Desired engine coolant temperature of the engine to an electronic thermostat.  If the electronic thermostat valve is operating in position control mode (see SPN…";
CM_ SG_ 2432520958 DsrdEngnClntThrmsttOpnng "Indicates the desired position of the engine coolant control valve.   0% represents the thermostat allows flow to completely bypass the radiator and 100% repres…";
CM_ SG_ 2432520958 EngineCoolantThermostatMode "Specifies if the engine coolant thermostat valve will operate in temperature control mode or position control mode.00b = temperature control mode01b = position …";
CM_ SG_ 2432520958 EngnAxlrClrSpplVlv1AttrCmmnd "The control command applied to the engine auxiliary cooler supply valve 1 actuator, where 0% represents closed and 100% represents open.See SPN 4197 for primary…";
CM_ SG_ 2432520958 EngnAxlrClrSpplVlv2AttrCmmnd "The control command applied to the engine auxiliary cooler supply valve 2 actuator, where 0% represents closed and 100% represents open.…";
CM_ BO_ 2432541438 "Fuel Information 3 (Gaseous)";
CM_ SG_ 2432541438 EngineFuel1Temperature2 "Second Temperature measurement of fuel (or gas) of the first fuel type. See SPN 174 for first fuel temperature measurement.…";
CM_ SG_ 2432541438 EngnFlSstm2GsMssFlwRt "Gas mass flow rate delivered to an engine through its second fuel control system, using standard convention for determining position.In a system with two fuel s…";
CM_ SG_ 2432541438 EngnFlVlv2IntkAsltPrssr "Absolute pressure of gas on intake side of the second fuel system control valve, using standard convention for determining position.In a system with two fuel sy…";
CM_ SG_ 2432541438 EngnFlVlv2OtltAsltPrssr "Absolute pressure of gas on outlet side of the second fuel system control valve.  See SPN 2980 for the first or only fuel system control valve.…";
BA_DEF_ SG_  "SPN" INT 0 524287;
BA_DEF_ BO_  "VFrameFormat" ENUM  "StandardCAN","ExtendedCAN","reserved","J1939PG";
BA_DEF_DEF_  "SPN" 0;
BA_DEF_DEF_  "VFrameFormat" "J1939PG";
BA_ "SPN" SG_ 2365401598 Joystick7Button13PressedStatus 6755;
BA_ "SPN" SG_ 2365401598 Joystick7Button14PressedStatus 6756;
BA_ "SPN" SG_ 2365401598 Joystick7Button15PressedStatus 6757;
BA_ "SPN" SG_ 2365401598 Joystick7Button16PressedStatus 6758;
BA_ "SPN" SG_ 2365401598 Joystick7GripXAxisPosition 4627;
BA_ "SPN" SG_ 2365401598 Joystick7GripYAxisPosition 4631;
BA_ "SPN" SG_ 2365401598 Joystick7ThetaAxisPosition 4635;
BA_ "SPN" SG_ 2365401598 Jst7GpYAxsLvFwdPstvPstStts 4630;
BA_ "SPN" SG_ 2365401598 Jst7TtAxsCtCwsNtvPstStts 4633;
BA_ "SPN" SG_ 2365401598 Jstk7GrpXAxsDtntPstnStts 4638;
BA_ "SPN" SG_ 2365401598 Jstk7GrpXAxsLvrLftNgtvPstnStts 4625;
BA_ "SPN" SG_ 2365401598 Jstk7GrpXAxsLvrRghtPstvPstnStts 4626;
BA_ "SPN" SG_ 2365401598 Jstk7GrpXAxsNtrlPstnStts 4624;
BA_ "SPN" SG_ 2365401598 Jstk7GrpYAxsDtntPstnStts 4637;
BA_ "SPN" SG_ 2365401598 Jstk7GrpYAxsLvrBkNgtvPstnStts 4629;
BA_ "SPN" SG_ 2365401598 Jstk7GrpYAxsNtrlPstnStts 4628;
BA_ "SPN" SG_ 2365401598 Jstk7ThtAxsClkwsPstvPstnStts 4634;
BA_ "SPN" SG_ 2365401598 Jstk7ThtAxsDtntPstnStts 4636;
BA_ "SPN" SG_ 2365401598 Jstk7ThtAxsNtrlPstnStts 4632;
BA_ "SPN" SG_ 2365401854 Joystick7Button10PressedStatus 4622;
BA_ "SPN" SG_ 2365401854 Joystick7Button11PressedStatus 4621;
BA_ "SPN" SG_ 2365401854 Joystick7Button12PressedStatus 4620;
BA_ "SPN" SG_ 2365401854 Joystick7Button1PressedStatus 4615;
BA_ "SPN" SG_ 2365401854 Joystick7Button2PressedStatus 4614;
BA_ "SPN" SG_ 2365401854 Joystick7Button3PressedStatus 4613;
BA_ "SPN" SG_ 2365401854 Joystick7Button4PressedStatus 4612;
BA_ "SPN" SG_ 2365401854 Joystick7Button5PressedStatus 4619;
BA_ "SPN" SG_ 2365401854 Joystick7Button6PressedStatus 4618;
BA_ "SPN" SG_ 2365401854 Joystick7Button7PressedStatus 4617;
BA_ "SPN" SG_ 2365401854 Joystick7Button8PressedStatus 4616;
BA_ "SPN" SG_ 2365401854 Joystick7Button9PressedStatus 4623;
BA_ "SPN" SG_ 2365401854 Joystick7XAxisPosition 4605;
BA_ "SPN" SG_ 2365401854 Joystick7YAxisPosition 4609;
BA_ "SPN" SG_ 2365401854 Jstk7XAxsDtntPstnStts 4611;
BA_ "SPN" SG_ 2365401854 Jstk7XAxsLvrLftNgtvPstnStts 4603;
BA_ "SPN" SG_ 2365401854 Jstk7XAxsLvrRghtPstvPstnStts 4604;
BA_ "SPN" SG_ 2365401854 Jstk7XAxsNtrlPstnStts 4602;
BA_ "SPN" SG_ 2365401854 Jstk7YAxsDtntPstnStts 4610;
BA_ "SPN" SG_ 2365401854 Jstk7YAxsLvrBkNgtvPstnStts 4607;
BA_ "SPN" SG_ 2365401854 Jstk7YAxsLvrFrwrdPstvPstnStts 4608;
BA_ "SPN" SG_ 2365401854 Jstk7YAxsNtrlPstnStts 4606;
BA_ "SPN" SG_ 2365402110 Joystick6Button13PressedStatus 6751;
BA_ "SPN" SG_ 2365402110 Joystick6Button14PressedStatus 6752;
BA_ "SPN" SG_ 2365402110 Joystick6Button15PressedStatus 6753;
BA_ "SPN" SG_ 2365402110 Joystick6Button16PressedStatus 6754;
BA_ "SPN" SG_ 2365402110 Joystick6GripXAxisPosition 4590;
BA_ "SPN" SG_ 2365402110 Joystick6GripYAxisPosition 4594;
BA_ "SPN" SG_ 2365402110 Joystick6ThetaAxisPosition 4598;
BA_ "SPN" SG_ 2365402110 Jst6GpYAxsLvFwdPstvPstStts 4593;
BA_ "SPN" SG_ 2365402110 Jst6TtAxsCtCwsNtvPstStts 4596;
BA_ "SPN" SG_ 2365402110 Jstk6GrpXAxsDtntPstnStts 4601;
BA_ "SPN" SG_ 2365402110 Jstk6GrpXAxsLvrLftNgtvPstnStts 4588;
BA_ "SPN" SG_ 2365402110 Jstk6GrpXAxsLvrRghtPstvPstnStts 4589;
BA_ "SPN" SG_ 2365402110 Jstk6GrpXAxsNtrlPstnStts 4587;
BA_ "SPN" SG_ 2365402110 Jstk6GrpYAxsDtntPstnStts 4600;
BA_ "SPN" SG_ 2365402110 Jstk6GrpYAxsLvrBkNgtvPstnStts 4592;
BA_ "SPN" SG_ 2365402110 Jstk6GrpYAxsNtrlPstnStts 4591;
BA_ "SPN" SG_ 2365402110 Jstk6ThtAxsClkwsPstvPstnStts 4597;
BA_ "SPN" SG_ 2365402110 Jstk6ThtAxsDtntPstnStts 4599;
BA_ "SPN" SG_ 2365402110 Jstk6ThtAxsNtrlPstnStts 4595;
BA_ "SPN" SG_ 2365402366 Joystick6Button10PressedStatus 4585;
BA_ "SPN" SG_ 2365402366 Joystick6Button11PressedStatus 4584;
BA_ "SPN" SG_ 2365402366 Joystick6Button12PressedStatus 4583;
BA_ "SPN" SG_ 2365402366 Joystick6Button1PressedStatus 4578;
BA_ "SPN" SG_ 2365402366 Joystick6Button2PressedStatus 4577;
BA_ "SPN" SG_ 2365402366 Joystick6Button3PressedStatus 4576;
BA_ "SPN" SG_ 2365402366 Joystick6Button4PressedStatus 4575;
BA_ "SPN" SG_ 2365402366 Joystick6Button5PressedStatus 4582;
BA_ "SPN" SG_ 2365402366 Joystick6Button6PressedStatus 4581;
BA_ "SPN" SG_ 2365402366 Joystick6Button7PressedStatus 4580;
BA_ "SPN" SG_ 2365402366 Joystick6Button8PressedStatus 4579;
BA_ "SPN" SG_ 2365402366 Joystick6Button9PressedStatus 4586;
BA_ "SPN" SG_ 2365402366 Joystick6XAxisPosition 4568;
BA_ "SPN" SG_ 2365402366 Joystick6YAxisPosition 4572;
BA_ "SPN" SG_ 2365402366 Jstk6XAxsDtntPstnStts 4574;
BA_ "SPN" SG_ 2365402366 Jstk6XAxsLvrLftNgtvPstnStts 4566;
BA_ "SPN" SG_ 2365402366 Jstk6XAxsLvrRghtPstvPstnStts 4567;
BA_ "SPN" SG_ 2365402366 Jstk6XAxsNtrlPstnStts 4565;
BA_ "SPN" SG_ 2365402366 Jstk6YAxsDtntPstnStts 4573;
BA_ "SPN" SG_ 2365402366 Jstk6YAxsLvrBkNgtvPstnStts 4570;
BA_ "SPN" SG_ 2365402366 Jstk6YAxsLvrFrwrdPstvPstnStts 4571;
BA_ "SPN" SG_ 2365402366 Jstk6YAxsNtrlPstnStts 4569;
BA_ "SPN" SG_ 2365402622 Joystick5Button13PressedStatus 6747;
BA_ "SPN" SG_ 2365402622 Joystick5Button14PressedStatus 6748;
BA_ "SPN" SG_ 2365402622 Joystick5Button15PressedStatus 6749;
BA_ "SPN" SG_ 2365402622 Joystick5Button16PressedStatus 6750;
BA_ "SPN" SG_ 2365402622 Joystick5GripXAxisPosition 4553;
BA_ "SPN" SG_ 2365402622 Joystick5GripYAxisPosition 4557;
BA_ "SPN" SG_ 2365402622 Joystick5ThetaAxisPosition 4561;
BA_ "SPN" SG_ 2365402622 Jst5GpYAxsLvFwdPstvPstStts 4556;
BA_ "SPN" SG_ 2365402622 Jst5TtAxsCtCwsNtvPstStts 4559;
BA_ "SPN" SG_ 2365402622 Jstk5GrpXAxsDtntPstnStts 4564;
BA_ "SPN" SG_ 2365402622 Jstk5GrpXAxsLvrLftNgtvPstnStts 4551;
BA_ "SPN" SG_ 2365402622 Jstk5GrpXAxsLvrRghtPstvPstnStts 4552;
BA_ "SPN" SG_ 2365402622 Jstk5GrpXAxsNtrlPstnStts 4550;
BA_ "SPN" SG_ 2365402622 Jstk5GrpYAxsDtntPstnStts 4563;
BA_ "SPN" SG_ 2365402622 Jstk5GrpYAxsLvrBkNgtvPstnStts 4555;
BA_ "SPN" SG_ 2365402622 Jstk5GrpYAxsNtrlPstnStts 4554;
BA_ "SPN" SG_ 2365402622 Jstk5ThtAxsClkwsPstvPstnStts 4560;
BA_ "SPN" SG_ 2365402622 Jstk5ThtAxsDtntPstnStts 4562;
BA_ "SPN" SG_ 2365402622 Jstk5ThtAxsNtrlPstnStts 4558;
BA_ "SPN" SG_ 2365402878 Joystick5Button10PressedStatus 4548;
BA_ "SPN" SG_ 2365402878 Joystick5Button11PressedStatus 4547;
BA_ "SPN" SG_ 2365402878 Joystick5Button12PressedStatus 4546;
BA_ "SPN" SG_ 2365402878 Joystick5Button1PressedStatus 4541;
BA_ "SPN" SG_ 2365402878 Joystick5Button2PressedStatus 4540;
BA_ "SPN" SG_ 2365402878 Joystick5Button3PressedStatus 4539;
BA_ "SPN" SG_ 2365402878 Joystick5Button4PressedStatus 4538;
BA_ "SPN" SG_ 2365402878 Joystick5Button5PressedStatus 4545;
BA_ "SPN" SG_ 2365402878 Joystick5Button6PressedStatus 4544;
BA_ "SPN" SG_ 2365402878 Joystick5Button7PressedStatus 4543;
BA_ "SPN" SG_ 2365402878 Joystick5Button8PressedStatus 4542;
BA_ "SPN" SG_ 2365402878 Joystick5Button9PressedStatus 4549;
BA_ "SPN" SG_ 2365402878 Joystick5XAxisPosition 4531;
BA_ "SPN" SG_ 2365402878 Joystick5YAxisPosition 4535;
BA_ "SPN" SG_ 2365402878 Jstk5XAxsDtntPstnStts 4537;
BA_ "SPN" SG_ 2365402878 Jstk5XAxsLvrLftNgtvPstnStts 4529;
BA_ "SPN" SG_ 2365402878 Jstk5XAxsLvrRghtPstvPstnStts 4530;
BA_ "SPN" SG_ 2365402878 Jstk5XAxsNtrlPstnStts 4528;
BA_ "SPN" SG_ 2365402878 Jstk5YAxsDtntPstnStts 4536;
BA_ "SPN" SG_ 2365402878 Jstk5YAxsLvrBkNgtvPstnStts 4533;
BA_ "SPN" SG_ 2365402878 Jstk5YAxsLvrFrwrdPstvPstnStts 4534;
BA_ "SPN" SG_ 2365402878 Jstk5YAxsNtrlPstnStts 4532;
BA_ "SPN" SG_ 2365403134 Joystick4Button13PressedStatus 6743;
BA_ "SPN" SG_ 2365403134 Joystick4Button14PressedStatus 6744;
BA_ "SPN" SG_ 2365403134 Joystick4Button15PressedStatus 6745;
BA_ "SPN" SG_ 2365403134 Joystick4Button16PressedStatus 6746;
BA_ "SPN" SG_ 2365403134 Joystick4GripXAxisPosition 4516;
BA_ "SPN" SG_ 2365403134 Joystick4GripYAxisPosition 4520;
BA_ "SPN" SG_ 2365403134 Joystick4ThetaAxisPosition 4524;
BA_ "SPN" SG_ 2365403134 Jst4GpYAxsLvFwdPstvPstStts 4519;
BA_ "SPN" SG_ 2365403134 Jst4TtAxsCtCwsNtvPstStts 4522;
BA_ "SPN" SG_ 2365403134 Jstk4GrpXAxsDtntPstnStts 4527;
BA_ "SPN" SG_ 2365403134 Jstk4GrpXAxsLvrLftNgtvPstnStts 4514;
BA_ "SPN" SG_ 2365403134 Jstk4GrpXAxsLvrRghtPstvPstnStts 4515;
BA_ "SPN" SG_ 2365403134 Jstk4GrpXAxsNtrlPstnStts 4513;
BA_ "SPN" SG_ 2365403134 Jstk4GrpYAxsDtntPstnStts 4526;
BA_ "SPN" SG_ 2365403134 Jstk4GrpYAxsLvrBkNgtvPstnStts 4518;
BA_ "SPN" SG_ 2365403134 Jstk4GrpYAxsNtrlPstnStts 4517;
BA_ "SPN" SG_ 2365403134 Jstk4ThtAxsClkwsPstvPstnStts 4523;
BA_ "SPN" SG_ 2365403134 Jstk4ThtAxsDtntPstnStts 4525;
BA_ "SPN" SG_ 2365403134 Jstk4ThtAxsNtrlPstnStts 4521;
BA_ "SPN" SG_ 2365403390 Joystick4Button10PressedStatus 4511;
BA_ "SPN" SG_ 2365403390 Joystick4Button11PressedStatus 4510;
BA_ "SPN" SG_ 2365403390 Joystick4Button12PressedStatus 4509;
BA_ "SPN" SG_ 2365403390 Joystick4Button1PressedStatus 4504;
BA_ "SPN" SG_ 2365403390 Joystick4Button2PressedStatus 4503;
BA_ "SPN" SG_ 2365403390 Joystick4Button3PressedStatus 4502;
BA_ "SPN" SG_ 2365403390 Joystick4Button4PressedStatus 4501;
BA_ "SPN" SG_ 2365403390 Joystick4Button5PressedStatus 4508;
BA_ "SPN" SG_ 2365403390 Joystick4Button6PressedStatus 4507;
BA_ "SPN" SG_ 2365403390 Joystick4Button7PressedStatus 4506;
BA_ "SPN" SG_ 2365403390 Joystick4Button8PressedStatus 4505;
BA_ "SPN" SG_ 2365403390 Joystick4Button9PressedStatus 4512;
BA_ "SPN" SG_ 2365403390 Joystick4XAxisPosition 4494;
BA_ "SPN" SG_ 2365403390 Joystick4YAxisPosition 4498;
BA_ "SPN" SG_ 2365403390 Jstk4XAxsDtntPstnStts 4500;
BA_ "SPN" SG_ 2365403390 Jstk4XAxsLvrLftNgtvPstnStts 4492;
BA_ "SPN" SG_ 2365403390 Jstk4XAxsLvrRghtPstvPstnStts 4493;
BA_ "SPN" SG_ 2365403390 Jstk4XAxsNtrlPstnStts 4491;
BA_ "SPN" SG_ 2365403390 Jstk4YAxsDtntPstnStts 4499;
BA_ "SPN" SG_ 2365403390 Jstk4YAxsLvrBkNgtvPstnStts 4496;
BA_ "SPN" SG_ 2365403390 Jstk4YAxsLvrFrwrdPstvPstnStts 4497;
BA_ "SPN" SG_ 2365403390 Jstk4YAxsNtrlPstnStts 4495;
BA_ "SPN" SG_ 2365428478 EngineControlledShutdownRequest 3606;
BA_ "SPN" SG_ 2365428478 EngineCoolantPumpControl 3605;
BA_ "SPN" SG_ 2365428478 EngineDerateRequest 3644;
BA_ "SPN" SG_ 2365428478 EngineDesiredTorqueRequest 6807;
BA_ "SPN" SG_ 2365428478 EngineFuelShutoff1Control 632;
BA_ "SPN" SG_ 2365428478 EngineFuelShutoff2Control 2807;
BA_ "SPN" SG_ 2365428478 EngineFuelShutoffVentControl 3608;
BA_ "SPN" SG_ 2365428478 EngineOilPreheaterControl 3602;
BA_ "SPN" SG_ 2365428478 EngineOilPrimingPumpControl 3589;
BA_ "SPN" SG_ 2365428478 EngineOperatingState 3543;
BA_ "SPN" SG_ 2365428478 EnginePreHeaterControl 3604;
BA_ "SPN" SG_ 2365428478 EngineStarterMotorRelayControl 6385;
BA_ "SPN" SG_ 2365428478 EngnCldAmntElvtdIdlStts 6884;
BA_ "SPN" SG_ 2365428478 EngnEltrlSstmPwrCnsrvtnCntrl 3603;
BA_ "SPN" SG_ 2365428478 EngnEmrgnImmdtShtdwnIndtn 3607;
BA_ "SPN" SG_ 2365428478 EngnFlShtffVlvLkTstCntrl 3601;
BA_ "SPN" SG_ 2365428478 FuelPumpPrimerControl 4082;
BA_ "SPN" SG_ 2365428478 TmRmnngnEngnOprtngStt 3544;
BA_ "SPN" SG_ 2365428734 EngineSpeedGovernorDroop 5568;
BA_ "SPN" SG_ 2365428734 EngineSpeedGovernorGainAdjust 5567;
BA_ "SPN" SG_ 2365428734 GeneratorAlternatorEfficiency 4078;
BA_ "SPN" SG_ 2365428734 GeneratorFrequencySelection 4080;
BA_ "SPN" SG_ 2365428734 GeneratorGoverningSpeedCommand 4079;
BA_ "SPN" SG_ 2365428734 GnrtrCntrlNtInAtmtStrtStt 3567;
BA_ "SPN" SG_ 2365428734 GnrtrNtRdtAtmtllPrlllStt 3568;
BA_ "SPN" SG_ 2365428734 RequestedEngineControlMode 3542;
BA_ "SPN" SG_ 2365433598 GeneratorExcitationFieldCurrent 3381;
BA_ "SPN" SG_ 2365433598 GeneratorExcitationFieldVoltage 3380;
BA_ "SPN" SG_ 2365433598 GnrtrOtptVltgBsPrntg 3382;
BA_ "SPN" SG_ 2365443326 HazardLightSwitch 2875;
BA_ "SPN" SG_ 2365443326 HighLowBeamSwitch 2874;
BA_ "SPN" SG_ 2365443326 MainLightSwitch 2872;
BA_ "SPN" SG_ 2365443326 OperatorsDesiredBacklight 2878;
BA_ "SPN" SG_ 2365443326 OprtrsDsrdDldLmpOffTm 2877;
BA_ "SPN" SG_ 2365443326 TurnSignalSwitch 2876;
BA_ "SPN" SG_ 2365443326 WorkLightSwitch 2873;
BA_ "SPN" SG_ 2365445886 Joystick1Button10PressedStatus 2694;
BA_ "SPN" SG_ 2365445886 Joystick1Button11PressedStatus 2695;
BA_ "SPN" SG_ 2365445886 Joystick1Button12PressedStatus 2696;
BA_ "SPN" SG_ 2365445886 Joystick1Button1PressedStatus 2685;
BA_ "SPN" SG_ 2365445886 Joystick1Button2PressedStatus 2686;
BA_ "SPN" SG_ 2365445886 Joystick1Button3PressedStatus 2687;
BA_ "SPN" SG_ 2365445886 Joystick1Button4PressedStatus 2688;
BA_ "SPN" SG_ 2365445886 Joystick1Button5PressedStatus 2689;
BA_ "SPN" SG_ 2365445886 Joystick1Button6PressedStatus 2690;
BA_ "SPN" SG_ 2365445886 Joystick1Button7PressedStatus 2691;
BA_ "SPN" SG_ 2365445886 Joystick1Button8PressedStatus 2692;
BA_ "SPN" SG_ 2365445886 Joystick1Button9PressedStatus 2693;
BA_ "SPN" SG_ 2365445886 Joystick1XAxisPosition 2660;
BA_ "SPN" SG_ 2365445886 Joystick1YAxisPosition 2661;
BA_ "SPN" SG_ 2365445886 Jstk1XAxsDtntPstnStts 2680;
BA_ "SPN" SG_ 2365445886 Jstk1XAxsLvrLftNgtvPstnStts 2670;
BA_ "SPN" SG_ 2365445886 Jstk1XAxsLvrRghtPstvPstnStts 2665;
BA_ "SPN" SG_ 2365445886 Jstk1XAxsNtrlPstnStts 2675;
BA_ "SPN" SG_ 2365445886 Jstk1YAxsDtntPstnStts 2681;
BA_ "SPN" SG_ 2365445886 Jstk1YAxsLvrBkNgtvPstnStts 2671;
BA_ "SPN" SG_ 2365445886 Jstk1YAxsLvrFrwrdPstvPstnStts 2666;
BA_ "SPN" SG_ 2365445886 Jstk1YAxsNtrlPstnStts 2676;
BA_ "SPN" SG_ 2365446142 Joystick1Button13PressedStatus 6731;
BA_ "SPN" SG_ 2365446142 Joystick1Button14PressedStatus 6732;
BA_ "SPN" SG_ 2365446142 Joystick1Button15PressedStatus 6733;
BA_ "SPN" SG_ 2365446142 Joystick1Button16PressedStatus 6734;
BA_ "SPN" SG_ 2365446142 Joystick1GripXAxisPosition 2662;
BA_ "SPN" SG_ 2365446142 Joystick1GripYAxisPosition 2663;
BA_ "SPN" SG_ 2365446142 Joystick1ThetaAxisPosition 2664;
BA_ "SPN" SG_ 2365446142 Jst1GpYAxsLvFwdPstvPstStts 2668;
BA_ "SPN" SG_ 2365446142 Jst1TtAxsCtCwsNtvPstStts 2674;
BA_ "SPN" SG_ 2365446142 Jstk1GrpXAxsDtntPstnStts 2682;
BA_ "SPN" SG_ 2365446142 Jstk1GrpXAxsLvrLftNgtvPstnStts 2672;
BA_ "SPN" SG_ 2365446142 Jstk1GrpXAxsLvrRghtPstvPstnStts 2667;
BA_ "SPN" SG_ 2365446142 Jstk1GrpXAxsNtrlPstnStts 2677;
BA_ "SPN" SG_ 2365446142 Jstk1GrpYAxsDtntPstnStts 2683;
BA_ "SPN" SG_ 2365446142 Jstk1GrpYAxsLvrBkNgtvPstnStts 2673;
BA_ "SPN" SG_ 2365446142 Jstk1GrpYAxsNtrlPstnStts 2678;
BA_ "SPN" SG_ 2365446142 Jstk1ThtAxsClkwsPstvPstnStts 2669;
BA_ "SPN" SG_ 2365446142 Jstk1ThtAxsDtntPstnStts 2684;
BA_ "SPN" SG_ 2365446142 Jstk1ThtAxsNtrlPstnStts 2679;
BA_ "SPN" SG_ 2365446398 Joystick2Button10PressedStatus 2731;
BA_ "SPN" SG_ 2365446398 Joystick2Button11PressedStatus 2732;
BA_ "SPN" SG_ 2365446398 Joystick2Button12PressedStatus 2733;
BA_ "SPN" SG_ 2365446398 Joystick2Button1PressedStatus 2722;
BA_ "SPN" SG_ 2365446398 Joystick2Button2PressedStatus 2723;
BA_ "SPN" SG_ 2365446398 Joystick2Button3PressedStatus 2724;
BA_ "SPN" SG_ 2365446398 Joystick2Button4PressedStatus 2725;
BA_ "SPN" SG_ 2365446398 Joystick2Button5PressedStatus 2726;
BA_ "SPN" SG_ 2365446398 Joystick2Button6PressedStatus 2727;
BA_ "SPN" SG_ 2365446398 Joystick2Button7PressedStatus 2728;
BA_ "SPN" SG_ 2365446398 Joystick2Button8PressedStatus 2729;
BA_ "SPN" SG_ 2365446398 Joystick2Button9PressedStatus 2730;
BA_ "SPN" SG_ 2365446398 Joystick2XAxisPosition 2697;
BA_ "SPN" SG_ 2365446398 Joystick2YAxisPosition 2698;
BA_ "SPN" SG_ 2365446398 Jstk2XAxsDtntPstnStts 2717;
BA_ "SPN" SG_ 2365446398 Jstk2XAxsLvrLftNgtvPstnStts 2707;
BA_ "SPN" SG_ 2365446398 Jstk2XAxsLvrRghtPstvPstnStts 2702;
BA_ "SPN" SG_ 2365446398 Jstk2XAxsNtrlPstnStts 2712;
BA_ "SPN" SG_ 2365446398 Jstk2YAxsDtntPstnStts 2718;
BA_ "SPN" SG_ 2365446398 Jstk2YAxsLvrBkNgtvPstnStts 2708;
BA_ "SPN" SG_ 2365446398 Jstk2YAxsLvrFrwrdPstvPstnStts 2703;
BA_ "SPN" SG_ 2365446398 Jstk2YAxsNtrlPstnStts 2713;
BA_ "SPN" SG_ 2365446654 Joystick2Button13PressedStatus 6735;
BA_ "SPN" SG_ 2365446654 Joystick2Button14PressedStatus 6736;
BA_ "SPN" SG_ 2365446654 Joystick2Button15PressedStatus 6737;
BA_ "SPN" SG_ 2365446654 Joystick2Button16PressedStatus 6738;
BA_ "SPN" SG_ 2365446654 Joystick2GripXAxisPosition 2699;
BA_ "SPN" SG_ 2365446654 Joystick2GripYAxisPosition 2700;
BA_ "SPN" SG_ 2365446654 Joystick2ThetaAxisPosition 2701;
BA_ "SPN" SG_ 2365446654 Jst2GpYAxsLvFwdPstvPstStts 2705;
BA_ "SPN" SG_ 2365446654 Jst2TtAxsCtCwsNtvPstStts 2711;
BA_ "SPN" SG_ 2365446654 Jstk2GrpXAxsDtntPstnStts 2719;
BA_ "SPN" SG_ 2365446654 Jstk2GrpXAxsLvrLftNgtvPstnStts 2709;
BA_ "SPN" SG_ 2365446654 Jstk2GrpXAxsLvrRghtPstvPstnStts 2704;
BA_ "SPN" SG_ 2365446654 Jstk2GrpXAxsNtrlPstnStts 2714;
BA_ "SPN" SG_ 2365446654 Jstk2GrpYAxsDtntPstnStts 2720;
BA_ "SPN" SG_ 2365446654 Jstk2GrpYAxsLvrBkNgtvPstnStts 2710;
BA_ "SPN" SG_ 2365446654 Jstk2GrpYAxsNtrlPstnStts 2715;
BA_ "SPN" SG_ 2365446654 Jstk2ThtAxsClkwsPstvPstnStts 2706;
BA_ "SPN" SG_ 2365446654 Jstk2ThtAxsDtntPstnStts 2721;
BA_ "SPN" SG_ 2365446654 Jstk2ThtAxsNtrlPstnStts 2716;
BA_ "SPN" SG_ 2365446910 Joystick3Button10PressedStatus 2768;
BA_ "SPN" SG_ 2365446910 Joystick3Button11PressedStatus 2769;
BA_ "SPN" SG_ 2365446910 Joystick3Button12PressedStatus 2770;
BA_ "SPN" SG_ 2365446910 Joystick3Button1PressedStatus 2759;
BA_ "SPN" SG_ 2365446910 Joystick3Button2PressedStatus 2760;
BA_ "SPN" SG_ 2365446910 Joystick3Button3PressedStatus 2761;
BA_ "SPN" SG_ 2365446910 Joystick3Button4PressedStatus 2762;
BA_ "SPN" SG_ 2365446910 Joystick3Button5PressedStatus 2763;
BA_ "SPN" SG_ 2365446910 Joystick3Button6PressedStatus 2764;
BA_ "SPN" SG_ 2365446910 Joystick3Button7PressedStatus 2765;
BA_ "SPN" SG_ 2365446910 Joystick3Button8PressedStatus 2766;
BA_ "SPN" SG_ 2365446910 Joystick3Button9PressedStatus 2767;
BA_ "SPN" SG_ 2365446910 Joystick3XAxisPosition 2734;
BA_ "SPN" SG_ 2365446910 Joystick3YAxisPosition 2735;
BA_ "SPN" SG_ 2365446910 Jstk3XAxsDtntPstnStts 2754;
BA_ "SPN" SG_ 2365446910 Jstk3XAxsLvrLftNgtvPstnStts 2744;
BA_ "SPN" SG_ 2365446910 Jstk3XAxsLvrRghtPstvPstnStts 2739;
BA_ "SPN" SG_ 2365446910 Jstk3XAxsNtrlPstnStts 2749;
BA_ "SPN" SG_ 2365446910 Jstk3YAxsDtntPstnStts 2755;
BA_ "SPN" SG_ 2365446910 Jstk3YAxsLvrBkNgtvPstnStts 2745;
BA_ "SPN" SG_ 2365446910 Jstk3YAxsLvrFrwrdPstvPstnStts 2740;
BA_ "SPN" SG_ 2365446910 Jstk3YAxsNtrlPstnStts 2750;
BA_ "SPN" SG_ 2365447166 Joystick3Button13PressedStatus 6739;
BA_ "SPN" SG_ 2365447166 Joystick3Button14PressedStatus 6740;
BA_ "SPN" SG_ 2365447166 Joystick3Button15PressedStatus 6741;
BA_ "SPN" SG_ 2365447166 Joystick3Button16PressedStatus 6742;
BA_ "SPN" SG_ 2365447166 Joystick3GripXAxisPosition 2736;
BA_ "SPN" SG_ 2365447166 Joystick3GripYAxisPosition 2737;
BA_ "SPN" SG_ 2365447166 Joystick3ThetaAxisPosition 2738;
BA_ "SPN" SG_ 2365447166 Jst3GpYAxsLvFwdPstvPstStts 2742;
BA_ "SPN" SG_ 2365447166 Jst3TtAxsCtCwsNtvPstStts 2748;
BA_ "SPN" SG_ 2365447166 Jstk3GrpXAxsDtntPstnStts 2756;
BA_ "SPN" SG_ 2365447166 Jstk3GrpXAxsLvrLftNgtvPstnStts 2746;
BA_ "SPN" SG_ 2365447166 Jstk3GrpXAxsLvrRghtPstvPstnStts 2741;
BA_ "SPN" SG_ 2365447166 Jstk3GrpXAxsNtrlPstnStts 2751;
BA_ "SPN" SG_ 2365447166 Jstk3GrpYAxsDtntPstnStts 2757;
BA_ "SPN" SG_ 2365447166 Jstk3GrpYAxsLvrBkNgtvPstnStts 2747;
BA_ "SPN" SG_ 2365447166 Jstk3GrpYAxsNtrlPstnStts 2752;
BA_ "SPN" SG_ 2365447166 Jstk3ThtAxsClkwsPstvPstnStts 2743;
BA_ "SPN" SG_ 2365447166 Jstk3ThtAxsDtntPstnStts 2758;
BA_ "SPN" SG_ 2365447166 Jstk3ThtAxsNtrlPstnStts 2753;
BA_ "SPN" SG_ 2365449982 HdrlBrkPrssrSpplSttCrt1 2582;
BA_ "SPN" SG_ 2365449982 HdrlBrkPrssrSpplSttCrt2 2583;
BA_ "SPN" SG_ 2365449982 HdrlBrkPrssrWrnngSttCrt1 2584;
BA_ "SPN" SG_ 2365449982 HdrlBrkPrssrWrnngSttCrt2 2585;
BA_ "SPN" SG_ 2365449982 HdrlBrkSstmAdlWrnngCmmnd 2930;
BA_ "SPN" SG_ 2365449982 HydraulicBrakeFluidLevelSwitch 2931;
BA_ "SPN" SG_ 2365449982 HydraulicBrakePressureCircuit1 2580;
BA_ "SPN" SG_ 2365449982 HydraulicBrakePressureCircuit2 2581;
BA_ "SPN" SG_ 2365450238 Bus1UtilityACPhaseDifference 2517;
BA_ "SPN" SG_ 2365450238 Bus1UtilityDeadBus 2535;
BA_ "SPN" SG_ 2365450238 Bus1UtilityFrequencyMatch 2533;
BA_ "SPN" SG_ 2365450238 Bus1UtilityInSync 2534;
BA_ "SPN" SG_ 2365450238 Bus1UtilityPhaseMatch 2531;
BA_ "SPN" SG_ 2365450238 Bus1UtilityVoltageMatch 2532;
BA_ "SPN" SG_ 2365450494 Bus1GeneratorACPhaseDifference 2516;
BA_ "SPN" SG_ 2365450494 Bus1GeneratorDeadBus 2530;
BA_ "SPN" SG_ 2365450494 Bus1GeneratorFrequencyMatch 2528;
BA_ "SPN" SG_ 2365450494 Bus1GeneratorInSync 2529;
BA_ "SPN" SG_ 2365450494 Bus1GeneratorPhaseMatch 2526;
BA_ "SPN" SG_ 2365450494 Bus1GeneratorVoltageMatch 2527;
BA_ "SPN" SG_ 2365450750 Bs1PhsCLnNtrlACRMSVltg 2515;
BA_ "SPN" SG_ 2365450750 Bus1PhaseCACFrequency 2507;
BA_ "SPN" SG_ 2365450750 Bus1PhaseCALineLineACRMSVoltage 2511;
BA_ "SPN" SG_ 2365451006 Bs1PhsBLnNtrlACRMSVltg 2514;
BA_ "SPN" SG_ 2365451006 Bus1PhaseBACFrequency 2506;
BA_ "SPN" SG_ 2365451006 Bus1PhaseBCLineLineACRMSVoltage 2510;
BA_ "SPN" SG_ 2365451262 Bs1PhsALnNtrlACRMSVltg 2513;
BA_ "SPN" SG_ 2365451262 Bus1PhaseAACFrequency 2505;
BA_ "SPN" SG_ 2365451262 Bus1PhaseABLineLineACRMSVoltage 2509;
BA_ "SPN" SG_ 2365451518 Bs1AvrgLnNtrlACRMSVltg 2512;
BA_ "SPN" SG_ 2365451518 Bus1AverageACFrequency 2504;
BA_ "SPN" SG_ 2365451518 Bus1AverageLineLineACRMSVoltage 2508;
BA_ "SPN" SG_ 2365451774 UtilityTotalkWHoursExport 2502;
BA_ "SPN" SG_ 2365451774 UtilityTotalkWHoursImport 2503;
BA_ "SPN" SG_ 2365452030 UtilityPhaseCPowerFactor 2501;
BA_ "SPN" SG_ 2365452030 UtilityPhaseCPowerFactorLagging 2525;
BA_ "SPN" SG_ 2365452030 UtilityPhaseCReactivePower 2493;
BA_ "SPN" SG_ 2365452286 UtilityPhaseCApparentPower 2497;
BA_ "SPN" SG_ 2365452286 UtilityPhaseCRealPower 2489;
BA_ "SPN" SG_ 2365452542 UtilityPhaseCACFrequency 2473;
BA_ "SPN" SG_ 2365452542 UtilityPhaseCACRMSCurrent 2485;
BA_ "SPN" SG_ 2365452542 UtltPhsCALnLnACRMSVltg 2477;
BA_ "SPN" SG_ 2365452542 UtltPhsCLnNtrlACRMSVltg 2481;
BA_ "SPN" SG_ 2365452798 UtilityPhaseBPowerFactor 2500;
BA_ "SPN" SG_ 2365452798 UtilityPhaseBPowerFactorLagging 2524;
BA_ "SPN" SG_ 2365452798 UtilityPhaseBReactivePower 2492;
BA_ "SPN" SG_ 2365453054 UtilityPhaseBApparentPower 2496;
BA_ "SPN" SG_ 2365453054 UtilityPhaseBRealPower 2488;
BA_ "SPN" SG_ 2365453310 UtilityPhaseBACFrequency 2472;
BA_ "SPN" SG_ 2365453310 UtilityPhaseBACRMSCurrent 2484;
BA_ "SPN" SG_ 2365453310 UtltPhsBCLnLnACRMSVltg 2476;
BA_ "SPN" SG_ 2365453310 UtltPhsBLnNtrlACRMSVltg 2480;
BA_ "SPN" SG_ 2365453566 UtilityPhaseAPowerFactor 2499;
BA_ "SPN" SG_ 2365453566 UtilityPhaseAPowerFactorLagging 2523;
BA_ "SPN" SG_ 2365453566 UtilityPhaseAReactivePower 2491;
BA_ "SPN" SG_ 2365453822 UtilityPhaseAApparentPower 2495;
BA_ "SPN" SG_ 2365453822 UtilityPhaseARealPower 2487;
BA_ "SPN" SG_ 2365454078 UtilityPhaseAACFrequency 2471;
BA_ "SPN" SG_ 2365454078 UtilityPhaseAACRMSCurrent 2483;
BA_ "SPN" SG_ 2365454078 UtltPhsABLnLnACRMSVltg 2475;
BA_ "SPN" SG_ 2365454078 UtltPhsALnNtrlACRMSVltg 2479;
BA_ "SPN" SG_ 2365454334 UtilityOverallPowerFactor 2498;
BA_ "SPN" SG_ 2365454334 UtilityTotalReactivePower 2490;
BA_ "SPN" SG_ 2365454334 UtltOvrllPwrFtrLggng 2522;
BA_ "SPN" SG_ 2365454590 UtilityTotalApparentPower 2494;
BA_ "SPN" SG_ 2365454590 UtilityTotalRealPower 2486;
BA_ "SPN" SG_ 2365454846 UtilityAverageACFrequency 2470;
BA_ "SPN" SG_ 2365454846 UtilityAverageACRMSCurrent 2482;
BA_ "SPN" SG_ 2365454846 UtltAvrgLnLnACRMSVltg 2474;
BA_ "SPN" SG_ 2365454846 UtltAvrgLnNtrlACRMSVltg 2478;
BA_ "SPN" SG_ 2365455102 GeneratorTotalkWHoursExport 2468;
BA_ "SPN" SG_ 2365455102 GeneratorTotalkWHoursImport 2469;
BA_ "SPN" SG_ 2365455358 GeneratorPhaseCPowerFactor 2467;
BA_ "SPN" SG_ 2365455358 GeneratorPhaseCReactivePower 2459;
BA_ "SPN" SG_ 2365455358 GnrtrPhsCPwrFtrLggng 2521;
BA_ "SPN" SG_ 2365455614 GeneratorPhaseCApparentPower 2463;
BA_ "SPN" SG_ 2365455614 GeneratorPhaseCRealPower 2455;
BA_ "SPN" SG_ 2365455870 GeneratorPhaseCACFrequency 2439;
BA_ "SPN" SG_ 2365455870 GeneratorPhaseCACRMSCurrent 2451;
BA_ "SPN" SG_ 2365455870 GnrtrPhsCALnLnACRMSVltg 2443;
BA_ "SPN" SG_ 2365455870 GnrtrPhsCLnNtrlACRMSVltg 2447;
BA_ "SPN" SG_ 2365456126 GeneratorPhaseBPowerFactor 2466;
BA_ "SPN" SG_ 2365456126 GeneratorPhaseBReactivePower 2458;
BA_ "SPN" SG_ 2365456126 GnrtrPhsBPwrFtrLggng 2520;
BA_ "SPN" SG_ 2365456382 GeneratorPhaseBApparentPower 2462;
BA_ "SPN" SG_ 2365456382 GeneratorPhaseBRealPower 2454;
BA_ "SPN" SG_ 2365456894 GeneratorPhaseAPowerFactor 2465;
BA_ "SPN" SG_ 2365456894 GeneratorPhaseAReactivePower 2457;
BA_ "SPN" SG_ 2365456894 GnrtrPhsAPwrFtrLggng 2519;
BA_ "SPN" SG_ 2365457150 GeneratorPhaseAApparentPower 2461;
BA_ "SPN" SG_ 2365457150 GeneratorPhaseARealPower 2453;
BA_ "SPN" SG_ 2365457406 GeneratorPhaseAACFrequency 2437;
BA_ "SPN" SG_ 2365457406 GeneratorPhaseAACRMSCurrent 2449;
BA_ "SPN" SG_ 2365457406 GnrtrPhsABLnLnACRMSVltg 2441;
BA_ "SPN" SG_ 2365457406 GnrtrPhsALnNtrlACRMSVltg 2445;
BA_ "SPN" SG_ 2365457662 GeneratorOverallPowerFactor 2464;
BA_ "SPN" SG_ 2365457662 GeneratorTotalReactivePower 2456;
BA_ "SPN" SG_ 2365457662 GnrtrOvrllPwrFtrLggng 2518;
BA_ "SPN" SG_ 2365457918 GeneratorTotalApparentPower 2460;
BA_ "SPN" SG_ 2365457918 GeneratorTotalRealPower 2452;
BA_ "SPN" SG_ 2365458174 GeneratorAverageACFrequency 2436;
BA_ "SPN" SG_ 2365458174 GeneratorAverageACRMSCurrent 2448;
BA_ "SPN" SG_ 2365458174 GnrtrAvrgLnLnACRMSVltg 2440;
BA_ "SPN" SG_ 2365458174 GnrtrAvrgLnNtrlACRMSVltg 2444;
BA_ "SPN" SG_ 2365473278 AlternateBeamHeadLightCommand 2351;
BA_ "SPN" SG_ 2365473278 BackUpLightandAlarmHornCommand 2391;
BA_ "SPN" SG_ 2365473278 CenterStopLightCommand 2375;
BA_ "SPN" SG_ 2365473278 HighBeamHeadLightCommand 2347;
BA_ "SPN" SG_ 2365473278 ImplementClearanceLightCommand 2383;
BA_ "SPN" SG_ 2365473278 ImplementMarkerLightCommand 2379;
BA_ "SPN" SG_ 2365473278 ImplementOEMOption1LightCommand 2395;
BA_ "SPN" SG_ 2365473278 ImplementOEMOption2LightCommand 2397;
BA_ "SPN" SG_ 2365473278 ImplementRearWorkLightCommand 2405;
BA_ "SPN" SG_ 2365473278 ImplmntLftFngWrkLghtCmmnd 2399;
BA_ "SPN" SG_ 2365473278 ImplmntLftFrwrdWrkLghtCmmnd 2597;
BA_ "SPN" SG_ 2365473278 ImplmntRghtFngWrkLghtCmmnd 2406;
BA_ "SPN" SG_ 2365473278 ImplmntRghtFrwrdWrkLghtCmmnd 2401;
BA_ "SPN" SG_ 2365473278 LeftStopLightCommand 2371;
BA_ "SPN" SG_ 2365473278 LeftTurnSignalLightsCommand 2367;
BA_ "SPN" SG_ 2365473278 LightingDataRequestCommand 2393;
BA_ "SPN" SG_ 2365473278 LowBeamHeadLightCommand 2349;
BA_ "SPN" SG_ 2365473278 RearFogLightCommand 2389;
BA_ "SPN" SG_ 2365473278 RightStopLightCommand 2373;
BA_ "SPN" SG_ 2365473278 RightTurnSignalLightsCommand 2369;
BA_ "SPN" SG_ 2365473278 RotatingBeaconLightCommand 2385;
BA_ "SPN" SG_ 2365473278 RunningLightCommand 2403;
BA_ "SPN" SG_ 2365473278 TractorClearanceLightCommand 2381;
BA_ "SPN" SG_ 2365473278 TractorFrontFogLightsCommand 2387;
BA_ "SPN" SG_ 2365473278 TractorMarkerLightCommand 2377;
BA_ "SPN" SG_ 2365473278 TrtrFrntHghMntdWrkLghtsCmmnd 2355;
BA_ "SPN" SG_ 2365473278 TrtrFrntLwMntdWrkLghtsCmmnd 2353;
BA_ "SPN" SG_ 2365473278 TrtrRrHghMntdWrkLghtsCmmnd 2361;
BA_ "SPN" SG_ 2365473278 TrtrRrLwMntdWrkLghtsCmmnd 2359;
BA_ "SPN" SG_ 2365473278 TrtrSdHghMntdWrkLghtsCmmnd 2365;
BA_ "SPN" SG_ 2365473278 TrtrSdLwMntdWrkLghtsCmmnd 2363;
BA_ "SPN" SG_ 2365473278 TrtrUndrsdMntdWrkLghtsCmmnd 2357;
BA_ "SPN" SG_ 2365478910 DamperStiffnessFrontAxle 1729;
BA_ "SPN" SG_ 2365478910 DamperStiffnessLiftTagAxle 1731;
BA_ "SPN" SG_ 2365478910 DamperStiffnessRearAxle 1730;
BA_ "SPN" SG_ 2365478910 EltrnShkAsrrCntrlMdFrntAxl 1833;
BA_ "SPN" SG_ 2365478910 EltrnShkAsrrCntrlMdLftTgAxl 1831;
BA_ "SPN" SG_ 2365478910 EltrnShkAsrrCntrlMdRrAxl 1832;
BA_ "SPN" SG_ 2365479678 AboveNominalLevelFrontAxle 1737;
BA_ "SPN" SG_ 2365479678 AboveNominalLevelRearAxle 1736;
BA_ "SPN" SG_ 2365479678 AllwLvlCntrlDrngBrkngStts 5294;
BA_ "SPN" SG_ 2365479678 BelowNominalLevelFrontAxle 1738;
BA_ "SPN" SG_ 2365479678 BelowNominalLevelRearAxle 1754;
BA_ "SPN" SG_ 2365479678 DoorRelease 1744;
BA_ "SPN" SG_ 2365479678 FrontAxleinBumperRange 1824;
BA_ "SPN" SG_ 2365479678 KneelingInformation 1742;
BA_ "SPN" SG_ 2365479678 LevelControlMode 1741;
BA_ "SPN" SG_ 2365479678 LiftAxle1Position 1743;
BA_ "SPN" SG_ 2365479678 LiftAxle2Position 1822;
BA_ "SPN" SG_ 2365479678 LiftingControlModeFrontAxle 1739;
BA_ "SPN" SG_ 2365479678 LiftingControlModeRearAxle 1756;
BA_ "SPN" SG_ 2365479678 LoweringControlModeFrontAxle 1740;
BA_ "SPN" SG_ 2365479678 LoweringControlModeRearAxle 1755;
BA_ "SPN" SG_ 2365479678 Memorylevel 5432;
BA_ "SPN" SG_ 2365479678 NominalLevelFrontAxle 1734;
BA_ "SPN" SG_ 2365479678 NominalLevelRearAxle 1733;
BA_ "SPN" SG_ 2365479678 RearAxleinBumperRange 1823;
BA_ "SPN" SG_ 2365479678 SecurityDevice 1746;
BA_ "SPN" SG_ 2365479678 SpdDpndntLvlCntrlStts 5296;
BA_ "SPN" SG_ 2365479678 SspnsnCntrlRfslInfrmtn 1827;
BA_ "SPN" SG_ 2365479678 SuspensionRemoteControl1 1826;
BA_ "SPN" SG_ 2365479678 SuspensionRemotecontrol2 1825;
BA_ "SPN" SG_ 2365479678 VehicleMotionInhibit 1745;
BA_ "SPN" SG_ 2365484286 Directionindicator 1619;
BA_ "SPN" SG_ 2365484286 Driver1TimeRelatedStates 1617;
BA_ "SPN" SG_ 2365484286 Driver1workingstate 1612;
BA_ "SPN" SG_ 2365484286 Driver2TimeRelatedStates 1618;
BA_ "SPN" SG_ 2365484286 Driver2workingstate 1613;
BA_ "SPN" SG_ 2365484286 Drivercarddriver1 1615;
BA_ "SPN" SG_ 2365484286 Drivercarddriver2 1616;
BA_ "SPN" SG_ 2365484286 Handlinginformation 1621;
BA_ "SPN" SG_ 2365484286 Systemevent 1622;
BA_ "SPN" SG_ 2365484286 Tachographoutputshaftspeed 1623;
BA_ "SPN" SG_ 2365484286 Tachographperformance 1620;
BA_ "SPN" SG_ 2365484286 Tachographvehiclespeed 1624;
BA_ "SPN" SG_ 2365484286 Vehiclemotion 1611;
BA_ "SPN" SG_ 2365484286 VehicleOverspeed 1614;
BA_ "SPN" SG_ 2365485566 LaserTracerHorizontalDeviation 1581;
BA_ "SPN" SG_ 2365485566 LaserTracerInformation 1583;
BA_ "SPN" SG_ 2365485566 LaserTracerTargetDeviation 1579;
BA_ "SPN" SG_ 2365485566 LaserTracerVerticalDistance 1580;
BA_ "SPN" SG_ 2365485566 LEDDisplayData2 1582;
BA_ "SPN" SG_ 2365485822 BladeControlMode 1578;
BA_ "SPN" SG_ 2365485822 BladeControlModeLeft 5407;
BA_ "SPN" SG_ 2365485822 BladeControlModeRight 5408;
BA_ "SPN" SG_ 2365485822 BladeDurationandDirection 1577;
BA_ "SPN" SG_ 2365485822 LandLevelingSystemEnableStatus 5409;
BA_ "SPN" SG_ 2365486078 MastPosition 1576;
BA_ "SPN" SG_ 2365486334 BldHghtStPntHghRsltn 1759;
BA_ "SPN" SG_ 2365486334 ModifyLevelingSystemSetPoint 1575;
BA_ "SPN" SG_ 2365486590 AbsoluteLaserStrikePosition 2794;
BA_ "SPN" SG_ 2365486590 LaserReceiverType 2576;
BA_ "SPN" SG_ 2365486590 LaserStrikeDataLatency 2793;
BA_ "SPN" SG_ 2365486590 LaserStrikeVerticalDeviation 1574;
BA_ "SPN" SG_ 2431649790 DriverAlertnessWarning 7473;
BA_ "SPN" SG_ 2431649790 LaneDepartureImminentLeftSide 1700;
BA_ "SPN" SG_ 2431649790 LaneDepartureImminentRightSide 1701;
BA_ "SPN" SG_ 2431649790 LaneDepartureLeft 3565;
BA_ "SPN" SG_ 2431649790 LaneDepartureRight 3566;
BA_ "SPN" SG_ 2431649790 LftSdLnDprtrAstlWrnngCmmnd 8138;
BA_ "SPN" SG_ 2431649790 LftSdLnDprtrOptlWrnngCmmnd 8136;
BA_ "SPN" SG_ 2431649790 RghtSdLnDprtrAstlWrnngCmmnd 8137;
BA_ "SPN" SG_ 2431649790 RghtSdLnDprtrOptlWrnngCmmnd 8135;
BA_ "SPN" SG_ 2431649790 RghtSdLnDprtrHptWrnngCmmnd 9749;
BA_ "SPN" SG_ 2431649790 LftSdLnDprtrHptWrnngCmmnd 9750;
BA_ "SPN" SG_ 2431654654 EngnFlAttr1CntrlCmmnd 633;
BA_ "SPN" SG_ 2431654654 EngnFlAttr2CntrlCmmnd 1244;
BA_ "SPN" SG_ 2431654654 EngnThrttlAttr1CntrlCmmnd 3464;
BA_ "SPN" SG_ 2431654654 EngnThrttlAttr2CntrlCmmnd 3465;
BA_ "SPN" SG_ 2431661054 Aftrtrtmnt1SCRIntrmdtNH3 5848;
BA_ "SPN" SG_ 2431661054 Aftrtrtmnt1SCRIntrmdtNH3RdngStl 5850;
BA_ "SPN" SG_ 2431661054 Atttt1SCRItdtNH3SsHtCt 5854;
BA_ "SPN" SG_ 2431661054 Atttt1SCRItdtNH3SsHtPFMI 5853;
BA_ "SPN" SG_ 2431661054 Atttt1SCRItdtNH3SsPFMI 5849;
BA_ "SPN" SG_ 2431661054 Atttt1SCRItdtNH3SsPwIR 5851;
BA_ "SPN" SG_ 2431661054 Atttt1SCRItdtNH3SstTpt 5852;
BA_ "SPN" SG_ 2431661310 Aftrtrtmnt2SCRIntrmdtNH3 5855;
BA_ "SPN" SG_ 2431661310 Aftrtrtmnt2SCRIntrmdtNH3RdngStl 5857;
BA_ "SPN" SG_ 2431661310 Atttt2SCRItdtNH3SsHtCt 5861;
BA_ "SPN" SG_ 2431661310 Atttt2SCRItdtNH3SsHtPFMI 5860;
BA_ "SPN" SG_ 2431661310 Atttt2SCRItdtNH3SsPFMI 5856;
BA_ "SPN" SG_ 2431661310 Atttt2SCRItdtNH3SsPwIR 5858;
BA_ "SPN" SG_ 2431661310 Atttt2SCRItdtNH3SstTpt 5859;
BA_ "SPN" SG_ 2431708670 EngineStartAbortRequest 7747;
BA_ "SPN" SG_ 2431708670 EngineStartConsent 7746;
BA_ "SPN" SG_ 2431708670 EngineStartControlChecksum 7751;
BA_ "SPN" SG_ 2431708670 EngineStarter1Feedback 7748;
BA_ "SPN" SG_ 2431708670 EngineStarter2Feedback 7749;
BA_ "SPN" SG_ 2431708670 EngineStartRequest 7745;
BA_ "SPN" SG_ 2431708670 EngnStrtCntrlMssgCntr 7750;
BA_ "SPN" SG_ 2431708670 TrnsmssnShftSltrRqstdVhlDrtn 7788;
BA_ "SPN" SG_ 2431710718 AtmtEngnStrtCnsntSmmr 7756;
BA_ "SPN" SG_ 2431710718 EngineStartArbitratorChecksum 7758;
BA_ "SPN" SG_ 2431710718 EngineStartControlMessageRate 7752;
BA_ "SPN" SG_ 2431710718 EngineStarterCommand 7753;
BA_ "SPN" SG_ 2431710718 EngineStartRequestLatchStatus 7754;
BA_ "SPN" SG_ 2431710718 EngnStrtArtrtrMssgCntr 7757;
BA_ "SPN" SG_ 2431710718 OprtrEngnStrtCnsntSmmr 7755;
BA_ "SPN" SG_ 2431717886 EngnFlVlv1DffrntlPrssrHghRsltn 8494;
BA_ "SPN" SG_ 2431719166 WellStimulationPumpFlowRate 8650;
BA_ "SPN" SG_ 2431719166 WellStimulationPumpRodLoad 8648;
BA_ "SPN" SG_ 2431719166 WllStmltnPmpCvttnStts 8649;
BA_ "SPN" SG_ 2431719166 WllStmltnPmpFldEndVlvLk 8651;
BA_ "SPN" SG_ 2432471038 EngnFlVprzr1DshrgTmprtr 6610;
BA_ "SPN" SG_ 2432471038 EngnGssFlSpplPrssr1ExtnddRng 6646;
BA_ "SPN" SG_ 2432471038 GssFlAmltrTmprtr 6815;
BA_ "SPN" SG_ 2432471038 EGssFSppPssRtCtCd 9649;
BA_ "SPN" SG_ 2432492542 EngnExhstBrkAttrCmmnd 5543;
BA_ "SPN" SG_ 2432492542 EngnTrhrgr1TrnDsrdOtltPrssr 5542;
BA_ "SPN" SG_ 2432492542 EngnTrhrgr1TrnOtltPrssr 5541;
BA_ "SPN" SG_ 2432492542 EngnTrhrgr2TrnDsrdOtltPrssr 5545;
BA_ "SPN" SG_ 2432492542 EngnTrhrgr2TrnOtltPrssr 5544;
BA_ "SPN" SG_ 2432499198 CmmnddEngnFlInjtnCntrlPrssr 5314;
BA_ "SPN" SG_ 2432499198 CommandedEngineFuelRailPressure 5313;
BA_ "SPN" SG_ 2432499198 EngnExhstGsRrltn2Vlv2Pstn 5263;
BA_ "SPN" SG_ 2432499198 EngnExhstGsRrltn2VlvPstn 5262;
BA_ "SPN" SG_ 2432520702 AftrlrClntThrmsttMd 4198;
BA_ "SPN" SG_ 2432520702 DsrdAftrlrClntIntkTmprtr 4199;
BA_ "SPN" SG_ 2432520702 DsrdAftrlrClntThrmsttOpnng 4200;
BA_ "SPN" SG_ 2432520702 EngnChrgArClrBpssVlv1Cmmnd 7421;
BA_ "SPN" SG_ 2432520702 EngnChrgArClrBpssVlv2Cmmnd 7422;
BA_ "SPN" SG_ 2432520958 DsrdEngnClntPmpOtltTmprtr 4196;
BA_ "SPN" SG_ 2432520958 DsrdEngnClntThrmsttOpnng 4197;
BA_ "SPN" SG_ 2432520958 EngineCoolantThermostatMode 4195;
BA_ "SPN" SG_ 2432520958 EngnAxlrClrSpplVlv1AttrCmmnd 5546;
BA_ "SPN" SG_ 2432520958 EngnAxlrClrSpplVlv2AttrCmmnd 5547;
BA_ "SPN" SG_ 2432541438 EngineFuel1Temperature2 3468;
BA_ "SPN" SG_ 2432541438 EngnFlSstm2GsMssFlwRt 3467;
BA_ "SPN" SG_ 2432541438 EngnFlVlv2IntkAsltPrssr 3466;
BA_ "SPN" SG_ 2432541438 EngnFlVlv2OtltAsltPrssr 3469;
